VERSION ""

NS_ :

BS_:

BU_:

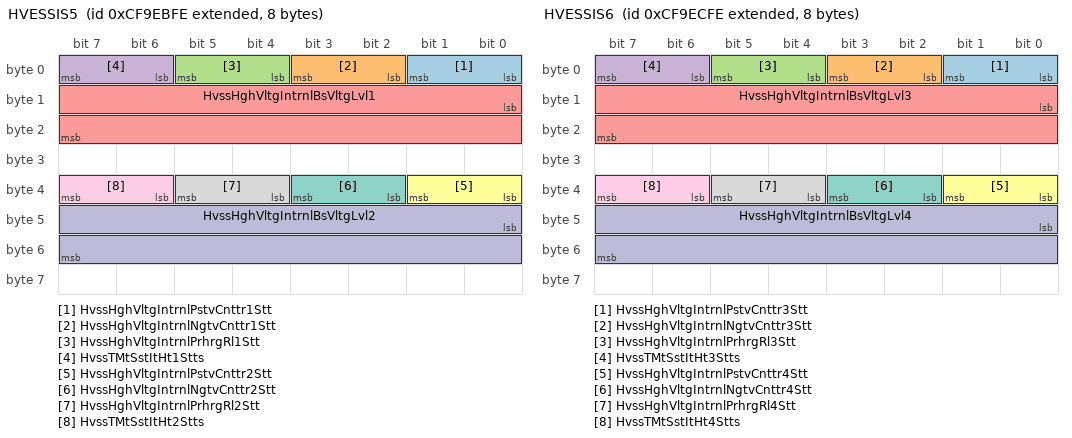
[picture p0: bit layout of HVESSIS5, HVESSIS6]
BO_ 2365189118 HVESSIS5: 8 Vector__XXX
 SG_ HvssHghVltgIntrnlPstvCnttr1Stt : 0|2@1+ (1,0) [0|3] "" Vector__XXX
 SG_ HvssHghVltgIntrnlNgtvCnttr1Stt : 2|2@1+ (1,0) [0|3] "" Vector__XXX
 SG_ HvssHghVltgIntrnlPrhrgRl1Stt : 4|2@1+ (1,0) [0|3] "" Vector__XXX
 SG_ HvssTMtSstItHt1Stts : 6|2@1+ (1,0) [0|3] "" Vector__XXX
 SG_ HvssHghVltgIntrnlBsVltgLvl1 : 8|16@1+ (0.05,0) [0|3212.75] "V" Vector__XXX
 SG_ HvssHghVltgIntrnlPstvCnttr2Stt : 32|2@1+ (1,0) [0|3] "" Vector__XXX
 SG_ HvssHghVltgIntrnlNgtvCnttr2Stt : 34|2@1+ (1,0) [0|3] "" Vector__XXX
 SG_ HvssHghVltgIntrnlPrhrgRl2Stt : 36|2@1+ (1,0) [0|3] "" Vector__XXX
 SG_ HvssTMtSstItHt2Stts : 38|2@1+ (1,0) [0|3] "" Vector__XXX
 SG_ HvssHghVltgIntrnlBsVltgLvl2 : 40|16@1+ (0.05,0) [0|3212.75] "V" Vector__XXX

BO_ 2365189374 HVESSIS6: 8 Vector__XXX
 SG_ HvssHghVltgIntrnlPstvCnttr3Stt : 0|2@1+ (1,0) [0|3] "" Vector__XXX
 SG_ HvssHghVltgIntrnlNgtvCnttr3Stt : 2|2@1+ (1,0) [0|3] "" Vector__XXX
 SG_ HvssHghVltgIntrnlPrhrgRl3Stt : 4|2@1+ (1,0) [0|3] "" Vector__XXX
 SG_ HvssTMtSstItHt3Stts : 6|2@1+ (1,0) [0|3] "" Vector__XXX
 SG_ HvssHghVltgIntrnlBsVltgLvl3 : 8|16@1+ (0.05,0) [0|3212.75] "V" Vector__XXX
 SG_ HvssHghVltgIntrnlPstvCnttr4Stt : 32|2@1+ (1,0) [0|3] "" Vector__XXX
 SG_ HvssHghVltgIntrnlNgtvCnttr4Stt : 34|2@1+ (1,0) [0|3] "" Vector__XXX
 SG_ HvssHghVltgIntrnlPrhrgRl4Stt : 36|2@1+ (1,0) [0|3] "" Vector__XXX
 SG_ HvssTMtSstItHt4Stts : 38|2@1+ (1,0) [0|3] "" Vector__XXX
 SG_ HvssHghVltgIntrnlBsVltgLvl4 : 40|16@1+ (0.05,0) [0|3212.75] "V" Vector__XXX

BO_ 2365189630 HVESSIS7: 8 Vector__XXX
 SG_ HvssNmrOfIntrnlCrtsRd : 0|8@1+ (1,0) [0|250] "count" Vector__XXX

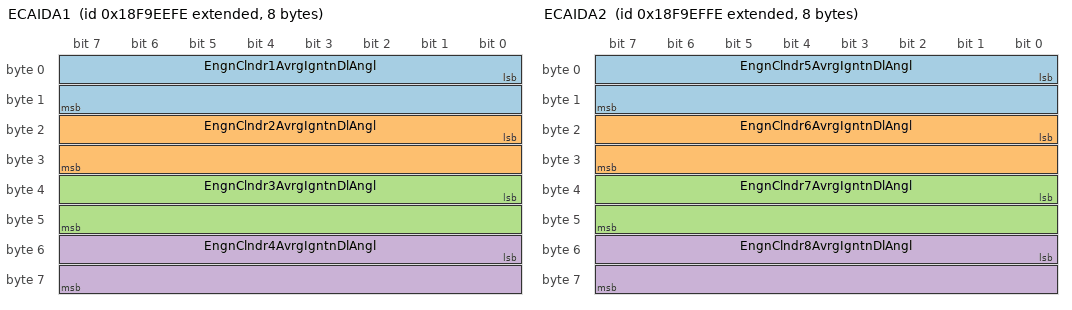
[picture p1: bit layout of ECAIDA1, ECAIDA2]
BO_ 2566516478 ECAIDA1: 8 Vector__XXX
 SG_ EngnClndr1AvrgIgntnDlAngl : 0|16@1+ (0.0078125,-200) [-200|301.9921875] "deg" Vector__XXX
 SG_ EngnClndr2AvrgIgntnDlAngl : 16|16@1+ (0.0078125,-200) [-200|301.9921875] "deg" Vector__XXX
 SG_ EngnClndr3AvrgIgntnDlAngl : 32|16@1+ (0.0078125,-200) [-200|301.9921875] "deg" Vector__XXX
 SG_ EngnClndr4AvrgIgntnDlAngl : 48|16@1+ (0.0078125,-200) [-200|301.9921875] "deg" Vector__XXX

BO_ 2566516734 ECAIDA2: 8 Vector__XXX
 SG_ EngnClndr5AvrgIgntnDlAngl : 0|16@1+ (0.0078125,-200) [-200|301.9921875] "deg" Vector__XXX
 SG_ EngnClndr6AvrgIgntnDlAngl : 16|16@1+ (0.0078125,-200) [-200|301.9921875] "deg" Vector__XXX
 SG_ EngnClndr7AvrgIgntnDlAngl : 32|16@1+ (0.0078125,-200) [-200|301.9921875] "deg" Vector__XXX
 SG_ EngnClndr8AvrgIgntnDlAngl : 48|16@1+ (0.0078125,-200) [-200|301.9921875] "deg" Vector__XXX

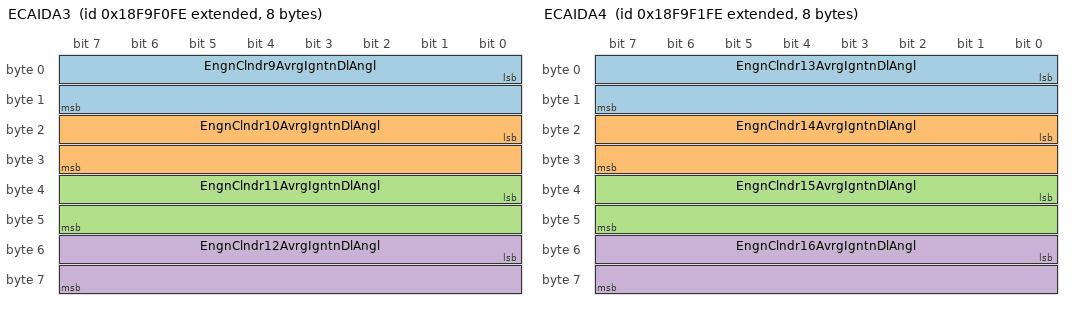
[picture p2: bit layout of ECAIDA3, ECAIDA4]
BO_ 2566516990 ECAIDA3: 8 Vector__XXX
 SG_ EngnClndr9AvrgIgntnDlAngl : 0|16@1+ (0.0078125,-200) [-200|301.9921875] "deg" Vector__XXX
 SG_ EngnClndr10AvrgIgntnDlAngl : 16|16@1+ (0.0078125,-200) [-200|301.9921875] "deg" Vector__XXX
 SG_ EngnClndr11AvrgIgntnDlAngl : 32|16@1+ (0.0078125,-200) [-200|301.9921875] "deg" Vector__XXX
 SG_ EngnClndr12AvrgIgntnDlAngl : 48|16@1+ (0.0078125,-200) [-200|301.9921875] "deg" Vector__XXX

BO_ 2566517246 ECAIDA4: 8 Vector__XXX
 SG_ EngnClndr13AvrgIgntnDlAngl : 0|16@1+ (0.0078125,-200) [-200|301.9921875] "deg" Vector__XXX
 SG_ EngnClndr14AvrgIgntnDlAngl : 16|16@1+ (0.0078125,-200) [-200|301.9921875] "deg" Vector__XXX
 SG_ EngnClndr15AvrgIgntnDlAngl : 32|16@1+ (0.0078125,-200) [-200|301.9921875] "deg" Vector__XXX
 SG_ EngnClndr16AvrgIgntnDlAngl : 48|16@1+ (0.0078125,-200) [-200|301.9921875] "deg" Vector__XXX

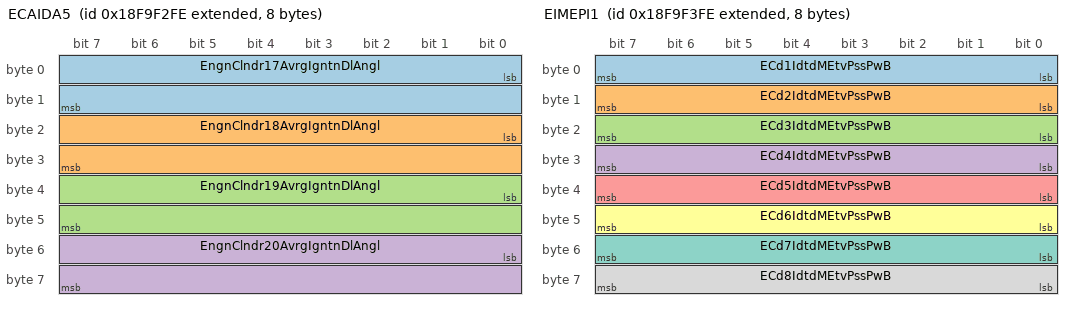
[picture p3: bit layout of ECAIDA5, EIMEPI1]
BO_ 2566517502 ECAIDA5: 8 Vector__XXX
 SG_ EngnClndr17AvrgIgntnDlAngl : 0|16@1+ (0.0078125,-200) [-200|301.9921875] "deg" Vector__XXX
 SG_ EngnClndr18AvrgIgntnDlAngl : 16|16@1+ (0.0078125,-200) [-200|301.9921875] "deg" Vector__XXX
 SG_ EngnClndr19AvrgIgntnDlAngl : 32|16@1+ (0.0078125,-200) [-200|301.9921875] "deg" Vector__XXX
 SG_ EngnClndr20AvrgIgntnDlAngl : 48|16@1+ (0.0078125,-200) [-200|301.9921875] "deg" Vector__XXX

BO_ 2566517758 EIMEPI1: 8 Vector__XXX
 SG_ ECd1IdtdMEtvPssPwB : 0|8@1+ (1,0) [0|250] "%" Vector__XXX
 SG_ ECd2IdtdMEtvPssPwB : 8|8@1+ (1,0) [0|250] "%" Vector__XXX
 SG_ ECd3IdtdMEtvPssPwB : 16|8@1+ (1,0) [0|250] "%" Vector__XXX
 SG_ ECd4IdtdMEtvPssPwB : 24|8@1+ (1,0) [0|250] "%" Vector__XXX
 SG_ ECd5IdtdMEtvPssPwB : 32|8@1+ (1,0) [0|250] "%" Vector__XXX
 SG_ ECd6IdtdMEtvPssPwB : 40|8@1+ (1,0) [0|250] "%" Vector__XXX
 SG_ ECd7IdtdMEtvPssPwB : 48|8@1+ (1,0) [0|250] "%" Vector__XXX
 SG_ ECd8IdtdMEtvPssPwB : 56|8@1+ (1,0) [0|250] "%" Vector__XXX

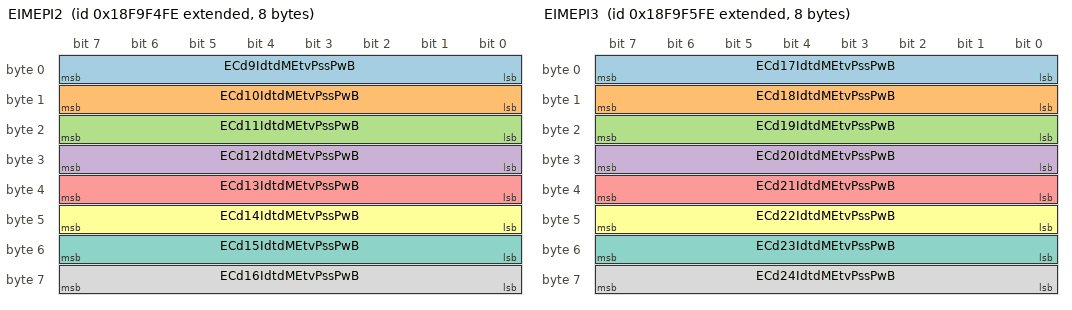
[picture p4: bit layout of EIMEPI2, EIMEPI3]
BO_ 2566518014 EIMEPI2: 8 Vector__XXX
 SG_ ECd9IdtdMEtvPssPwB : 0|8@1+ (1,0) [0|250] "%" Vector__XXX
 SG_ ECd10IdtdMEtvPssPwB : 8|8@1+ (1,0) [0|250] "%" Vector__XXX
 SG_ ECd11IdtdMEtvPssPwB : 16|8@1+ (1,0) [0|250] "%" Vector__XXX
 SG_ ECd12IdtdMEtvPssPwB : 24|8@1+ (1,0) [0|250] "%" Vector__XXX
 SG_ ECd13IdtdMEtvPssPwB : 32|8@1+ (1,0) [0|250] "%" Vector__XXX
 SG_ ECd14IdtdMEtvPssPwB : 40|8@1+ (1,0) [0|250] "%" Vector__XXX
 SG_ ECd15IdtdMEtvPssPwB : 48|8@1+ (1,0) [0|250] "%" Vector__XXX
 SG_ ECd16IdtdMEtvPssPwB : 56|8@1+ (1,0) [0|250] "%" Vector__XXX

BO_ 2566518270 EIMEPI3: 8 Vector__XXX
 SG_ ECd17IdtdMEtvPssPwB : 0|8@1+ (1,0) [0|250] "%" Vector__XXX
 SG_ ECd18IdtdMEtvPssPwB : 8|8@1+ (1,0) [0|250] "%" Vector__XXX
 SG_ ECd19IdtdMEtvPssPwB : 16|8@1+ (1,0) [0|250] "%" Vector__XXX
 SG_ ECd20IdtdMEtvPssPwB : 24|8@1+ (1,0) [0|250] "%" Vector__XXX
 SG_ ECd21IdtdMEtvPssPwB : 32|8@1+ (1,0) [0|250] "%" Vector__XXX
 SG_ ECd22IdtdMEtvPssPwB : 40|8@1+ (1,0) [0|250] "%" Vector__XXX
 SG_ ECd23IdtdMEtvPssPwB : 48|8@1+ (1,0) [0|250] "%" Vector__XXX
 SG_ ECd24IdtdMEtvPssPwB : 56|8@1+ (1,0) [0|250] "%" Vector__XXX

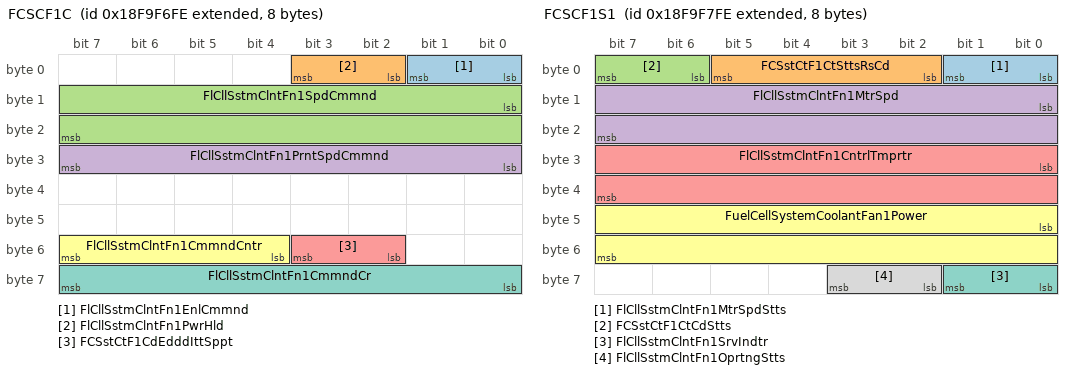
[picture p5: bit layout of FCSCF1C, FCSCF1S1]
BO_ 2566518526 FCSCF1C: 8 Vector__XXX
 SG_ FlCllSstmClntFn1EnlCmmnd : 0|2@1+ (1,0) [0|3] "" Vector__XXX
 SG_ FlCllSstmClntFn1PwrHld : 2|2@1+ (1,0) [0|3] "" Vector__XXX
 SG_ FlCllSstmClntFn1SpdCmmnd : 8|16@1+ (0.5,0) [0|32127.5] "rpm" Vector__XXX
 SG_ FlCllSstmClntFn1PrntSpdCmmnd : 24|8@1+ (0.5,0) [0|100] "%" Vector__XXX
 SG_ FCSstCtF1CdEdddIttSppt : 50|2@1+ (1,0) [0|3] "" Vector__XXX
 SG_ FlCllSstmClntFn1CmmndCntr : 52|4@1+ (1,0) [0|15] "count" Vector__XXX
 SG_ FlCllSstmClntFn1CmmndCr : 56|8@1+ (1,0) [0|250] "count" Vector__XXX

BO_ 2566518782 FCSCF1S1: 8 Vector__XXX
 SG_ FlCllSstmClntFn1MtrSpdStts : 0|2@1+ (1,0) [0|3] "" Vector__XXX
 SG_ FCSstCtF1CtSttsRsCd : 2|4@1+ (1,0) [0|15] "" Vector__XXX
 SG_ FCSstCtF1CtCdStts : 6|2@1+ (1,0) [0|3] "" Vector__XXX
 SG_ FlCllSstmClntFn1MtrSpd : 8|16@1+ (0.5,0) [0|32127.5] "rpm" Vector__XXX
 SG_ FlCllSstmClntFn1CntrlTmprtr : 24|16@1+ (0.03125,-273) [-273|1734.96875] "degC" Vector__XXX
 SG_ FuelCellSystemCoolantFan1Power : 40|16@1+ (0.5,0) [0|32127.5] "W" Vector__XXX
 SG_ FlCllSstmClntFn1SrvIndtr : 56|2@1+ (1,0) [0|3] "" Vector__XXX
 SG_ FlCllSstmClntFn1OprtngStts : 58|2@1+ (1,0) [0|3] "" Vector__XXX

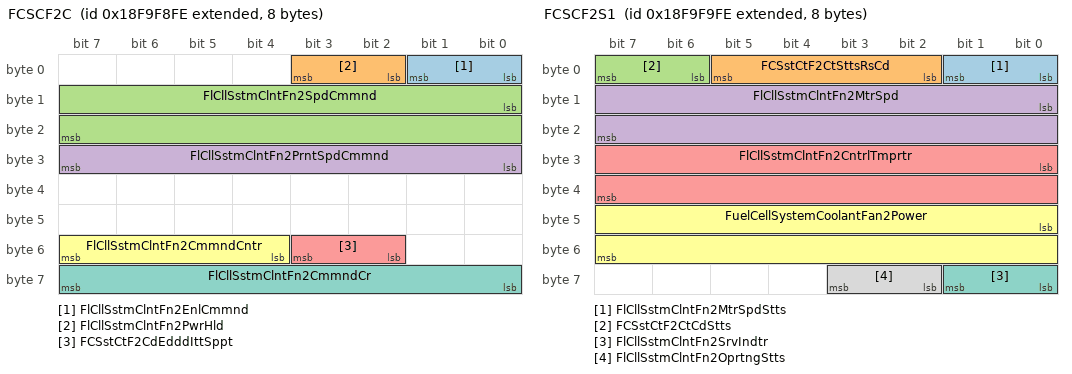
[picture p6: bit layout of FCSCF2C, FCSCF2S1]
BO_ 2566519038 FCSCF2C: 8 Vector__XXX
 SG_ FlCllSstmClntFn2EnlCmmnd : 0|2@1+ (1,0) [0|3] "" Vector__XXX
 SG_ FlCllSstmClntFn2PwrHld : 2|2@1+ (1,0) [0|3] "" Vector__XXX
 SG_ FlCllSstmClntFn2SpdCmmnd : 8|16@1+ (0.5,0) [0|32127.5] "rpm" Vector__XXX
 SG_ FlCllSstmClntFn2PrntSpdCmmnd : 24|8@1+ (0.5,0) [0|100] "%" Vector__XXX
 SG_ FCSstCtF2CdEdddIttSppt : 50|2@1+ (1,0) [0|3] "" Vector__XXX
 SG_ FlCllSstmClntFn2CmmndCntr : 52|4@1+ (1,0) [0|15] "count" Vector__XXX
 SG_ FlCllSstmClntFn2CmmndCr : 56|8@1+ (1,0) [0|250] "count" Vector__XXX

BO_ 2566519294 FCSCF2S1: 8 Vector__XXX
 SG_ FlCllSstmClntFn2MtrSpdStts : 0|2@1+ (1,0) [0|3] "" Vector__XXX
 SG_ FCSstCtF2CtSttsRsCd : 2|4@1+ (1,0) [0|15] "" Vector__XXX
 SG_ FCSstCtF2CtCdStts : 6|2@1+ (1,0) [0|3] "" Vector__XXX
 SG_ FlCllSstmClntFn2MtrSpd : 8|16@1+ (0.5,0) [0|32127.5] "rpm" Vector__XXX
 SG_ FlCllSstmClntFn2CntrlTmprtr : 24|16@1+ (0.03125,-273) [-273|1734.96875] "degC" Vector__XXX
 SG_ FuelCellSystemCoolantFan2Power : 40|16@1+ (0.5,0) [0|32127.5] "W" Vector__XXX
 SG_ FlCllSstmClntFn2SrvIndtr : 56|2@1+ (1,0) [0|3] "" Vector__XXX
 SG_ FlCllSstmClntFn2OprtngStts : 58|2@1+ (1,0) [0|3] "" Vector__XXX

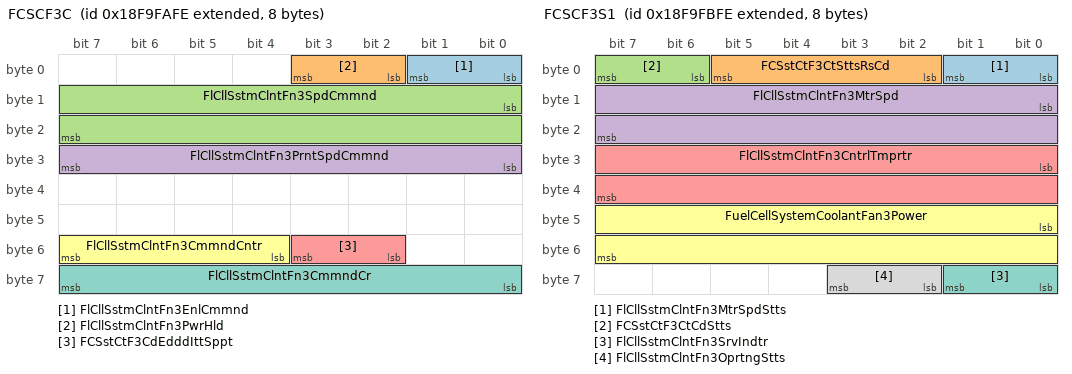
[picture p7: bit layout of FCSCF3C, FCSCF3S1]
BO_ 2566519550 FCSCF3C: 8 Vector__XXX
 SG_ FlCllSstmClntFn3EnlCmmnd : 0|2@1+ (1,0) [0|3] "" Vector__XXX
 SG_ FlCllSstmClntFn3PwrHld : 2|2@1+ (1,0) [0|3] "" Vector__XXX
 SG_ FlCllSstmClntFn3SpdCmmnd : 8|16@1+ (0.5,0) [0|32127.5] "rpm" Vector__XXX
 SG_ FlCllSstmClntFn3PrntSpdCmmnd : 24|8@1+ (0.5,0) [0|100] "%" Vector__XXX
 SG_ FCSstCtF3CdEdddIttSppt : 50|2@1+ (1,0) [0|3] "" Vector__XXX
 SG_ FlCllSstmClntFn3CmmndCntr : 52|4@1+ (1,0) [0|15] "count" Vector__XXX
 SG_ FlCllSstmClntFn3CmmndCr : 56|8@1+ (1,0) [0|250] "count" Vector__XXX

BO_ 2566519806 FCSCF3S1: 8 Vector__XXX
 SG_ FlCllSstmClntFn3MtrSpdStts : 0|2@1+ (1,0) [0|3] "" Vector__XXX
 SG_ FCSstCtF3CtSttsRsCd : 2|4@1+ (1,0) [0|15] "" Vector__XXX
 SG_ FCSstCtF3CtCdStts : 6|2@1+ (1,0) [0|3] "" Vector__XXX
 SG_ FlCllSstmClntFn3MtrSpd : 8|16@1+ (0.5,0) [0|32127.5] "rpm" Vector__XXX
 SG_ FlCllSstmClntFn3CntrlTmprtr : 24|16@1+ (0.03125,-273) [-273|1734.96875] "degC" Vector__XXX
 SG_ FuelCellSystemCoolantFan3Power : 40|16@1+ (0.5,0) [0|32127.5] "W" Vector__XXX
 SG_ FlCllSstmClntFn3SrvIndtr : 56|2@1+ (1,0) [0|3] "" Vector__XXX
 SG_ FlCllSstmClntFn3OprtngStts : 58|2@1+ (1,0) [0|3] "" Vector__XXX

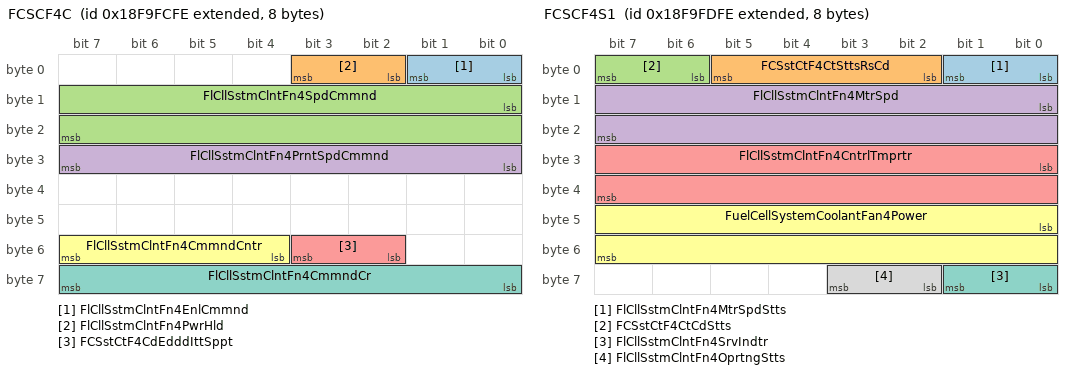
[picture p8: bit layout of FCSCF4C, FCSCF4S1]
BO_ 2566520062 FCSCF4C: 8 Vector__XXX
 SG_ FlCllSstmClntFn4EnlCmmnd : 0|2@1+ (1,0) [0|3] "" Vector__XXX
 SG_ FlCllSstmClntFn4PwrHld : 2|2@1+ (1,0) [0|3] "" Vector__XXX
 SG_ FlCllSstmClntFn4SpdCmmnd : 8|16@1+ (0.5,0) [0|32127.5] "rpm" Vector__XXX
 SG_ FlCllSstmClntFn4PrntSpdCmmnd : 24|8@1+ (0.5,0) [0|100] "%" Vector__XXX
 SG_ FCSstCtF4CdEdddIttSppt : 50|2@1+ (1,0) [0|3] "" Vector__XXX
 SG_ FlCllSstmClntFn4CmmndCntr : 52|4@1+ (1,0) [0|15] "count" Vector__XXX
 SG_ FlCllSstmClntFn4CmmndCr : 56|8@1+ (1,0) [0|250] "count" Vector__XXX

BO_ 2566520318 FCSCF4S1: 8 Vector__XXX
 SG_ FlCllSstmClntFn4MtrSpdStts : 0|2@1+ (1,0) [0|3] "" Vector__XXX
 SG_ FCSstCtF4CtSttsRsCd : 2|4@1+ (1,0) [0|15] "" Vector__XXX
 SG_ FCSstCtF4CtCdStts : 6|2@1+ (1,0) [0|3] "" Vector__XXX
 SG_ FlCllSstmClntFn4MtrSpd : 8|16@1+ (0.5,0) [0|32127.5] "rpm" Vector__XXX
 SG_ FlCllSstmClntFn4CntrlTmprtr : 24|16@1+ (0.03125,-273) [-273|1734.96875] "degC" Vector__XXX
 SG_ FuelCellSystemCoolantFan4Power : 40|16@1+ (0.5,0) [0|32127.5] "W" Vector__XXX
 SG_ FlCllSstmClntFn4SrvIndtr : 56|2@1+ (1,0) [0|3] "" Vector__XXX
 SG_ FlCllSstmClntFn4OprtngStts : 58|2@1+ (1,0) [0|3] "" Vector__XXX

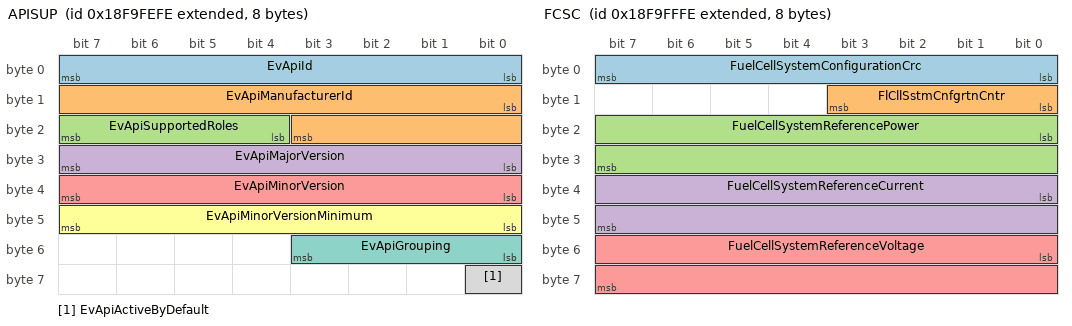
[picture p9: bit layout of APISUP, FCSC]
BO_ 2566520574 APISUP: 8 Vector__XXX
 SG_ EvApiId : 0|8@1+ (1,0) [0|250] "count" Vector__XXX
 SG_ EvApiManufacturerId : 8|12@1+ (1,0) [0|4015] "count" Vector__XXX
 SG_ EvApiSupportedRoles : 20|4@1+ (1,0) [0|15] "" Vector__XXX
 SG_ EvApiMajorVersion : 24|8@1+ (1,0) [0|250] "count" Vector__XXX
 SG_ EvApiMinorVersion : 32|8@1+ (1,0) [0|250] "count" Vector__XXX
 SG_ EvApiMinorVersionMinimum : 40|8@1+ (1,0) [0|250] "count" Vector__XXX
 SG_ EvApiGrouping : 48|4@1+ (1,0) [0|15] "" Vector__XXX
 SG_ EvApiActiveByDefault : 56|1@1+ (1,0) [0|1] "" Vector__XXX

BO_ 2566520830 FCSC: 8 Vector__XXX
 SG_ FuelCellSystemConfigurationCrc : 0|8@1+ (1,0) [0|250] "count" Vector__XXX
 SG_ FlCllSstmCnfgrtnCntr : 8|4@1+ (1,0) [0|15] "" Vector__XXX
 SG_ FuelCellSystemReferencePower : 16|16@1+ (0.05,0) [0|3212.75] "kW" Vector__XXX
 SG_ FuelCellSystemReferenceCurrent : 32|16@1+ (0.05,0) [0|3212.75] "A" Vector__XXX
 SG_ FuelCellSystemReferenceVoltage : 48|16@1+ (0.05,0) [0|3212.75] "V" Vector__XXX

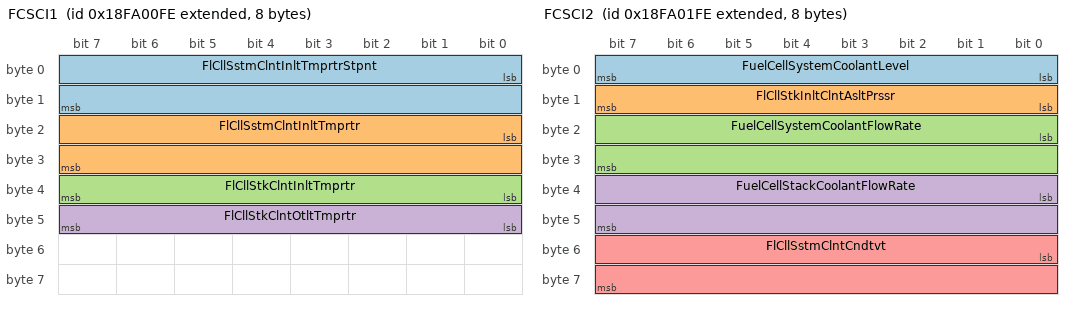
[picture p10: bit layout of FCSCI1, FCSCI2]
BO_ 2566521086 FCSCI1: 8 Vector__XXX
 SG_ FlCllSstmClntInltTmprtrStpnt : 0|16@1+ (0.03125,-273) [-273|1734.96875] "degC" Vector__XXX
 SG_ FlCllSstmClntInltTmprtr : 16|16@1+ (0.03125,-273) [-273|1734.96875] "degC" Vector__XXX
 SG_ FlCllStkClntInltTmprtr : 32|8@1+ (1,-40) [-40|210] "degC" Vector__XXX
 SG_ FlCllStkClntOtltTmprtr : 40|8@1+ (1,-40) [-40|210] "degC" Vector__XXX

BO_ 2566521342 FCSCI2: 8 Vector__XXX
 SG_ FuelCellSystemCoolantLevel : 0|8@1+ (0.4,0) [0|100] "%" Vector__XXX
 SG_ FlCllStkInltClntAsltPrssr : 8|8@1+ (2,0) [0|500] "kPa" Vector__XXX
 SG_ FuelCellSystemCoolantFlowRate : 16|16@1+ (0.05,0) [0|3212.75] "l/h" Vector__XXX
 SG_ FuelCellStackCoolantFlowRate : 32|16@1+ (0.05,0) [0|3212.75] "l/h" Vector__XXX
 SG_ FlCllSstmClntCndtvt : 48|16@1+ (0.02,0) [0|1285.1] "micro Siemens/cm" Vector__XXX

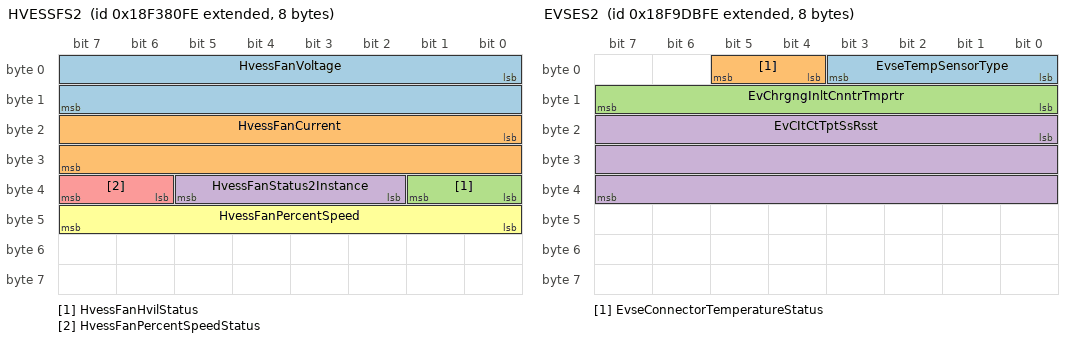
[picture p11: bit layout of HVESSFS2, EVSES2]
BO_ 2566095102 HVESSFS2: 8 Vector__XXX
 SG_ HvessFanVoltage : 0|16@1+ (0.05,0) [0|3212.75] "V" Vector__XXX
 SG_ HvessFanCurrent : 16|16@1+ (0.05,-1600) [-1600|1612.75] "A" Vector__XXX
 SG_ HvessFanHvilStatus : 32|2@1+ (1,0) [0|3] "" Vector__XXX
 SG_ HvessFanStatus2Instance : 34|4@1+ (1,0) [0|15] "" Vector__XXX
 SG_ HvessFanPercentSpeedStatus : 38|2@1+ (1,0) [0|3] "" Vector__XXX
 SG_ HvessFanPercentSpeed : 40|8@1+ (0.5,0) [0|125] "%" Vector__XXX

BO_ 2566511614 EVSES2: 8 Vector__XXX
 SG_ EvseTempSensorType : 0|4@1+ (1,0) [0|15] "" Vector__XXX
 SG_ EvseConnectorTemperatureStatus : 4|2@1+ (1,0) [0|3] "" Vector__XXX
 SG_ EvChrgngInltCnntrTmprtr : 8|8@1+ (1,-40) [-40|210] "degC" Vector__XXX
 SG_ EvCItCtTptSsRsst : 16|24@1+ (1,0) [0|16449535] "ohm" Vector__XXX

BO_ 2566645502 HVESSFC: 8 Vector__XXX
 SG_ HvessFanEnableCommand : 0|2@1+ (1,0) [0|3] "" Vector__XXX
 SG_ HvessFanPowerHold : 2|2@1+ (1,0) [0|3] "" Vector__XXX
 SG_ HvessFanSpeedCommand : 8|16@1+ (0.5,0) [0|32127.5] "rpm" Vector__XXX
 SG_ HvessFanPercentSpeedCommand : 24|8@1+ (0.4,0) [0|100] "%" Vector__XXX
 SG_ HvessFanInstance1 : 32|1@1+ (1,0) [0|1] "" Vector__XXX
 SG_ HvessFanInstance2 : 33|1@1+ (1,0) [0|1] "" Vector__XXX
 SG_ HvessFanInstance3 : 34|1@1+ (1,0) [0|1] "" Vector__XXX
 SG_ HvessFanInstance4 : 35|1@1+ (1,0) [0|1] "" Vector__XXX
 SG_ HvessFanInstance5 : 36|1@1+ (1,0) [0|1] "" Vector__XXX
 SG_ HvessFanInstance6 : 37|1@1+ (1,0) [0|1] "" Vector__XXX
 SG_ HvessFanInstance7 : 38|1@1+ (1,0) [0|1] "" Vector__XXX
 SG_ HvessFanInstance8 : 39|1@1+ (1,0) [0|1] "" Vector__XXX
 SG_ HvessFanInstance9 : 40|1@1+ (1,0) [0|1] "" Vector__XXX
 SG_ HvessFanInstance10 : 41|1@1+ (1,0) [0|1] "" Vector__XXX
 SG_ HvessFanInstance11 : 42|1@1+ (1,0) [0|1] "" Vector__XXX
 SG_ HvessFanInstance12 : 43|1@1+ (1,0) [0|1] "" Vector__XXX
 SG_ HvessFanInstance13 : 44|1@1+ (1,0) [0|1] "" Vector__XXX
 SG_ HvessFanInstance14 : 45|1@1+ (1,0) [0|1] "" Vector__XXX
 SG_ HvessFanInstance15 : 46|1@1+ (1,0) [0|1] "" Vector__XXX
 SG_ HVtEStSstFCdsEdddIttSppt : 50|2@1+ (1,0) [0|3] "" Vector__XXX
 SG_ HghVltgEnrgStrgSstmFnCmmndsCntr : 52|4@1+ (1,0) [0|15] "count" Vector__XXX
 SG_ HghVltgEnrgStrgSstmFnCmmndsCr : 56|8@1+ (1,0) [0|250] "count" Vector__XXX

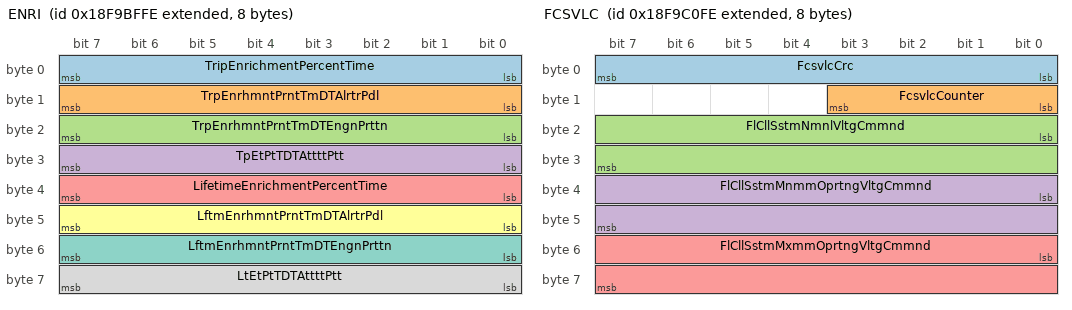
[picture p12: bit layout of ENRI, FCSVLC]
BO_ 2566504446 ENRI: 8 Vector__XXX
 SG_ TripEnrichmentPercentTime : 0|8@1+ (0.5,0) [0|125] "%" Vector__XXX
 SG_ TrpEnrhmntPrntTmDTAlrtrPdl : 8|8@1+ (0.5,0) [0|125] "%" Vector__XXX
 SG_ TrpEnrhmntPrntTmDTEngnPrttn : 16|8@1+ (0.5,0) [0|125] "%" Vector__XXX
 SG_ TpEtPtTDTAttttPtt : 24|8@1+ (0.5,0) [0|125] "%" Vector__XXX
 SG_ LifetimeEnrichmentPercentTime : 32|8@1+ (0.5,0) [0|125] "%" Vector__XXX
 SG_ LftmEnrhmntPrntTmDTAlrtrPdl : 40|8@1+ (0.5,0) [0|125] "%" Vector__XXX
 SG_ LftmEnrhmntPrntTmDTEngnPrttn : 48|8@1+ (0.5,0) [0|125] "%" Vector__XXX
 SG_ LtEtPtTDTAttttPtt : 56|8@1+ (0.5,0) [0|125] "%" Vector__XXX

BO_ 2566504702 FCSVLC: 8 Vector__XXX
 SG_ FcsvlcCrc : 0|8@1+ (1,0) [0|250] "count" Vector__XXX
 SG_ FcsvlcCounter : 8|4@1+ (1,0) [0|15] "" Vector__XXX
 SG_ FlCllSstmNmnlVltgCmmnd : 16|16@1+ (0.00390625,-125) [0|125.99609375] "%" Vector__XXX
 SG_ FlCllSstmMnmmOprtngVltgCmmnd : 32|16@1+ (0.00390625,-125) [0|125.99609375] "%" Vector__XXX
 SG_ FlCllSstmMxmmOprtngVltgCmmnd : 48|16@1+ (0.00390625,-125) [0|125.99609375] "%" Vector__XXX

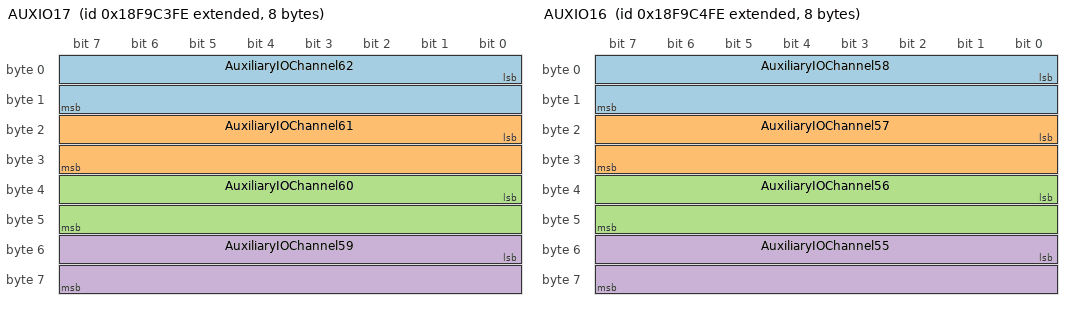
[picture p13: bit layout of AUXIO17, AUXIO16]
BO_ 2566505470 AUXIO17: 8 Vector__XXX
 SG_ AuxiliaryIOChannel62 : 0|16@1+ (1,0) [0|64255] "count" Vector__XXX
 SG_ AuxiliaryIOChannel61 : 16|16@1+ (1,0) [0|64255] "count" Vector__XXX
 SG_ AuxiliaryIOChannel60 : 32|16@1+ (1,0) [0|64255] "count" Vector__XXX
 SG_ AuxiliaryIOChannel59 : 48|16@1+ (1,0) [0|64255] "count" Vector__XXX

BO_ 2566505726 AUXIO16: 8 Vector__XXX
 SG_ AuxiliaryIOChannel58 : 0|16@1+ (1,0) [0|64255] "count" Vector__XXX
 SG_ AuxiliaryIOChannel57 : 16|16@1+ (1,0) [0|64255] "count" Vector__XXX
 SG_ AuxiliaryIOChannel56 : 32|16@1+ (1,0) [0|64255] "count" Vector__XXX
 SG_ AuxiliaryIOChannel55 : 48|16@1+ (1,0) [0|64255] "count" Vector__XXX

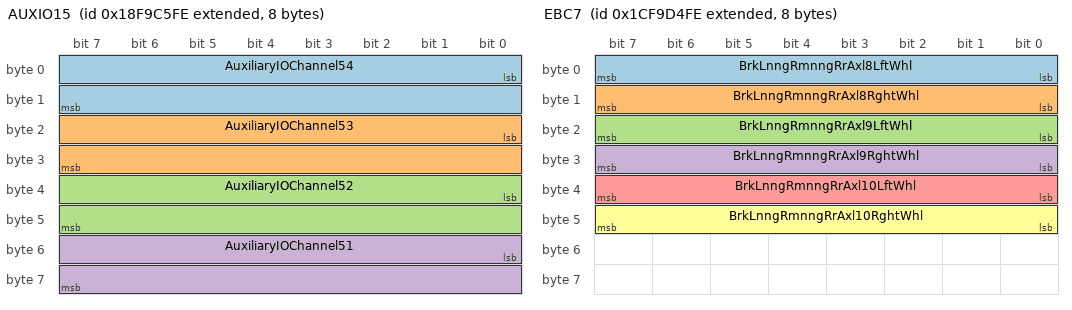
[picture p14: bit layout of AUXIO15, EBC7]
BO_ 2566505982 AUXIO15: 8 Vector__XXX
 SG_ AuxiliaryIOChannel54 : 0|16@1+ (1,0) [0|64255] "count" Vector__XXX
 SG_ AuxiliaryIOChannel53 : 16|16@1+ (1,0) [0|64255] "count" Vector__XXX
 SG_ AuxiliaryIOChannel52 : 32|16@1+ (1,0) [0|64255] "count" Vector__XXX
 SG_ AuxiliaryIOChannel51 : 48|16@1+ (1,0) [0|64255] "count" Vector__XXX

BO_ 2566506238 AUXIO14: 8 Vector__XXX
 SG_ AuxiliaryIOChannel50 : 0|16@1+ (1,0) [0|64255] "count" Vector__XXX
 SG_ AuxiliaryIOChannel49 : 16|16@1+ (1,0) [0|64255] "count" Vector__XXX
 SG_ AuxiliaryIOChannel48 : 32|16@1+ (1,0) [0|64255] "count" Vector__XXX
 SG_ AuxiliaryIOChannel47 : 48|16@1+ (1,0) [0|64255] "count" Vector__XXX

BO_ 2566506494 AUXIO13: 8 Vector__XXX
 SG_ AuxiliaryIOChannel46 : 0|16@1+ (1,0) [0|64255] "count" Vector__XXX
 SG_ AuxiliaryIOChannel45 : 16|16@1+ (1,0) [0|64255] "count" Vector__XXX
 SG_ AuxiliaryIOChannel44 : 32|16@1+ (1,0) [0|64255] "count" Vector__XXX
 SG_ AuxiliaryIOChannel43 : 48|16@1+ (1,0) [0|64255] "count" Vector__XXX

BO_ 2566506750 AUXIO12: 8 Vector__XXX
 SG_ AuxiliaryIOChannel42 : 0|16@1+ (1,0) [0|64255] "count" Vector__XXX
 SG_ AuxiliaryIOChannel41 : 16|16@1+ (1,0) [0|64255] "count" Vector__XXX
 SG_ AuxiliaryIOChannel40 : 32|16@1+ (1,0) [0|64255] "count" Vector__XXX
 SG_ AuxiliaryIOChannel39 : 48|16@1+ (1,0) [0|64255] "count" Vector__XXX

BO_ 2566507006 AUXIO11: 8 Vector__XXX
 SG_ AuxiliaryIOChannel38 : 0|16@1+ (1,0) [0|64255] "count" Vector__XXX
 SG_ AuxiliaryIOChannel37 : 16|16@1+ (1,0) [0|64255] "count" Vector__XXX
 SG_ AuxiliaryIOChannel36 : 32|16@1+ (1,0) [0|64255] "count" Vector__XXX
 SG_ AuxiliaryIOChannel35 : 48|16@1+ (1,0) [0|64255] "count" Vector__XXX

BO_ 2566507262 AUXIO10: 8 Vector__XXX
 SG_ AuxiliaryIOChannel34 : 0|16@1+ (1,0) [0|64255] "count" Vector__XXX
 SG_ AuxiliaryIOChannel33 : 16|16@1+ (1,0) [0|64255] "count" Vector__XXX
 SG_ AuxiliaryIOChannel32 : 32|16@1+ (1,0) [0|64255] "count" Vector__XXX
 SG_ AuxiliaryIOChannel31 : 48|16@1+ (1,0) [0|64255] "count" Vector__XXX

BO_ 2566507518 AUXIO9: 8 Vector__XXX
 SG_ AuxiliaryIOChannel30 : 0|16@1+ (1,0) [0|64255] "count" Vector__XXX
 SG_ AuxiliaryIOChannel29 : 16|16@1+ (1,0) [0|64255] "count" Vector__XXX
 SG_ AuxiliaryIOChannel28 : 32|16@1+ (1,0) [0|64255] "count" Vector__XXX
 SG_ AuxiliaryIOChannel27 : 48|16@1+ (1,0) [0|64255] "count" Vector__XXX

BO_ 2566507774 AUXIO8: 8 Vector__XXX
 SG_ AuxiliaryIOChannel26 : 0|16@1+ (1,0) [0|64255] "count" Vector__XXX
 SG_ AuxiliaryIOChannel25 : 16|16@1+ (1,0) [0|64255] "count" Vector__XXX
 SG_ AuxiliaryIOChannel24 : 32|16@1+ (1,0) [0|64255] "count" Vector__XXX
 SG_ AuxiliaryIOChannel23 : 48|16@1+ (1,0) [0|64255] "count" Vector__XXX

BO_ 2633616894 ASI8: 8 Vector__XXX
 SG_ AftrtrtmntDslExhstFldEnm : 0|16@1+ (0.015625,0) [0|1003.984375] "km/L" Vector__XXX
 SG_ AftrtrtmntDslExhstFldLftmEnm : 16|16@1+ (0.015625,0) [0|1003.984375] "km/L" Vector__XXX

BO_ 2566508286 BKT6: 8 Vector__XXX
 SG_ BrkTmprtrRrAxl10LftWhl : 0|16@1+ (0.03125,-273) [-273|1734.96875] "degC" Vector__XXX
 SG_ BrkTmprtrRrAxl10RghtWhl : 16|16@1+ (0.03125,-273) [-273|1734.96875] "degC" Vector__XXX

BO_ 2566508542 BKT5: 8 Vector__XXX
 SG_ BrkTmprtrRrAxl8LftWhl : 0|16@1+ (0.03125,-273) [-273|1734.96875] "degC" Vector__XXX
 SG_ BrkTmprtrRrAxl8RghtWhl : 16|16@1+ (0.03125,-273) [-273|1734.96875] "degC" Vector__XXX
 SG_ BrkTmprtrRrAxl9LftWhl : 32|16@1+ (0.03125,-273) [-273|1734.96875] "degC" Vector__XXX
 SG_ BrkTmprtrRrAxl9RghtWhl : 48|16@1+ (0.03125,-273) [-273|1734.96875] "degC" Vector__XXX

BO_ 2566508798 BKT4: 8 Vector__XXX
 SG_ BrkTmprtrRrAxl6LftWhl : 0|16@1+ (0.03125,-273) [-273|1734.96875] "degC" Vector__XXX
 SG_ BrkTmprtrRrAxl6RghtWhl : 16|16@1+ (0.03125,-273) [-273|1734.96875] "degC" Vector__XXX
 SG_ BrkTmprtrRrAxl7LftWhl : 32|16@1+ (0.03125,-273) [-273|1734.96875] "degC" Vector__XXX
 SG_ BrkTmprtrRrAxl7RghtWhl : 48|16@1+ (0.03125,-273) [-273|1734.96875] "degC" Vector__XXX

BO_ 2566509054 BKT3: 8 Vector__XXX
 SG_ BrkTmprtrRrAxl4LftWhl : 0|16@1+ (0.03125,-273) [-273|1734.96875] "degC" Vector__XXX
 SG_ BrkTmprtrRrAxl4RghtWhl : 16|16@1+ (0.03125,-273) [-273|1734.96875] "degC" Vector__XXX
 SG_ BrkTmprtrRrAxl5LftWhl : 32|16@1+ (0.03125,-273) [-273|1734.96875] "degC" Vector__XXX
 SG_ BrkTmprtrRrAxl5RghtWhl : 48|16@1+ (0.03125,-273) [-273|1734.96875] "degC" Vector__XXX

BO_ 2566509310 BKT2: 8 Vector__XXX
 SG_ BrkTmprtrRrAxl2LftWhl : 0|16@1+ (0.03125,-273) [-273|1734.96875] "degC" Vector__XXX
 SG_ BrkTmprtrRrAxl2RghtWhl : 16|16@1+ (0.03125,-273) [-273|1734.96875] "degC" Vector__XXX
 SG_ BrkTmprtrRrAxl3LftWhl : 32|16@1+ (0.03125,-273) [-273|1734.96875] "degC" Vector__XXX
 SG_ BrkTmprtrRrAxl3RghtWhl : 48|16@1+ (0.03125,-273) [-273|1734.96875] "degC" Vector__XXX

BO_ 2566509566 BKT1: 8 Vector__XXX
 SG_ BrkTmprtrFrntAxlLftWhl : 0|16@1+ (0.03125,-273) [-273|1734.96875] "degC" Vector__XXX
 SG_ BrkTmprtrFrntAxlRghtWhl : 16|16@1+ (0.03125,-273) [-273|1734.96875] "degC" Vector__XXX
 SG_ BrkTmprtrRrAxl1LftWhl : 32|16@1+ (0.03125,-273) [-273|1734.96875] "degC" Vector__XXX
 SG_ BrkTmprtrRrAxl1RghtWhl : 48|16@1+ (0.03125,-273) [-273|1734.96875] "degC" Vector__XXX

BO_ 2633618686 EBC7: 8 Vector__XXX
 SG_ BrkLnngRmnngRrAxl8LftWhl : 0|8@1+ (0.4,0) [0|100] "%" Vector__XXX
 SG_ BrkLnngRmnngRrAxl8RghtWhl : 8|8@1+ (0.4,0) [0|100] "%" Vector__XXX
 SG_ BrkLnngRmnngRrAxl9LftWhl : 16|8@1+ (0.4,0) [0|100] "%" Vector__XXX
 SG_ BrkLnngRmnngRrAxl9RghtWhl : 24|8@1+ (0.4,0) [0|100] "%" Vector__XXX
 SG_ BrkLnngRmnngRrAxl10LftWhl : 32|8@1+ (0.4,0) [0|100] "%" Vector__XXX
 SG_ BrkLnngRmnngRrAxl10RghtWhl : 40|8@1+ (0.4,0) [0|100] "%" Vector__XXX

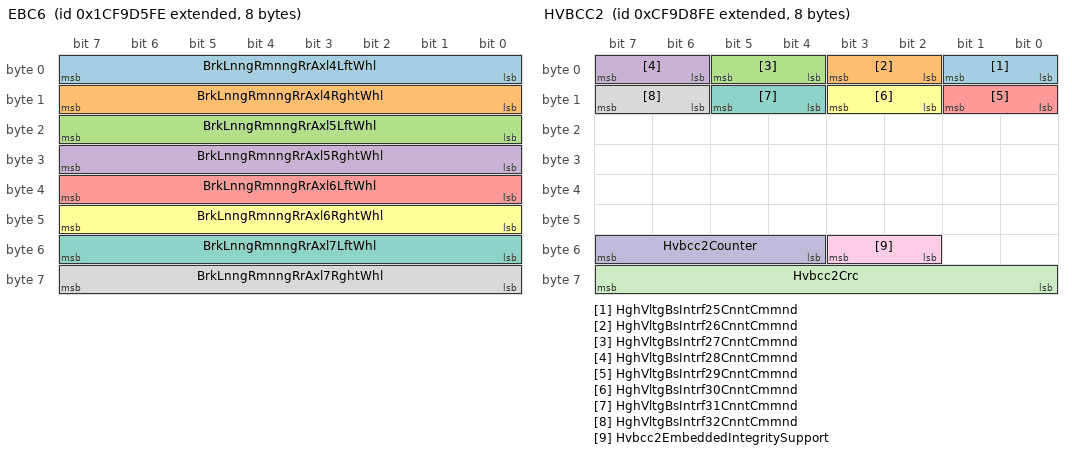
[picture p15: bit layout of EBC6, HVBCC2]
BO_ 2633618942 EBC6: 8 Vector__XXX
 SG_ BrkLnngRmnngRrAxl4LftWhl : 0|8@1+ (0.4,0) [0|100] "%" Vector__XXX
 SG_ BrkLnngRmnngRrAxl4RghtWhl : 8|8@1+ (0.4,0) [0|100] "%" Vector__XXX
 SG_ BrkLnngRmnngRrAxl5LftWhl : 16|8@1+ (0.4,0) [0|100] "%" Vector__XXX
 SG_ BrkLnngRmnngRrAxl5RghtWhl : 24|8@1+ (0.4,0) [0|100] "%" Vector__XXX
 SG_ BrkLnngRmnngRrAxl6LftWhl : 32|8@1+ (0.4,0) [0|100] "%" Vector__XXX
 SG_ BrkLnngRmnngRrAxl6RghtWhl : 40|8@1+ (0.4,0) [0|100] "%" Vector__XXX
 SG_ BrkLnngRmnngRrAxl7LftWhl : 48|8@1+ (0.4,0) [0|100] "%" Vector__XXX
 SG_ BrkLnngRmnngRrAxl7RghtWhl : 56|8@1+ (0.4,0) [0|100] "%" Vector__XXX

BO_ 2365183742 HVBCS3: 8 Vector__XXX
 SG_ Hvbcs3EmbeddedIntegritySupport : 50|2@1+ (1,0) [0|3] "" Vector__XXX
 SG_ Hvbcs3Counter : 52|4@1+ (1,0) [0|15] "" Vector__XXX
 SG_ Hvbcs3Crc : 56|8@1+ (1,0) [0|250] "count" Vector__XXX

BO_ 2365183998 HVBCS2: 8 Vector__XXX
 SG_ Hvbcs2EmbeddedIntegritySupport : 50|2@1+ (1,0) [0|3] "" Vector__XXX
 SG_ Hvbcs2Counter : 52|4@1+ (1,0) [0|15] "" Vector__XXX
 SG_ Hvbcs2Crc : 56|8@1+ (1,0) [0|250] "count" Vector__XXX

BO_ 2365184254 HVBCC2: 8 Vector__XXX
 SG_ HghVltgBsIntrf25CnntCmmnd : 0|2@1+ (1,0) [0|3] "" Vector__XXX
 SG_ HghVltgBsIntrf26CnntCmmnd : 2|2@1+ (1,0) [0|3] "" Vector__XXX
 SG_ HghVltgBsIntrf27CnntCmmnd : 4|2@1+ (1,0) [0|3] "" Vector__XXX
 SG_ HghVltgBsIntrf28CnntCmmnd : 6|2@1+ (1,0) [0|3] "" Vector__XXX
 SG_ HghVltgBsIntrf29CnntCmmnd : 8|2@1+ (1,0) [0|3] "" Vector__XXX
 SG_ HghVltgBsIntrf30CnntCmmnd : 10|2@1+ (1,0) [0|3] "" Vector__XXX
 SG_ HghVltgBsIntrf31CnntCmmnd : 12|2@1+ (1,0) [0|3] "" Vector__XXX
 SG_ HghVltgBsIntrf32CnntCmmnd : 14|2@1+ (1,0) [0|3] "" Vector__XXX
 SG_ Hvbcc2EmbeddedIntegritySupport : 50|2@1+ (1,0) [0|3] "" Vector__XXX
 SG_ Hvbcc2Counter : 52|4@1+ (1,0) [0|15] "" Vector__XXX
 SG_ Hvbcc2Crc : 56|8@1+ (1,0) [0|250] "count" Vector__XXX

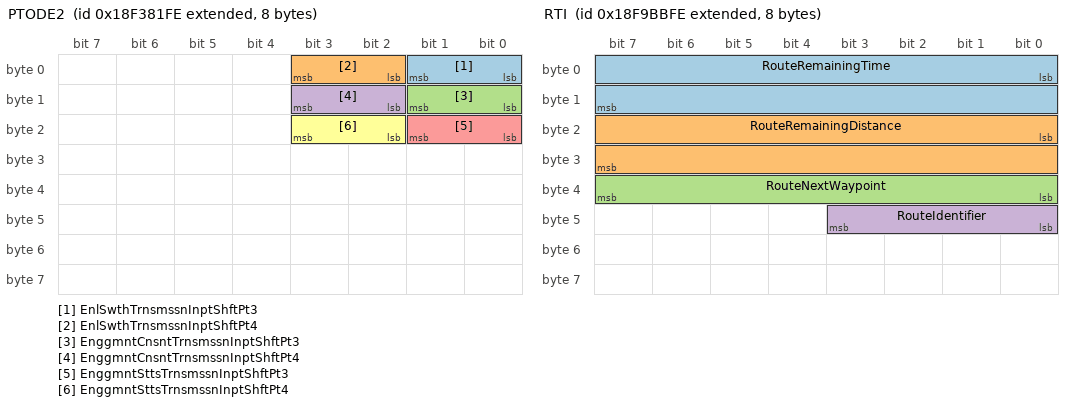
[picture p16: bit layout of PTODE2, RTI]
BO_ 2566095358 PTODE2: 8 Vector__XXX
 SG_ EnlSwthTrnsmssnInptShftPt3 : 0|2@1+ (1,0) [0|3] "" Vector__XXX
 SG_ EnlSwthTrnsmssnInptShftPt4 : 2|2@1+ (1,0) [0|3] "" Vector__XXX
 SG_ EnggmntCnsntTrnsmssnInptShftPt3 : 8|2@1+ (1,0) [0|3] "" Vector__XXX
 SG_ EnggmntCnsntTrnsmssnInptShftPt4 : 10|2@1+ (1,0) [0|3] "" Vector__XXX
 SG_ EnggmntSttsTrnsmssnInptShftPt3 : 16|2@1+ (1,0) [0|3] "" Vector__XXX
 SG_ EnggmntSttsTrnsmssnInptShftPt4 : 18|2@1+ (1,0) [0|3] "" Vector__XXX

BO_ 2364769022 FCSHP: 8 Vector__XXX
 SG_ FcshpCrc : 0|8@1+ (1,0) [0|250] "count" Vector__XXX
 SG_ FcshpCounter : 8|4@1+ (1,0) [0|15] "" Vector__XXX
 SG_ FlCllSstmHdrgnInltPrssr : 16|16@1+ (0.125,0) [0|8031.875] "kPa" Vector__XXX

BO_ 2566502142 WSP5: 8 Vector__XXX
 SG_ EstmtdWllStmltnPmpLOlFlwRt : 0|16@1+ (0.05,0) [0|3212.75] "l/h" Vector__XXX
 SG_ AtlWllStmltnPmpLOlFlwRt : 16|16@1+ (0.05,0) [0|3212.75] "l/h" Vector__XXX
 SG_ EstmtdWllStmltnPmpGrBxLOlFlwRt : 32|16@1+ (0.05,0) [0|3212.75] "l/h" Vector__XXX
 SG_ AtlWllStmltnPmpGrBxLOlFlwRt : 48|16@1+ (0.05,0) [0|3212.75] "l/h" Vector__XXX

BO_ 2566502398 WSP4: 8 Vector__XXX
 SG_ WellStimulationPumpOilPressure : 0|16@1+ (0.1,0) [0|6425.5] "kPa" Vector__XXX
 SG_ WllStmltnPmpOtltOlPrssr : 16|16@1+ (0.1,0) [0|6425.5] "kPa" Vector__XXX
 SG_ WllStmltnPmpOtltOlTmprtr : 32|8@1+ (1,-40) [-40|210] "degC" Vector__XXX

BO_ 2566502654 TI: 8 Vector__XXX
 SG_ TireRollingDistance : 0|16@1+ (0.05,0) [0|3212.75] "rev/km" Vector__XXX

BO_ 2566502910 H2SS: 8 Vector__XXX
 SG_ HydrogenRedLampData : 0|2@1+ (1,0) [0|3] "" Vector__XXX
 SG_ HydrogenYellowLampData : 2|2@1+ (1,0) [0|3] "" Vector__XXX

BO_ 2566503166 RWGPSC: 9 Vector__XXX
 SG_ RouteNumberOfWaypoints : 0|8@1+ (1,0) [0|250] "count" Vector__XXX
 SG_ RouteWaypointLatitude : 8|32@1+ (0.0000001,-210) [-210|211.1081215] "deg" Vector__XXX
 SG_ RouteWaypointLongitude : 40|32@1+ (0.0000001,-210) [-210|211.1081215] "deg" Vector__XXX

BO_ 2566503422 RTI: 8 Vector__XXX
 SG_ RouteRemainingTime : 0|16@1+ (1,0) [0|64255] "min" Vector__XXX
 SG_ RouteRemainingDistance : 16|16@1+ (0.25,0) [0|16063.75] "km" Vector__XXX
 SG_ RouteNextWaypoint : 32|8@1+ (1,0) [0|250] "count" Vector__XXX
 SG_ RouteIdentifier : 40|4@1+ (1,0) [0|13] "count" Vector__XXX

BO_ 2566503678 EFLP15: 8 Vector__XXX
 SG_ EngnCrnksBrthrOlSprtrIntkPrssr : 0|16@1+ (0.0078125,-100) [-100|401.9921875] "kPa" Vector__XXX

BO_ 2566503934 FCSCI3: 8 Vector__XXX
 SG_ FlCllSstmClntFlwRtExtnddRng : 0|16@1+ (0.5,0) [0|32127.5] "l/min" Vector__XXX
 SG_ FlCllStkClntFlwRtExtnddRng : 16|16@1+ (0.5,0) [0|32127.5] "l/min" Vector__XXX

BO_ 2566504190 TCFG3: 8 Vector__XXX
 SG_ TransmissionMode1Configuration : 0|2@1+ (1,0) [0|3] "" Vector__XXX
 SG_ TransmissionMode2Configuration : 2|2@1+ (1,0) [0|3] "" Vector__XXX
 SG_ TransmissionMode3Configuration : 4|2@1+ (1,0) [0|3] "" Vector__XXX
 SG_ TransmissionMode4Configuration : 6|2@1+ (1,0) [0|3] "" Vector__XXX
 SG_ TransmissionMode5Configuration : 8|2@1+ (1,0) [0|3] "" Vector__XXX
 SG_ TransmissionMode6Configuration : 10|2@1+ (1,0) [0|3] "" Vector__XXX
 SG_ TransmissionMode7Configuration : 12|2@1+ (1,0) [0|3] "" Vector__XXX
 SG_ TransmissionMode8Configuration : 14|2@1+ (1,0) [0|3] "" Vector__XXX
 SG_ TransmissionMode9Configuration : 16|2@1+ (1,0) [0|3] "" Vector__XXX
 SG_ TransmissionMode10Configuration : 18|2@1+ (1,0) [0|3] "" Vector__XXX
 SG_ TransmissionMode11Configuration : 20|2@1+ (1,0) [0|3] "" Vector__XXX
 SG_ TransmissionMode12Configuration : 22|2@1+ (1,0) [0|3] "" Vector__XXX
 SG_ TransmissionMode13Configuration : 24|2@1+ (1,0) [0|3] "" Vector__XXX
 SG_ TransmissionMode14Configuration : 26|2@1+ (1,0) [0|3] "" Vector__XXX
 SG_ TransmissionMode15Configuration : 28|2@1+ (1,0) [0|3] "" Vector__XXX
 SG_ TransmissionMode16Configuration : 30|2@1+ (1,0) [0|3] "" Vector__XXX
 SG_ TransmissionMode17Configuration : 32|2@1+ (1,0) [0|3] "" Vector__XXX
 SG_ TransmissionMode18Configuration : 34|2@1+ (1,0) [0|3] "" Vector__XXX
 SG_ TransmissionMode19Configuration : 36|2@1+ (1,0) [0|3] "" Vector__XXX
 SG_ TransmissionMode20Configuration : 38|2@1+ (1,0) [0|3] "" Vector__XXX

BO_ 2566505214 H2SYSINF: 8 Vector__XXX
 SG_ HydrogenRedLampCommand : 0|2@1+ (1,0) [0|3] "" Vector__XXX
 SG_ HydrogenYellowLampCommand : 2|2@1+ (1,0) [0|3] "" Vector__XXX

BO_ 2566095870 EGF2: 8 Vector__XXX
 SG_ EngnTrhrgr1CmprssrIntkFlwRt : 0|16@1+ (0.2,0) [0|12851] "kg/h" Vector__XXX
 SG_ EngnTrhrgr2CmprssrIntkFlwRt : 16|16@1+ (0.2,0) [0|12851] "kg/h" Vector__XXX
 SG_ EngnIntkArMssFlwRtExtnddRng : 32|16@1+ (0.2,0) [0|12851] "kg/h" Vector__XXX

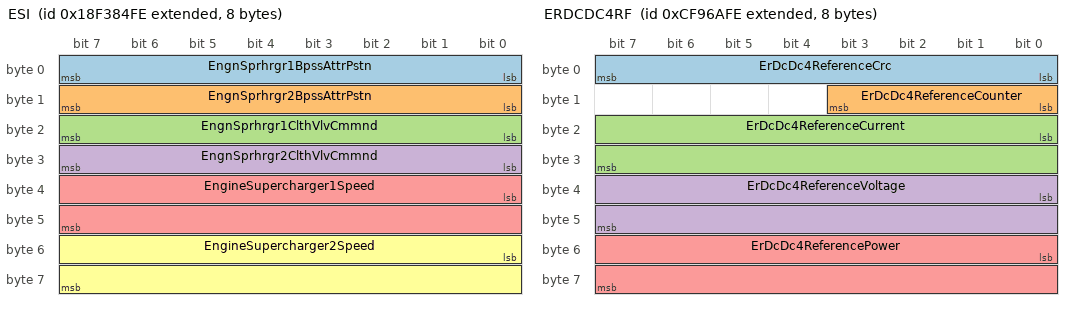
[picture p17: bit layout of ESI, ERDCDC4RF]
BO_ 2566096126 ESI: 8 Vector__XXX
 SG_ EngnSprhrgr1BpssAttrPstn : 0|8@1+ (0.4,0) [0|100] "%" Vector__XXX
 SG_ EngnSprhrgr2BpssAttrPstn : 8|8@1+ (0.4,0) [0|100] "%" Vector__XXX
 SG_ EngnSprhrgr1ClthVlvCmmnd : 16|8@1+ (0.4,0) [0|100] "%" Vector__XXX
 SG_ EngnSprhrgr2ClthVlvCmmnd : 24|8@1+ (0.4,0) [0|100] "%" Vector__XXX
 SG_ EngineSupercharger1Speed : 32|16@1+ (4,0) [0|257020] "rpm" Vector__XXX
 SG_ EngineSupercharger2Speed : 48|16@1+ (4,0) [0|257020] "rpm" Vector__XXX

BO_ 2365156094 ERDCDC4RF: 8 Vector__XXX
 SG_ ErDcDc4ReferenceCrc : 0|8@1+ (1,0) [0|250] "count" Vector__XXX
 SG_ ErDcDc4ReferenceCounter : 8|4@1+ (1,0) [0|15] "" Vector__XXX
 SG_ ErDcDc4ReferenceCurrent : 16|16@1+ (0.125,0) [0|8031.875] "A" Vector__XXX
 SG_ ErDcDc4ReferenceVoltage : 32|16@1+ (0.125,0) [0|8031.875] "V" Vector__XXX
 SG_ ErDcDc4ReferencePower : 48|16@1+ (0.0625,0) [0|4015.9375] "kW" Vector__XXX

BO_ 2365156350 ERDCDC4PLR: 8 Vector__XXX
 SG_ ErDD4PrmrSdPwrMnmmLmtRqst : 0|16@1+ (0.00390625,-125) [-125|125.99609375] "%" Vector__XXX
 SG_ ErDD4PrmrSdPwrMxmmLmtRqst : 16|16@1+ (0.00390625,-125) [-125|125.99609375] "%" Vector__XXX
 SG_ ErDD4SndrSdPwrMnmmLmtRqst : 32|16@1+ (0.00390625,-125) [-125|125.99609375] "%" Vector__XXX
 SG_ ErDD4SndrSdPwrMxmmLmtRqst : 48|16@1+ (0.00390625,-125) [-125|125.99609375] "%" Vector__XXX

BO_ 2365156606 ERDCDC4CLR: 8 Vector__XXX
 SG_ ErDD4PrmrSdCrrntMnmmLmtRqst : 0|16@1+ (0.00390625,-125) [-125|125.99609375] "%" Vector__XXX
 SG_ ErDD4PrmrSdCrrntMxmmLmtRqst : 16|16@1+ (0.00390625,-125) [-125|125.99609375] "%" Vector__XXX
 SG_ ErDD4SndrSdCrrntMnmmLmtRqst : 32|16@1+ (0.00390625,-125) [-125|125.99609375] "%" Vector__XXX
 SG_ ErDD4SndrSdCrrntMxmmLmtRqst : 48|16@1+ (0.00390625,-125) [-125|125.99609375] "%" Vector__XXX

BO_ 2365156862 ERDCDC4VLR: 8 Vector__XXX
 SG_ ErDD4PrmrSdVltgMnmmLmtRqst : 0|16@1+ (0.00390625,-125) [0|125.99609375] "%" Vector__XXX
 SG_ ErDD4PrmrSdVltgMxmmLmtRqst : 16|16@1+ (0.00390625,-125) [0|125.99609375] "%" Vector__XXX
 SG_ ErDD4SndrSdVltgMnmmLmtRqst : 32|16@1+ (0.00390625,-125) [0|125.99609375] "%" Vector__XXX
 SG_ ErDD4SndrSdVltgMxmmLmtRqst : 48|16@1+ (0.00390625,-125) [0|125.99609375] "%" Vector__XXX

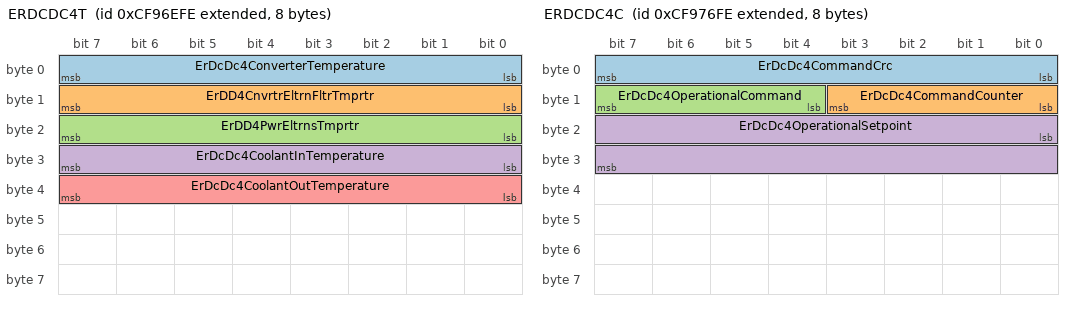
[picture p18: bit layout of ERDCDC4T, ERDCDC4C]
BO_ 2365157118 ERDCDC4T: 8 Vector__XXX
 SG_ ErDcDc4ConverterTemperature : 0|8@1+ (1,-40) [-40|210] "degC" Vector__XXX
 SG_ ErDD4CnvrtrEltrnFltrTmprtr : 8|8@1+ (1,-40) [-40|210] "degC" Vector__XXX
 SG_ ErDD4PwrEltrnsTmprtr : 16|8@1+ (1,-40) [-40|210] "degC" Vector__XXX
 SG_ ErDcDc4CoolantInTemperature : 24|8@1+ (1,-40) [-40|210] "degC" Vector__XXX
 SG_ ErDcDc4CoolantOutTemperature : 32|8@1+ (1,-40) [-40|210] "degC" Vector__XXX

BO_ 2566483966 ERDCDC4PLS: 8 Vector__XXX
 SG_ ErDD4PrmrSdPwrMnmmLmtSttng : 0|16@1+ (0.00390625,-125) [-125|125.99609375] "%" Vector__XXX
 SG_ ErDD4PrmrSdPwrMxmmLmtSttng : 16|16@1+ (0.00390625,-125) [-125|125.99609375] "%" Vector__XXX
 SG_ ErDD4SndrSdPwrMnmmLmtSttng : 32|16@1+ (0.00390625,-125) [-125|125.99609375] "%" Vector__XXX
 SG_ ErDD4SndrSdPwrMxmmLmtSttng : 48|16@1+ (0.00390625,-125) [-125|125.99609375] "%" Vector__XXX

BO_ 2566484222 ERDCDC4CLS: 8 Vector__XXX
 SG_ ErDD4PrmrSdCrrntMnmmLmtSttng : 0|16@1+ (0.00390625,-125) [-125|125.99609375] "%" Vector__XXX
 SG_ ErDD4PrmrSdCrrntMxmmLmtSttng : 16|16@1+ (0.00390625,-125) [-125|125.99609375] "%" Vector__XXX
 SG_ ErDD4SndrSdCrrntMnmmLmtSttng : 32|16@1+ (0.00390625,-125) [-125|125.99609375] "%" Vector__XXX
 SG_ ErDD4SndrSdCrrntMxmmLmtSttng : 48|16@1+ (0.00390625,-125) [-125|125.99609375] "%" Vector__XXX

BO_ 2566484478 ERDCDC4VLS: 8 Vector__XXX
 SG_ ErDD4PrmrSdVltgMnmmLmtSttng : 0|16@1+ (0.00390625,-125) [0|125.99609375] "%" Vector__XXX
 SG_ ErDD4PrmrSdVltgMxmmLmtSttng : 16|16@1+ (0.00390625,-125) [0|125.99609375] "%" Vector__XXX
 SG_ ErDD4SndrSdVltgMnmmLmtSttng : 32|16@1+ (0.00390625,-125) [0|125.99609375] "%" Vector__XXX
 SG_ ErDD4SndrSdVltgMxmmLmtSttng : 48|16@1+ (0.00390625,-125) [0|125.99609375] "%" Vector__XXX

BO_ 2365158142 ERDCDC4LV: 8 Vector__XXX
 SG_ ErDD4CntrllrInptIgntnVltg : 0|16@1+ (0.05,0) [0|3212.75] "V" Vector__XXX
 SG_ ErDD4CntrllrInptUnswthdSlVltg : 16|16@1+ (0.05,0) [0|3212.75] "V" Vector__XXX

BO_ 2365158398 ERDCDC4PCV: 8 Vector__XXX
 SG_ ErDcDc4PrimarySidePower : 0|16@1+ (0.00390625,-125) [-125|125.99609375] "%" Vector__XXX
 SG_ ErDcDc4SecondarySidePower : 16|16@1+ (0.00390625,-125) [-125|125.99609375] "%" Vector__XXX
 SG_ ErDD4PrmrSdNgtvTChsssGrndVltg : 32|16@1+ (0.00390625,-125) [0|125.99609375] "%" Vector__XXX
 SG_ ErDD4SndrSdNgtvTChsssGrndVltg : 48|16@1+ (0.00390625,-125) [0|125.99609375] "%" Vector__XXX

BO_ 2365158654 ERDCDC4VC: 8 Vector__XXX
 SG_ ErDcDc4PrimarySideVoltage : 0|16@1+ (0.00390625,-125) [0|125.99609375] "%" Vector__XXX
 SG_ ErDcDc4SecondarySideVoltage : 16|16@1+ (0.00390625,-125) [0|125.99609375] "%" Vector__XXX
 SG_ ErDcDc4PrimarySideCurrent : 32|16@1+ (0.00390625,-125) [-125|125.99609375] "%" Vector__XXX
 SG_ ErDcDc4SecondarySideCurrent : 48|16@1+ (0.00390625,-125) [-125|125.99609375] "%" Vector__XXX

BO_ 2365158910 ERDCDC4OS: 8 Vector__XXX
 SG_ ErDcDc4StatusCrc : 0|8@1+ (1,0) [0|250] "count" Vector__XXX
 SG_ ErDcDc4StatusCounter : 8|4@1+ (1,0) [0|15] "" Vector__XXX
 SG_ ErDcDc4OperationalStatus : 12|4@1+ (1,0) [0|15] "" Vector__XXX
 SG_ ErDcDc4HvilStatus : 16|2@1+ (1,0) [0|3] "" Vector__XXX
 SG_ ErDcDc4LoadshedRequest : 18|2@1+ (1,0) [0|3] "" Vector__XXX
 SG_ ErDD4PwrLmtDTPrmrSdCrrntMnmm : 20|2@1+ (1,0) [0|3] "" Vector__XXX
 SG_ ErDD4PwrLmtDTPrmrSdCrrntMxmm : 22|2@1+ (1,0) [0|3] "" Vector__XXX
 SG_ ErDD4PwrLmtDTSndrSdCrrntMnmm : 24|2@1+ (1,0) [0|3] "" Vector__XXX
 SG_ ErDD4PwrLmtDTSndrSdCrrntMxmm : 26|2@1+ (1,0) [0|3] "" Vector__XXX
 SG_ ErDD4PwrLmtDTPrmrSdVltgMnmm : 28|2@1+ (1,0) [0|3] "" Vector__XXX
 SG_ ErDD4PwrLmtDTPrmrSdVltgMxmm : 30|2@1+ (1,0) [0|3] "" Vector__XXX
 SG_ ErDD4PwrLmtDTSndrSdVltgMnmm : 32|2@1+ (1,0) [0|3] "" Vector__XXX
 SG_ ErDD4PwrLmtDTSndrSdVltgMxmm : 34|2@1+ (1,0) [0|3] "" Vector__XXX
 SG_ ErDD4PwrLmtDTCnvrtrTmprtr : 36|2@1+ (1,0) [0|3] "" Vector__XXX
 SG_ ErDD4PwrLmtDTEltrnFltrTmprtr : 38|2@1+ (1,0) [0|3] "" Vector__XXX
 SG_ ErDD4PwrLmtDTPwrEltrnsTmprtr : 40|2@1+ (1,0) [0|3] "" Vector__XXX
 SG_ ErDD4PwrLmtDTUndfndRsn : 42|2@1+ (1,0) [0|3] "" Vector__XXX

BO_ 2365159166 ERDCDC4C: 8 Vector__XXX
 SG_ ErDcDc4CommandCrc : 0|8@1+ (1,0) [0|250] "count" Vector__XXX
 SG_ ErDcDc4CommandCounter : 8|4@1+ (1,0) [0|15] "" Vector__XXX
 SG_ ErDcDc4OperationalCommand : 12|4@1+ (1,0) [0|15] "" Vector__XXX
 SG_ ErDcDc4OperationalSetpoint : 16|16@1+ (0.00390625,-125) [-125|125.99609375] "%" Vector__XXX

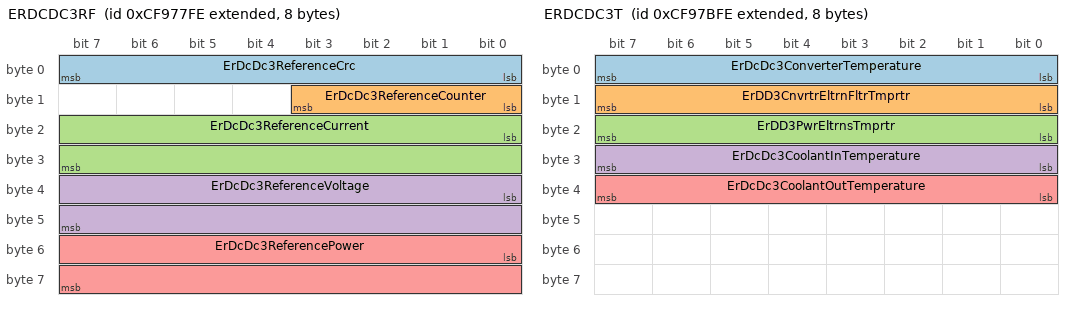
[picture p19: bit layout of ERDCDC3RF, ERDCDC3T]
BO_ 2365159422 ERDCDC3RF: 8 Vector__XXX
 SG_ ErDcDc3ReferenceCrc : 0|8@1+ (1,0) [0|250] "count" Vector__XXX
 SG_ ErDcDc3ReferenceCounter : 8|4@1+ (1,0) [0|15] "" Vector__XXX
 SG_ ErDcDc3ReferenceCurrent : 16|16@1+ (0.125,0) [0|8031.875] "A" Vector__XXX
 SG_ ErDcDc3ReferenceVoltage : 32|16@1+ (0.125,0) [0|8031.875] "V" Vector__XXX
 SG_ ErDcDc3ReferencePower : 48|16@1+ (0.0625,0) [0|4015.9375] "kW" Vector__XXX

BO_ 2365159678 ERDCDC3PLR: 8 Vector__XXX
 SG_ ErDD3PrmrSdPwrMnmmLmtRqst : 0|16@1+ (0.00390625,-125) [-125|125.99609375] "%" Vector__XXX
 SG_ ErDD3PrmrSdPwrMxmmLmtRqst : 16|16@1+ (0.00390625,-125) [-125|125.99609375] "%" Vector__XXX
 SG_ ErDD3SndrSdPwrMnmmLmtRqst : 32|16@1+ (0.00390625,-125) [-125|125.99609375] "%" Vector__XXX
 SG_ ErDD3SndrSdPwrMxmmLmtRqst : 48|16@1+ (0.00390625,-125) [-125|125.99609375] "%" Vector__XXX

BO_ 2365159934 ERDCDC3CLR: 8 Vector__XXX
 SG_ ErDD3PrmrSdCrrntMnmmLmtRqst : 0|16@1+ (0.00390625,-125) [-125|125.99609375] "%" Vector__XXX
 SG_ ErDD3PrmrSdCrrntMxmmLmtRqst : 16|16@1+ (0.00390625,-125) [-125|125.99609375] "%" Vector__XXX
 SG_ ErDD3SndrSdCrrntMnmmLmtRqst : 32|16@1+ (0.00390625,-125) [-125|125.99609375] "%" Vector__XXX
 SG_ ErDD3SndrSdCrrntMxmmLmtRqst : 48|16@1+ (0.00390625,-125) [-125|125.99609375] "%" Vector__XXX

BO_ 2365160190 ERDCDC3VLR: 8 Vector__XXX
 SG_ ErDD3PrmrSdVltgMnmmLmtRqst : 0|16@1+ (0.00390625,-125) [0|125.99609375] "%" Vector__XXX
 SG_ ErDD3PrmrSdVltgMxmmLmtRqst : 16|16@1+ (0.00390625,-125) [0|125.99609375] "%" Vector__XXX
 SG_ ErDD3SndrSdVltgMnmmLmtRqst : 32|16@1+ (0.00390625,-125) [0|125.99609375] "%" Vector__XXX
 SG_ ErDD3SndrSdVltgMxmmLmtRqst : 48|16@1+ (0.00390625,-125) [0|125.99609375] "%" Vector__XXX

BO_ 2365160446 ERDCDC3T: 8 Vector__XXX
 SG_ ErDcDc3ConverterTemperature : 0|8@1+ (1,-40) [-40|210] "degC" Vector__XXX
 SG_ ErDD3CnvrtrEltrnFltrTmprtr : 8|8@1+ (1,-40) [-40|210] "degC" Vector__XXX
 SG_ ErDD3PwrEltrnsTmprtr : 16|8@1+ (1,-40) [-40|210] "degC" Vector__XXX
 SG_ ErDcDc3CoolantInTemperature : 24|8@1+ (1,-40) [-40|210] "degC" Vector__XXX
 SG_ ErDcDc3CoolantOutTemperature : 32|8@1+ (1,-40) [-40|210] "degC" Vector__XXX

BO_ 2566487294 ERDCDC3PLS: 8 Vector__XXX
 SG_ ErDD3PrmrSdPwrMnmmLmtSttng : 0|16@1+ (0.00390625,-125) [-125|125.99609375] "%" Vector__XXX
 SG_ ErDD3PrmrSdPwrMxmmLmtSttng : 16|16@1+ (0.00390625,-125) [-125|125.99609375] "%" Vector__XXX
 SG_ ErDD3SndrSdPwrMnmmLmtSttng : 32|16@1+ (0.00390625,-125) [-125|125.99609375] "%" Vector__XXX
 SG_ ErDD3SndrSdPwrMxmmLmtSttng : 48|16@1+ (0.00390625,-125) [-125|125.99609375] "%" Vector__XXX

BO_ 2566487550 ERDCDC3CLS: 8 Vector__XXX
 SG_ ErDD3PrmrSdCrrntMnmmLmtSttng : 0|16@1+ (0.00390625,-125) [-125|125.99609375] "%" Vector__XXX
 SG_ ErDD3PrmrSdCrrntMxmmLmtSttng : 16|16@1+ (0.00390625,-125) [-125|125.99609375] "%" Vector__XXX
 SG_ ErDD3SndrSdCrrntMnmmLmtSttng : 32|16@1+ (0.00390625,-125) [-125|125.99609375] "%" Vector__XXX
 SG_ ErDD3SndrSdCrrntMxmmLmtSttng : 48|16@1+ (0.00390625,-125) [-125|125.99609375] "%" Vector__XXX

BO_ 2566487806 ERDCDC3VLS: 8 Vector__XXX
 SG_ ErDD3PrmrSdVltgMnmmLmtSttng : 0|16@1+ (0.00390625,-125) [0|125.99609375] "%" Vector__XXX
 SG_ ErDD3PrmrSdVltgMxmmLmtSttng : 16|16@1+ (0.00390625,-125) [0|125.99609375] "%" Vector__XXX
 SG_ ErDD3SndrSdVltgMnmmLmtSttng : 32|16@1+ (0.00390625,-125) [0|125.99609375] "%" Vector__XXX
 SG_ ErDD3SndrSdVltgMxmmLmtSttng : 48|16@1+ (0.00390625,-125) [0|125.99609375] "%" Vector__XXX

BO_ 2365161470 ERDCDC3LV: 8 Vector__XXX
 SG_ ErDD3CntrllrInptIgntnVltg : 0|16@1+ (0.05,0) [0|3212.75] "V" Vector__XXX
 SG_ ErDD3CntrllrInptUnswthdSlVltg : 16|16@1+ (0.05,0) [0|3212.75] "V" Vector__XXX

BO_ 2365161726 ERDCDC3PCV: 8 Vector__XXX
 SG_ ErDcDc3PrimarySidePower : 0|16@1+ (0.00390625,-125) [-125|125.99609375] "%" Vector__XXX
 SG_ ErDcDc3SecondarySidePower : 16|16@1+ (0.00390625,-125) [-125|125.99609375] "%" Vector__XXX
 SG_ ErDD3PrmrSdNgtvTChsssGrndVltg : 32|16@1+ (0.00390625,-125) [0|125.99609375] "%" Vector__XXX
 SG_ ErDD3SndrSdNgtvTChsssGrndVltg : 48|16@1+ (0.00390625,-125) [0|125.99609375] "%" Vector__XXX

BO_ 2365161982 ERDCDC3VC: 8 Vector__XXX
 SG_ ErDcDc3PrimarySideVoltage : 0|16@1+ (0.00390625,-125) [0|125.99609375] "%" Vector__XXX
 SG_ ErDcDc3SecondarySideVoltage : 16|16@1+ (0.00390625,-125) [0|125.99609375] "%" Vector__XXX
 SG_ ErDcDc3PrimarySideCurrent : 32|16@1+ (0.00390625,-125) [-125|125.99609375] "%" Vector__XXX
 SG_ ErDcDc3SecondarySideCurrent : 48|16@1+ (0.00390625,-125) [-125|125.99609375] "%" Vector__XXX

BO_ 2365162238 ERDCDC3OS: 8 Vector__XXX
 SG_ ErDcDc3StatusCrc : 0|8@1+ (1,0) [0|250] "count" Vector__XXX
 SG_ ErDcDc3StatusCounter : 8|4@1+ (1,0) [0|15] "" Vector__XXX
 SG_ ErDcDc3OperationalStatus : 12|4@1+ (1,0) [0|15] "" Vector__XXX
 SG_ ErDcDc3HvilStatus : 16|2@1+ (1,0) [0|3] "" Vector__XXX
 SG_ ErDcDc3LoadshedRequest : 18|2@1+ (1,0) [0|3] "" Vector__XXX
 SG_ ErDD3PwrLmtDTPrmrSdCrrntMnmm : 20|2@1+ (1,0) [0|3] "" Vector__XXX
 SG_ ErDD3PwrLmtDTPrmrSdCrrntMxmm : 22|2@1+ (1,0) [0|3] "" Vector__XXX
 SG_ ErDD3PwrLmtDTSndrSdCrrntMnmm : 24|2@1+ (1,0) [0|3] "" Vector__XXX
 SG_ ErDD3PwrLmtDTSndrSdCrrntMxmm : 26|2@1+ (1,0) [0|3] "" Vector__XXX
 SG_ ErDD3PwrLmtDTPrmrSdVltgMnmm : 28|2@1+ (1,0) [0|3] "" Vector__XXX
 SG_ ErDD3PwrLmtDTPrmrSdVltgMxmm : 30|2@1+ (1,0) [0|3] "" Vector__XXX
 SG_ ErDD3PwrLmtDTSndrSdVltgMnmm : 32|2@1+ (1,0) [0|3] "" Vector__XXX
 SG_ ErDD3PwrLmtDTSndrSdVltgMxmm : 34|2@1+ (1,0) [0|3] "" Vector__XXX
 SG_ ErDD3PwrLmtDTCnvrtrTmprtr : 36|2@1+ (1,0) [0|3] "" Vector__XXX
 SG_ ErDD3PwrLmtDTEltrnFltrTmprtr : 38|2@1+ (1,0) [0|3] "" Vector__XXX
 SG_ ErDD3PwrLmtDTPwrEltrnsTmprtr : 40|2@1+ (1,0) [0|3] "" Vector__XXX
 SG_ ErDD3PwrLmtDTUndfndRsn : 42|2@1+ (1,0) [0|3] "" Vector__XXX

CM_ BO_ 2365189118 "High Voltage Energy Storage System Internal Status 5";
CM_ SG_ 2365189118 HvssHghVltgIntrnlPstvCnttr1Stt "HVESS High-Voltage Internal (Positive) Contactor 1 State: Position of the High Voltage Energy Storage System Internal Circuit 1 positive side bus contactor (or Pack 1 in systems with only one pack). When this contactor is closed, the positive side of...";
CM_ SG_ 2365189118 HvssHghVltgIntrnlNgtvCnttr1Stt "HVESS High-Voltage Internal (Negative) Contactor 1 State: Position of the High Voltage Energy Storage System Internal Circuit 1 negative side bus contactor (or Pack 1 in systems with only one pack). When this contactor is closed, the negative side of...";
CM_ SG_ 2365189118 HvssHghVltgIntrnlPrhrgRl1Stt "HVESS High-Voltage Internal Precharge Relay 1 State: Position of the High Voltage Energy Storage System Internal Circuit 1 bus contactor pre-charge relay (or Pack 1 in systems with only one pack). When this relay is closed, the High Voltage Energy St...";
CM_ SG_ 2365189118 HvssTMtSstItHt1Stts "HVESS Thermal Management System Internal Heater 1 Status: The state of the High Voltage Energy Storage System Internal Circuit 1 heater (or Pack 1 in systems with only one pack).00b = Heater Off01b = Heater On10b = Error11b = Not Available";
CM_ SG_ 2365189118 HvssHghVltgIntrnlBsVltgLvl1 "HVESS High-Voltage Internal Bus Voltage Level 1: The voltage level of the high voltage bus, as measured by the  High Voltage Energy Storage System Internal Circuit 1 on the bus side (not the battery side) of its contactors (or Pack 1 in systems with ...";
CM_ SG_ 2365189118 HvssHghVltgIntrnlPstvCnttr2Stt "HVESS High-Voltage Internal (Positive) Contactor 2 State: Position of the High Voltage Energy Storage System Internal Circuit 2 positive side bus contactor (or Pack 1 in systems with only one pack). When this contactor is closed, the positive side of...";
CM_ SG_ 2365189118 HvssHghVltgIntrnlNgtvCnttr2Stt "HVESS High-Voltage Internal (Negative) Contactor 2 State   : Position of the High Voltage Energy Storage System Internal Circuit 2 negative side bus contactor (or Pack 1 in systems with only one pack). When this contactor is closed, the negative side...";
CM_ SG_ 2365189118 HvssHghVltgIntrnlPrhrgRl2Stt "HVESS High-Voltage Internal Precharge Relay 2 State: Position of the High Voltage Energy Storage System Internal Circuit 2 bus contactor pre-charge relay (or Pack 1 in systems with only one pack). When this relay is closed, the High Voltage Energy St...";
CM_ SG_ 2365189118 HvssTMtSstItHt2Stts "HVESS Thermal Management System Internal Heater 2 Status: The state of the High Voltage Energy Storage System Internal Circuit 2 heater (or Pack 1 in systems with only one pack).00b = Heater Off01b = Heater On10b = Error11b = Not Available";
CM_ SG_ 2365189118 HvssHghVltgIntrnlBsVltgLvl2 "HVESS High-Voltage Internal Bus Voltage Level 2: The voltage level of the high voltage bus, as measured by the  High Voltage Energy Storage System Internal Circuit 2 on the bus side (not the battery side) of its contactors (or Pack 1 in systems with ...";
CM_ BO_ 2365189374 "High Voltage Energy Storage System Internal Status 6";
CM_ SG_ 2365189374 HvssHghVltgIntrnlPstvCnttr3Stt "HVESS High-Voltage Internal (Positive) Contactor 3 State: Position of the High Voltage Energy Storage System Internal Circuit 3 positive side bus contactor (or Pack 1 in systems with only one pack). When this contactor is closed, the positive side of...";
CM_ SG_ 2365189374 HvssHghVltgIntrnlNgtvCnttr3Stt "HVESS High-Voltage Internal (Negative) Contactor 3 State   : Position of the High Voltage Energy Storage System Internal Circuit 3 negative side bus contactor (or Pack 1 in systems with only one pack). When this contactor is closed, the negative side...";
CM_ SG_ 2365189374 HvssHghVltgIntrnlPrhrgRl3Stt "HVESS High-Voltage Internal Precharge Relay 3 State: Position of the High Voltage Energy Storage System Internal Circuit 3 bus contactor pre-charge relay (or Pack 1 in systems with only one pack). When this relay is closed, the High Voltage Energy St...";
CM_ SG_ 2365189374 HvssTMtSstItHt3Stts "HVESS Thermal Management System Internal Heater 3 Status: The state of the High Voltage Energy Storage System Internal Circuit 3 heater (or Pack 1 in systems with only one pack).00b = Heater Off01b = Heater On10b = Error11b = Not Available";
CM_ SG_ 2365189374 HvssHghVltgIntrnlBsVltgLvl3 "HVESS High-Voltage Internal Bus Voltage Level 3: The voltage level of the high voltage bus, as measured by the  High Voltage Energy Storage System Internal Circuit 3 on the bus side (not the battery side) of its contactors (or Pack 1 in systems with ...";
CM_ SG_ 2365189374 HvssHghVltgIntrnlPstvCnttr4Stt "HVESS High-Voltage Internal (Positive) Contactor 4 State: Position of the High Voltage Energy Storage System Internal Circuit 4 positive side bus contactor (or Pack 1 in systems with only one pack). When this contactor is closed, the positive side of...";
CM_ SG_ 2365189374 HvssHghVltgIntrnlNgtvCnttr4Stt "HVESS High-Voltage Internal (Negative) Contactor 4 State   : Position of the High Voltage Energy Storage System Internal Circuit 4 negative side bus contactor (or Pack 1 in systems with only one pack). When this contactor is closed, the negative side...";
CM_ SG_ 2365189374 HvssHghVltgIntrnlPrhrgRl4Stt "HVESS High-Voltage Internal Precharge Relay 4 State: Position of the High Voltage Energy Storage System Internal Circuit 4 bus contactor pre-charge relay (or Pack 1 in systems with only one pack). When this relay is closed, the High Voltage Energy St...";
CM_ SG_ 2365189374 HvssTMtSstItHt4Stts "HVESS Thermal Management System Internal Heater 4 Status: The state of the High Voltage Energy Storage System Internal Circuit 4 heater (or Pack 1 in systems with only one pack)00b = Heater Off01b = Heater On10b = Error11b = Not Available";
CM_ SG_ 2365189374 HvssHghVltgIntrnlBsVltgLvl4 "HVESS High-Voltage Internal Bus Voltage Level 4: The voltage level of the high voltage bus, as measured by the  High Voltage Energy Storage System Internal Circuit 4 on the bus side (not the battery side) of its contactors (or Pack 1 in systems with ...";
CM_ BO_ 2365189630 "High Voltage Energy Storage System Internal Status 7";
CM_ SG_ 2365189630 HvssNmrOfIntrnlCrtsRd "HVESS Number of Internal Circuits Ready: The number of High Voltage Energy Storage Internal Circuits that are currently ready to provide high voltage energy or are actively providing high voltage energy in the HVESS system (or Pack 1 in systems with ...";
CM_ BO_ 2566516478 "Engine Cylinder Average Ignition Delay Angle 1";
CM_ SG_ 2566516478 EngnClndr1AvrgIgntnDlAngl "Engine Cylinder 1 Average Ignition Delay Angle: Average ignition delay for engine cylinder 1 with reference to the crank angle.  Ignition delay is the crank angle difference from the initiation of spark to the start of combustion.";
CM_ SG_ 2566516478 EngnClndr2AvrgIgntnDlAngl "Engine Cylinder 2 Average Ignition Delay Angle: Average ignition delay for engine cylinder 2 with reference to the crank angle.  Ignition delay is the crank angle difference from the initiation of spark to the start of combustion.";
CM_ SG_ 2566516478 EngnClndr3AvrgIgntnDlAngl "Engine Cylinder 3 Average Ignition Delay Angle: Average ignition delay for engine cylinder 3 with reference to the crank angle.  Ignition delay is the crank angle difference from the initiation of spark to the start of combustion.";
CM_ SG_ 2566516478 EngnClndr4AvrgIgntnDlAngl "Engine Cylinder 4 Average Ignition Delay Angle: Average ignition delay for engine cylinder 4 with reference to the crank angle.  Ignition delay is the crank angle difference from the initiation of spark to the start of combustion.";
CM_ BO_ 2566516734 "Engine Cylinder Average Ignition Delay Angle 2";
CM_ SG_ 2566516734 EngnClndr5AvrgIgntnDlAngl "Engine Cylinder 5 Average Ignition Delay Angle: Average ignition delay for engine cylinder 5 with reference to the crank angle.  Ignition delay is the crank angle difference from the initiation of spark to the start of combustion.";
CM_ SG_ 2566516734 EngnClndr6AvrgIgntnDlAngl "Engine Cylinder 6 Average Ignition Delay Angle: Average ignition delay for engine cylinder 6 with reference to the crank angle.  Ignition delay is the crank angle difference from the initiation of spark to the start of combustion.";
CM_ SG_ 2566516734 EngnClndr7AvrgIgntnDlAngl "Engine Cylinder 7 Average Ignition Delay Angle: Average ignition delay for engine cylinder 7 with reference to the crank angle.  Ignition delay is the crank angle difference from the initiation of spark to the start of combustion.";
CM_ SG_ 2566516734 EngnClndr8AvrgIgntnDlAngl "Engine Cylinder 8 Average Ignition Delay Angle: Average ignition delay for engine cylinder 8 with reference to the crank angle.  Ignition delay is the crank angle difference from the initiation of spark to the start of combustion.";
CM_ BO_ 2566516990 "Engine Cylinder Average Ignition Delay Angle 3";
CM_ SG_ 2566516990 EngnClndr9AvrgIgntnDlAngl "Engine Cylinder 9 Average Ignition Delay Angle: Average ignition delay for engine cylinder 9 with reference to the crank angle.  Ignition delay is the crank angle difference from the initiation of spark to the start of combustion.";
CM_ SG_ 2566516990 EngnClndr10AvrgIgntnDlAngl "Engine Cylinder 10 Average Ignition Delay Angle: Average ignition delay for engine cylinder 10 with reference to the crank angle.  Ignition delay is the crank angle difference from the initiation of spark to the start of combustion.";
CM_ SG_ 2566516990 EngnClndr11AvrgIgntnDlAngl "Engine Cylinder 11 Average Ignition Delay Angle: Average ignition delay for engine cylinder 11 with reference to the crank angle.  Ignition delay is the crank angle difference from the initiation of spark to the start of combustion.";
CM_ SG_ 2566516990 EngnClndr12AvrgIgntnDlAngl "Engine Cylinder 12 Average Ignition Delay Angle: Average ignition delay for engine cylinder 12 with reference to the crank angle.  Ignition delay is the crank angle difference from the initiation of spark to the start of combustion.";
CM_ BO_ 2566517246 "Engine Cylinder Average Ignition Delay Angle 4";
CM_ SG_ 2566517246 EngnClndr13AvrgIgntnDlAngl "Engine Cylinder 13 Average Ignition Delay Angle: Average ignition delay for engine cylinder 13 with reference to the crank angle.  Ignition delay is the crank angle difference from the initiation of spark to the start of combustion.";
CM_ SG_ 2566517246 EngnClndr14AvrgIgntnDlAngl "Engine Cylinder 14 Average Ignition Delay Angle: Average ignition delay for engine cylinder 14 with reference to the crank angle.  Ignition delay is the crank angle difference from the initiation of spark to the start of combustion.";
CM_ SG_ 2566517246 EngnClndr15AvrgIgntnDlAngl "Engine Cylinder 15 Average Ignition Delay Angle: Average ignition delay for engine cylinder 15 with reference to the crank angle.  Ignition delay is the crank angle difference from the initiation of spark to the start of combustion.";
CM_ SG_ 2566517246 EngnClndr16AvrgIgntnDlAngl "Engine Cylinder 16 Average Ignition Delay Angle: Average ignition delay for engine cylinder 16 with reference to the crank angle.  Ignition delay is the crank angle difference from the initiation of spark to the start of combustion.";
CM_ BO_ 2566517502 "Engine Cylinder Average Ignition Delay Angle 5";
CM_ SG_ 2566517502 EngnClndr17AvrgIgntnDlAngl "Engine Cylinder 17 Average Ignition Delay Angle: Average ignition delay for engine cylinder 17 with reference to the crank angle.  Ignition delay is the crank angle difference from the initiation of spark to the start of combustion.";
CM_ SG_ 2566517502 EngnClndr18AvrgIgntnDlAngl "Engine Cylinder 18 Average Ignition Delay Angle: Average ignition delay for engine cylinder 18 with reference to the crank angle.  Ignition delay is the crank angle difference from the initiation of spark to the start of combustion.";
CM_ SG_ 2566517502 EngnClndr19AvrgIgntnDlAngl "Engine Cylinder 19 Average Ignition Delay Angle: Average ignition delay for engine cylinder 19 with reference to the crank angle.  Ignition delay is the crank angle difference from the initiation of spark to the start of combustion.";
CM_ SG_ 2566517502 EngnClndr20AvrgIgntnDlAngl "Engine Cylinder 20 Average Ignition Delay Angle: Average ignition delay for engine cylinder 20 with reference to the crank angle.  Ignition delay is the crank angle difference from the initiation of spark to the start of combustion.";
CM_ BO_ 2566517758 " Engine Indicated Mean Effective Pressure Information 1";
CM_ SG_ 2566517758 ECd1IdtdMEtvPssPwB "Engine Cylinder 1 Indicated Mean Effective Pressure Power Balance: Calculated percent of the average indicated mean effective pressure (IMEP) of all cylinders with deadband areas for cylinder 1.";
CM_ SG_ 2566517758 ECd2IdtdMEtvPssPwB "Engine Cylinder 2 Indicated Mean Effective Pressure Power Balance: Calculated percent of the average indicated mean effective pressure (IMEP) of all cylinders with deadband areas for cylinder 2.";
CM_ SG_ 2566517758 ECd3IdtdMEtvPssPwB "Engine Cylinder 3 Indicated Mean Effective Pressure Power Balance: Calculated percent of the average indicated mean effective pressure (IMEP) of all cylinders with deadband areas for cylinder 3.";
CM_ SG_ 2566517758 ECd4IdtdMEtvPssPwB "Engine Cylinder 4 Indicated Mean Effective Pressure Power Balance: Calculated percent of the average indicated mean effective pressure (IMEP) of all cylinders with deadband areas for cylinder 4.";
CM_ SG_ 2566517758 ECd5IdtdMEtvPssPwB "Engine Cylinder 5 Indicated Mean Effective Pressure Power Balance: Calculated percent of the average indicated mean effective pressure (IMEP) of all cylinders with deadband areas for cylinder 5.";
CM_ SG_ 2566517758 ECd6IdtdMEtvPssPwB "Engine Cylinder 6 Indicated Mean Effective Pressure Power Balance: Calculated percent of the average indicated mean effective pressure (IMEP) of all cylinders with deadband areas for cylinder 6.";
CM_ SG_ 2566517758 ECd7IdtdMEtvPssPwB "Engine Cylinder 7 Indicated Mean Effective Pressure Power Balance: Calculated percent of the average indicated mean effective pressure (IMEP) of all cylinders with deadband areas for cylinder 7.";
CM_ SG_ 2566517758 ECd8IdtdMEtvPssPwB "Engine Cylinder 8 Indicated Mean Effective Pressure Power Balance: Calculated percent of the average indicated mean effective pressure (IMEP) of all cylinders with deadband areas for cylinder 8.";
CM_ BO_ 2566518014 " Engine Indicated Mean Effective Pressure Information 2";
CM_ SG_ 2566518014 ECd9IdtdMEtvPssPwB "Engine Cylinder 9 Indicated Mean Effective Pressure Power Balance: Calculated percent of the average indicated mean effective pressure (IMEP) of all cylinders with deadband areas for cylinder 9.";
CM_ SG_ 2566518014 ECd10IdtdMEtvPssPwB "Engine Cylinder 10 Indicated Mean Effective Pressure Power Balance: Calculated percent of the average indicated mean effective pressure (IMEP) of all cylinders with deadband areas for cylinder 10.";
CM_ SG_ 2566518014 ECd11IdtdMEtvPssPwB "Engine Cylinder 11 Indicated Mean Effective Pressure Power Balance: Calculated percent of the average indicated mean effective pressure (IMEP) of all cylinders with deadband areas for cylinder 11.";
CM_ SG_ 2566518014 ECd12IdtdMEtvPssPwB "Engine Cylinder 12 Indicated Mean Effective Pressure Power Balance: Calculated percent of the average indicated mean effective pressure (IMEP) of all cylinders with deadband areas for cylinder 12.";
CM_ SG_ 2566518014 ECd13IdtdMEtvPssPwB "Engine Cylinder 13 Indicated Mean Effective Pressure Power Balance: Calculated percent of the average indicated mean effective pressure (IMEP) of all cylinders with deadband areas for cylinder 13.";
CM_ SG_ 2566518014 ECd14IdtdMEtvPssPwB "Engine Cylinder 14 Indicated Mean Effective Pressure Power Balance: Calculated percent of the average indicated mean effective pressure (IMEP) of all cylinders with deadband areas for cylinder 14.";
CM_ SG_ 2566518014 ECd15IdtdMEtvPssPwB "Engine Cylinder 15 Indicated Mean Effective Pressure Power Balance: Calculated percent of the average indicated mean effective pressure (IMEP) of all cylinders with deadband areas for cylinder 15.";
CM_ SG_ 2566518014 ECd16IdtdMEtvPssPwB "Engine Cylinder 16 Indicated Mean Effective Pressure Power Balance: Calculated percent of the average indicated mean effective pressure (IMEP) of all cylinders with deadband areas for cylinder 16.";
CM_ BO_ 2566518270 " Engine Indicated Mean Effective Pressure Information 3";
CM_ SG_ 2566518270 ECd17IdtdMEtvPssPwB "Engine Cylinder 17 Indicated Mean Effective Pressure Power Balance: Calculated percent of the average indicated mean effective pressure (IMEP) of all cylinders with deadband areas for cylinder 17.";
CM_ SG_ 2566518270 ECd18IdtdMEtvPssPwB "Engine Cylinder 18 Indicated Mean Effective Pressure Power Balance: Calculated percent of the average indicated mean effective pressure (IMEP) of all cylinders with deadband areas for cylinder 18.";
CM_ SG_ 2566518270 ECd19IdtdMEtvPssPwB "Engine Cylinder 19 Indicated Mean Effective Pressure Power Balance: Calculated percent of the average indicated mean effective pressure (IMEP) of all cylinders with deadband areas for cylinder 19.";
CM_ SG_ 2566518270 ECd20IdtdMEtvPssPwB "Engine Cylinder 20 Indicated Mean Effective Pressure Power Balance: Calculated percent of the average indicated mean effective pressure (IMEP) of all cylinders with deadband areas for cylinder 20.";
CM_ SG_ 2566518270 ECd21IdtdMEtvPssPwB "Engine Cylinder 21 Indicated Mean Effective Pressure Power Balance: Calculated percent of the average indicated mean effective pressure (IMEP) of all cylinders with deadband areas for cylinder 21.";
CM_ SG_ 2566518270 ECd22IdtdMEtvPssPwB "Engine Cylinder 22 Indicated Mean Effective Pressure Power Balance: Calculated percent of the average indicated mean effective pressure (IMEP) of all cylinders with deadband areas for cylinder 22.";
CM_ SG_ 2566518270 ECd23IdtdMEtvPssPwB "Engine Cylinder 23 Indicated Mean Effective Pressure Power Balance: Calculated percent of the average indicated mean effective pressure (IMEP) of all cylinders with deadband areas for cylinder 23.";
CM_ SG_ 2566518270 ECd24IdtdMEtvPssPwB "Engine Cylinder 24 Indicated Mean Effective Pressure Power Balance: Calculated percent of the average indicated mean effective pressure (IMEP) of all cylinders with deadband areas for cylinder 24.";
CM_ BO_ 2566518526 "Fuel Cell System Coolant Fan 1 Command";
CM_ SG_ 2566518526 FlCllSstmClntFn1EnlCmmnd "Fuel Cell System Coolant Fan 1 Enable Command: Enable and direction command to the Fuel Cell System Coolant Fan 1.00b = Accessory Motor Off01b = Accessory Motor On Normal/Default Direction10b = Accessory Motor On Reverse Direction11b = Don't Care/Tak...";
CM_ SG_ 2566518526 FlCllSstmClntFn1PwrHld "Fuel Cell System Coolant Fan 1 Power Hold: Command to allow the Fuel Cell System Coolant Fan 1 to remain alive independently of the electrical enable input to the Accessory Motor.  For example, this could allow continued device operation after the ke...";
CM_ SG_ 2566518526 FlCllSstmClntFn1SpdCmmnd "Fuel Cell System Coolant Fan 1 Speed Command: Speed command to the Fuel Cell System Coolant Fan 1.Note: Both Speed Command and Percent Speed Command cannot be used at the same time.  Always set the unused speed command to Not Available.  If both comm...";
CM_ SG_ 2566518526 FlCllSstmClntFn1PrntSpdCmmnd "Fuel Cell System Coolant Fan 1 Percent Speed Command: Speed command to the Fuel Cell System Coolant Fan 1 in percentage of maximum speed.Note: Both Speed Command and Percent Speed Command cannot be used at the same time.  Always set the unused speed ...";
CM_ SG_ 2566518526 FCSstCtF1CdEdddIttSppt "Fuel Cell System Coolant Fan 1 Command Embedded Integrity Support: Indicates that SPN 23549 (Fuel Cell System Coolant Fan 1 Command CRC) and SPN 23548 (Fuel Cell System Coolant Fan 1 Command Counter) are supported by the sender.00b = Fuel Cell System...";
CM_ SG_ 2566518526 FlCllSstmClntFn1CmmndCntr "Fuel Cell System Coolant Fan 1 Command Counter: The message counter is used to detect situations where the transmitting ECU malfunction repeats the same frame all the time. The receiver of the information may use the counter parameter to detect this ...";
CM_ SG_ 2566518526 FlCllSstmClntFn1CmmndCr "Fuel Cell System Coolant Fan 1 Command CRC: The CRC is defined as follows:  - Length: 8 bits  - Polynomial: x^8+x^5+x^3+x^2+x+1  - Initial Value: FFh  - Input Data Reflection: Not reflected  - Result Data Reflection: Not reflected  - XOR value: FFhSA...";
CM_ BO_ 2566518782 "Fuel Cell System Coolant Fan 1 Status 1";
CM_ SG_ 2566518782 FlCllSstmClntFn1MtrSpdStts "Fuel Cell System Coolant Fan 1 Motor Speed Status: Enable and direction status of the Fuel Cell System Coolant Fan 1 system or component.  This parameter is used with SPN 23235 (Fuel Cell System Coolant Fan 1 Motor Speed).00b = Accessory Motor Off01b...";
CM_ SG_ 2566518782 FCSstCtF1CtSttsRsCd "Fuel Cell System Coolant Fan 1 Controller Status Reason Code: Provides the reason code describing the unique failure of the Fuel Cell System Coolant Fan 1 system or component.If a detailed reason code is not used by the supporting application, or thi...";
CM_ SG_ 2566518782 FCSstCtF1CtCdStts "Fuel Cell System Coolant Fan 1 Controller Command Status: Indicates the source of the speed command to the Fuel Cell System Coolant Fan 1 system or component.00b is communicated when the controller is self-controlled  (e.g. based on a temperature sen...";
CM_ SG_ 2566518782 FlCllSstmClntFn1MtrSpd "Fuel Cell System Coolant Fan 1 Motor Speed: Motor Speed of the Fuel Cell System Coolant Fan 1.  This parameter is used with SPN 23232 (Fuel Cell System Coolant Fan 1 Motor Speed Status).";
CM_ SG_ 2566518782 FlCllSstmClntFn1CntrlTmprtr "Fuel Cell System Coolant Fan 1 Control Temperature: A temperature measured and reported by the device.  It may be used for direct or remote (by another controller) control of the Fuel Cell System Coolant Fan 1.  For example, this may be the temperatu...";
CM_ SG_ 2566518782 FuelCellSystemCoolantFan1Power "Fuel Cell System Coolant Fan 1 Power: Calculated electrical power consumed by the Fuel Cell System Coolant Fan 1.";
CM_ SG_ 2566518782 FlCllSstmClntFn1SrvIndtr "Fuel Cell System Coolant Fan 1 Service Indicator: Indicates that service is required for the Fuel Cell System Coolant Fan 1 system or component.An active indication may convey a need for component replacement or periodic service.  The SPN 23233 (Fuel...";
CM_ SG_ 2566518782 FlCllSstmClntFn1OprtngStts "Fuel Cell System Coolant Fan 1 Operating Status: Indicates the operating status of the Fuel Cell System Coolant Fan 1 system or component.This parameter is used to inform other devices that this system or component is no longer performing to its oper...";
CM_ BO_ 2566519038 "Fuel Cell System Coolant Fan 2 Command";
CM_ SG_ 2566519038 FlCllSstmClntFn2EnlCmmnd "Fuel Cell System Coolant Fan 2 Enable Command: Enable and direction command to the Fuel Cell System Coolant Fan 2.00b = Accessory Motor Off01b = Accessory Motor On Normal/Default Direction10b = Accessory Motor On Reverse Direction11b = Don't Care/Tak...";
CM_ SG_ 2566519038 FlCllSstmClntFn2PwrHld "Fuel Cell System Coolant Fan 2 Power Hold: Command to allow the Fuel Cell System Coolant Fan 2 to remain alive independently of the electrical enable input to the Accessory Motor.  For example, this could allow continued device operation after the ke...";
CM_ SG_ 2566519038 FlCllSstmClntFn2SpdCmmnd "Fuel Cell System Coolant Fan 2 Speed Command: Speed command to the Fuel Cell System Coolant Fan 2.Note: Both Speed Command and Percent Speed Command cannot be used at the same time.  Always set the unused speed command to Not Available.  If both comm...";
CM_ SG_ 2566519038 FlCllSstmClntFn2PrntSpdCmmnd "Fuel Cell System Coolant Fan 2 Percent Speed Command: Speed command to the Fuel Cell System Coolant Fan 2 in percentage of maximum speed.Note: Both Speed Command and Percent Speed Command cannot be used at the same time.  Always set the unused speed ...";
CM_ SG_ 2566519038 FCSstCtF2CdEdddIttSppt "Fuel Cell System Coolant Fan 2 Command Embedded Integrity Support: Indicates that SPN 23552 (Fuel Cell System Coolant Fan 2 Command CRC) and SPN 23551 (Fuel Cell System Coolant Fan 2 Command Counter) are supported by the sender.00b = Fuel Cell System...";
CM_ SG_ 2566519038 FlCllSstmClntFn2CmmndCntr "Fuel Cell System Coolant Fan 2 Command Counter: The message counter is used to detect situations where the transmitting ECU malfunction repeats the same frame all the time. The receiver of the information may use the counter parameter to detect this ...";
CM_ SG_ 2566519038 FlCllSstmClntFn2CmmndCr "Fuel Cell System Coolant Fan 2 Command CRC: The CRC is defined as follows:  - Length: 8 bits  - Polynomial: x^8+x^5+x^3+x^2+x+1  - Initial Value: FFh  - Input Data Reflection: Not reflected  - Result Data Reflection: Not reflected  - XOR value: FFhSA...";
CM_ BO_ 2566519294 "Fuel Cell System Coolant Fan 2 Status 1";
CM_ SG_ 2566519294 FlCllSstmClntFn2MtrSpdStts "Fuel Cell System Coolant Fan 2 Motor Speed Status: Enable and direction status of the Fuel Cell System Coolant Fan 2 system or component.  This parameter is used with SPN 23252 (Fuel Cell System Coolant Fan 2 Motor Speed).00b = Accessory Motor Off01b...";
CM_ SG_ 2566519294 FCSstCtF2CtSttsRsCd "Fuel Cell System Coolant Fan 2 Controller Status Reason Code: Provides the reason code describing the unique failure of the Fuel Cell System Coolant Fan 2 system or component.If a detailed reason code is not used by the supporting application, or thi...";
CM_ SG_ 2566519294 FCSstCtF2CtCdStts "Fuel Cell System Coolant Fan 2 Controller Command Status: Indicates the source of the speed command to the Fuel Cell System Coolant Fan 2 system or component.00b is communicated when the controller is self-controlled  (e.g. based on a temperature sen...";
CM_ SG_ 2566519294 FlCllSstmClntFn2MtrSpd "Fuel Cell System Coolant Fan 2 Motor Speed: Motor Speed of the Fuel Cell System Coolant Fan 2.  This parameter is used with SPN 23249 (Fuel Cell System Coolant Fan 2 Motor Speed Status).";
CM_ SG_ 2566519294 FlCllSstmClntFn2CntrlTmprtr "Fuel Cell System Coolant Fan 2 Control Temperature: A temperature measured and reported by the device.  It may be used for direct or remote (by another controller) control of the Fuel Cell System Coolant Fan 2.  For example, this may be the temperatu...";
CM_ SG_ 2566519294 FuelCellSystemCoolantFan2Power "Fuel Cell System Coolant Fan 2 Power: Calculated electrical power consumed by the Fuel Cell System Coolant Fan 2.";
CM_ SG_ 2566519294 FlCllSstmClntFn2SrvIndtr "Fuel Cell System Coolant Fan 2 Service Indicator: Indicates that service is required for the Fuel Cell System Coolant Fan 2 system or component.An active indication may convey a need for component replacement or periodic service.  The SPN 23250 (Fuel...";
CM_ SG_ 2566519294 FlCllSstmClntFn2OprtngStts "Fuel Cell System Coolant Fan 2 Operating Status: Indicates the operating status of the Fuel Cell System Coolant Fan 2 system or component.This parameter is used to inform other devices that this system or component is no longer performing to its oper...";
CM_ BO_ 2566519550 "Fuel Cell System Coolant Fan 3 Command";
CM_ SG_ 2566519550 FlCllSstmClntFn3EnlCmmnd "Fuel Cell System Coolant Fan 3 Enable Command: Enable and direction command to the Fuel Cell System Coolant Fan 3.00b = Accessory Motor Off01b = Accessory Motor On Normal/Default Direction10b = Accessory Motor On Reverse Direction11b = Don't Care/Tak...";
CM_ SG_ 2566519550 FlCllSstmClntFn3PwrHld "Fuel Cell System Coolant Fan 3 Power Hold: Command to allow the Fuel Cell System Coolant Fan 3 to remain alive independently of the electrical enable input to the Accessory Motor.  For example, this could allow continued device operation after the ke...";
CM_ SG_ 2566519550 FlCllSstmClntFn3SpdCmmnd "Fuel Cell System Coolant Fan 3 Speed Command: Speed command to the Fuel Cell System Coolant Fan 3.Note: Both Speed Command and Percent Speed Command cannot be used at the same time.  Always set the unused speed command to Not Available.  If both comm...";
CM_ SG_ 2566519550 FlCllSstmClntFn3PrntSpdCmmnd "Fuel Cell System Coolant Fan 3 Percent Speed Command: Speed command to the Fuel Cell System Coolant Fan 3 in percentage of maximum speed.Note: Both Speed Command and Percent Speed Command cannot be used at the same time.  Always set the unused speed ...";
CM_ SG_ 2566519550 FCSstCtF3CdEdddIttSppt "Fuel Cell System Coolant Fan 3 Command Embedded Integrity Support: Indicates that SPN 23555 (Fuel Cell System Coolant Fan 3 Command CRC) and SPN 23554 (Fuel Cell System Coolant Fan 3 Command Counter) are supported by the sender.00b = Fuel Cell System...";
CM_ SG_ 2566519550 FlCllSstmClntFn3CmmndCntr "Fuel Cell System Coolant Fan 3 Command Counter: The message counter is used to detect situations where the transmitting ECU malfunction repeats the same frame all the time. The receiver of the information may use the counter parameter to detect this ...";
CM_ SG_ 2566519550 FlCllSstmClntFn3CmmndCr "Fuel Cell System Coolant Fan 3 Command CRC: The CRC is defined as follows:  - Length: 8 bits  - Polynomial: x^8+x^5+x^3+x^2+x+1  - Initial Value: FFh  - Input Data Reflection: Not reflected  - Result Data Reflection: Not reflected  - XOR value: FFhSA...";
CM_ BO_ 2566519806 "Fuel Cell System Coolant Fan 3 Status 1";
CM_ SG_ 2566519806 FlCllSstmClntFn3MtrSpdStts "Fuel Cell System Coolant Fan 3 Motor Speed Status: Enable and direction status of the Fuel Cell System Coolant Fan 3 system or component.  This parameter is used with SPN 23269 (Fuel Cell System Coolant Fan 3 Motor Speed).00b = Accessory Motor Off01b...";
CM_ SG_ 2566519806 FCSstCtF3CtSttsRsCd "Fuel Cell System Coolant Fan 3 Controller Status Reason Code: Provides the reason code describing the unique failure of the Fuel Cell System Coolant Fan 3 system or component.If a detailed reason code is not used by the supporting application, or thi...";
CM_ SG_ 2566519806 FCSstCtF3CtCdStts "Fuel Cell System Coolant Fan 3 Controller Command Status: Indicates the source of the speed command to the Fuel Cell System Coolant Fan 3 system or component.00b is communicated when the controller is self-controlled  (e.g. based on a temperature sen...";
CM_ SG_ 2566519806 FlCllSstmClntFn3MtrSpd "Fuel Cell System Coolant Fan 3 Motor Speed: Motor Speed of the Fuel Cell System Coolant Fan 3.  This parameter is used with SPN 23266 (Fuel Cell System Coolant Fan 3 Motor Speed Status).";
CM_ SG_ 2566519806 FlCllSstmClntFn3CntrlTmprtr "Fuel Cell System Coolant Fan 3 Control Temperature: A temperature measured and reported by the device.  It may be used for direct or remote (by another controller) control of the Fuel Cell System Coolant Fan 3.  For example, this may be the temperatu...";
CM_ SG_ 2566519806 FuelCellSystemCoolantFan3Power "Fuel Cell System Coolant Fan 3 Power: Calculated electrical power consumed by the Fuel Cell System Coolant Fan 3.";
CM_ SG_ 2566519806 FlCllSstmClntFn3SrvIndtr "Fuel Cell System Coolant Fan 3 Service Indicator: Indicates that service is required for the Fuel Cell System Coolant Fan 3 system or component.An active indication may convey a need for component replacement or periodic service.  The SPN 23267 (Fuel...";
CM_ SG_ 2566519806 FlCllSstmClntFn3OprtngStts "Fuel Cell System Coolant Fan 3 Operating Status: Indicates the operating status of the Fuel Cell System Coolant Fan 3 system or component.This parameter is used to inform other devices that this system or component is no longer performing to its oper...";
CM_ BO_ 2566520062 "Fuel Cell System Coolant Fan 4 Command";
CM_ SG_ 2566520062 FlCllSstmClntFn4EnlCmmnd "Fuel Cell System Coolant Fan 4 Enable Command: Enable and direction command to the Fuel Cell System Coolant Fan 4.00b = Accessory Motor Off01b = Accessory Motor On Normal/Default Direction10b = Accessory Motor On Reverse Direction11b = Don't Care/Tak...";
CM_ SG_ 2566520062 FlCllSstmClntFn4PwrHld "Fuel Cell System Coolant Fan 4 Power Hold: Command to allow the Fuel Cell System Coolant Fan 4 to remain alive independently of the electrical enable input to the Accessory Motor.  For example, this could allow continued device operation after the ke...";
CM_ SG_ 2566520062 FlCllSstmClntFn4SpdCmmnd "Fuel Cell System Coolant Fan 4 Speed Command: Speed command to the Fuel Cell System Coolant Fan 4.Note: Both Speed Command and Percent Speed Command cannot be used at the same time.  Always set the unused speed command to Not Available.  If both comm...";
CM_ SG_ 2566520062 FlCllSstmClntFn4PrntSpdCmmnd "Fuel Cell System Coolant Fan 4 Percent Speed Command: Speed command to the Fuel Cell System Coolant Fan 4 in percentage of maximum speed.Note: Both Speed Command and Percent Speed Command cannot be used at the same time.  Always set the unused speed ...";
CM_ SG_ 2566520062 FCSstCtF4CdEdddIttSppt "Fuel Cell System Coolant Fan 4 Command Embedded Integrity Support: Indicates that SPN 23558 (Fuel Cell System Coolant Fan 4 Command CRC) and SPN 23557 (Fuel Cell System Coolant Fan 4 Command Counter) are supported by the sender.00b = Fuel Cell System...";
CM_ SG_ 2566520062 FlCllSstmClntFn4CmmndCntr "Fuel Cell System Coolant Fan 4 Command Counter: The message counter is used to detect situations where the transmitting ECU malfunction repeats the same frame all the time. The receiver of the information may use the counter parameter to detect this ...";
CM_ SG_ 2566520062 FlCllSstmClntFn4CmmndCr "Fuel Cell System Coolant Fan 4 Command CRC: The CRC is defined as follows:  - Length: 8 bits  - Polynomial: x^8+x^5+x^3+x^2+x+1  - Initial Value: FFh  - Input Data Reflection: Not reflected  - Result Data Reflection: Not reflected  - XOR value: FFhSA...";
CM_ BO_ 2566520318 "Fuel Cell System Coolant Fan 4 Status 1";
CM_ SG_ 2566520318 FlCllSstmClntFn4MtrSpdStts "Fuel Cell System Coolant Fan 4 Motor Speed Status: Enable and direction status of the Fuel Cell System Coolant Fan 4 system or component.  This parameter is used with SPN 23286 (Fuel Cell System Coolant Fan 4 Motor Speed).00b = Accessory Motor Off01b...";
CM_ SG_ 2566520318 FCSstCtF4CtSttsRsCd "Fuel Cell System Coolant Fan 4 Controller Status Reason Code: Provides the reason code describing the unique failure of the Fuel Cell System Coolant Fan 4 system or component.If a detailed reason code is not used by the supporting application, or thi...";
CM_ SG_ 2566520318 FCSstCtF4CtCdStts "Fuel Cell System Coolant Fan 4 Controller Command Status: Indicates the source of the speed command to the Fuel Cell System Coolant Fan 4 system or component.00b is communicated when the controller is self-controlled  (e.g. based on a temperature sen...";
CM_ SG_ 2566520318 FlCllSstmClntFn4MtrSpd "Fuel Cell System Coolant Fan 4 Motor Speed: Motor Speed of the Fuel Cell System Coolant Fan 4.  This parameter is used with SPN 23283 (Fuel Cell System Coolant Fan 4 Motor Speed Status).";
CM_ SG_ 2566520318 FlCllSstmClntFn4CntrlTmprtr "Fuel Cell System Coolant Fan 4 Control Temperature: A temperature measured and reported by the device.  It may be used for direct or remote (by another controller) control of the Fuel Cell System Coolant Fan 4.  For example, this may be the temperatu...";
CM_ SG_ 2566520318 FuelCellSystemCoolantFan4Power "Fuel Cell System Coolant Fan 4 Power: Calculated electrical power consumed by the Fuel Cell System Coolant Fan 4.";
CM_ SG_ 2566520318 FlCllSstmClntFn4SrvIndtr "Fuel Cell System Coolant Fan 4 Service Indicator: Indicates that service is required for the Fuel Cell System Coolant Fan 4 system or component.An active indication may convey a need for component replacement or periodic service.  The SPN 23284 (Fuel...";
CM_ SG_ 2566520318 FlCllSstmClntFn4OprtngStts "Fuel Cell System Coolant Fan 4 Operating Status: Indicates the operating status of the Fuel Cell System Coolant Fan 4 system or component.This parameter is used to inform other devices that this system or component is no longer performing to its oper...";
CM_ BO_ 2566520574 "APIs Supported";
CM_ SG_ 2566520574 EvApiId "EV API ID: ID value assigned to an API.If the SPN23215 (EV API Manufacturer ID) is zero, then this parameter will have one of the following values:0: Reserved for SAE J3271 CAN EVSE to EV API  1 - 250: Reserved for future useFor proprietary APIs, (i....";
CM_ SG_ 2566520574 EvApiManufacturerId "EV API Manufacturer ID: Manufacturer ID who maintains and publishes the API. A value of zero is reserved for standard interfaces whose API IDs, SPN 23214 (EV API ID), are managed by SAE.For proprietary API IDs, SPN 23214 (EV API ID), the Manufacturer...";
CM_ SG_ 2566520574 EvApiSupportedRoles "EV API Supported Roles: An API may have defined roles for the participants (e.g. Client-Server). This field indicates the roles supported by the CA. If an API has defined roles, then support for at least one of those roles must be indicated.0000b - T...";
CM_ SG_ 2566520574 EvApiMajorVersion "EV API Major Version: Major version for the API. APIs with differing major versions are not compatible.SP Position in PG  4, 12, .... 8n-4";
CM_ SG_ 2566520574 EvApiMinorVersion "EV API Minor Version: Minor version for the API.SP Position in PG  5, 13, .... 8n-3";
CM_ SG_ 2566520574 EvApiMinorVersionMinimum "EV API Minor Version Minimum: Minimum supported minor version of the this API that is compatible with the CA sending this PG.SP Position in PG  6, 14, .... 8n-2";
CM_ SG_ 2566520574 EvApiGrouping "EV API Grouping: Group number indicating sets of APIs that are mutually exclusive. Only one of the APIs from a set can be selected at a time.For example, an EVSE may support several different charging APIs, or charging API versions, but the EV can on...";
CM_ SG_ 2566520574 EvApiActiveByDefault "EV API Active By Default: If set, then this API will be active by default.Only one API in a API Grouping may have this bit set.SP Position in PG  7.5, 15.5, .... (8n-1).5";
CM_ BO_ 2566520830 "Fuel Cell System Configuration";
CM_ SG_ 2566520830 FuelCellSystemConfigurationCrc "Fuel Cell System Configuration CRC: The CRC is defined as follows: - Length: 8 bits- Polynomial: x^8+x^5+x^3+x^2+x+1- Initial Value: FFh- Input Data Reflection: Not reflected- Result Data Reflection: Not reflected- XOR value: FFh SAE makes no claim o...";
CM_ SG_ 2566520830 FlCllSstmCnfgrtnCntr "Fuel Cell System Configuration Counter: The message counter is used to detect situations where the transmitting ECU malfunction repeats the same frame all the time. The receiver of the information may use the counter parameter to detect this situatio...";
CM_ SG_ 2566520830 FuelCellSystemReferencePower "Fuel Cell System Reference Power: This parameter is the 100% reference value for all defined fuel cell system power parameters, including but not limited to SPN 23151 (Fuel Cell System Net Output Command) and SPN 23155 (Fuel Cell System Net Power).  ...";
CM_ SG_ 2566520830 FuelCellSystemReferenceCurrent "Fuel Cell System Reference Current: This parameter is the 100% reference value for all defined fuel cell system current parameters, including but not limited to SPN 23151 (Fuel Cell System Net Output Command) and SPN 23156 (Fuel Cell System Net Curre...";
CM_ SG_ 2566520830 FuelCellSystemReferenceVoltage "Fuel Cell System Reference Voltage: This parameter is the 100% reference value for all defined fuel cell system voltage parameters, including but not limited to SPN 23157 (Fuel Cell System Voltage).  It is only defined once and doesn't change.";
CM_ BO_ 2566521086 "Fuel Cell System Coolant Information 1";
CM_ SG_ 2566521086 FlCllSstmClntInltTmprtrStpnt "Fuel Cell System Coolant Inlet Temperature Setpoint: Temperature setpoint of coolant in the inlet coolant port of the entire fuel cell system cooling system. ";
CM_ SG_ 2566521086 FlCllSstmClntInltTmprtr "Fuel Cell System Coolant Inlet Temperature: Temperature of coolant found in the inlet coolant port of the entire fuel cell system cooling system. ";
CM_ SG_ 2566521086 FlCllStkClntInltTmprtr "Fuel Cell Stack Coolant Inlet Temperature: Temperature of coolant found in the inlet coolant port of fuel cell stack";
CM_ SG_ 2566521086 FlCllStkClntOtltTmprtr "Fuel Cell Stack Coolant Outlet Temperature: Temperature of coolant found in the outlet coolant port of fuel cell stack";
CM_ BO_ 2566521342 "Fuel Cell System Coolant Information 2";
CM_ SG_ 2566521342 FuelCellSystemCoolantLevel "Fuel Cell System Coolant Level: Ratio of volume of liquid found in fuel cell system coolant tank to total coolant tank volume.";
CM_ SG_ 2566521342 FlCllStkInltClntAsltPrssr "Fuel Cell Stack Inlet Coolant Absolute Pressure: Absolute pressure of coolant at the inlet port of the fuel cell stack.";
CM_ SG_ 2566521342 FuelCellSystemCoolantFlowRate "Fuel Cell System Coolant Flow Rate: Flow rate of the fuel cell system coolant.  This is typically measured at the inlet of the fuel cell system radiator.See SPN 23776 (Fuel Cell System Coolant Flow Rate (Extended Range)) for alternate range and resol...";
CM_ SG_ 2566521342 FuelCellStackCoolantFlowRate "Fuel Cell Stack Coolant Flow Rate: Flow rate of the coolant through the fuel cell stack.See SPN 23777 (Fuel Cell Stack Coolant Flow Rate (Extended Range)) for alternate range and resolution.";
CM_ SG_ 2566521342 FlCllSstmClntCndtvt "Fuel Cell System Coolant Conductivity: A measure of the conductivity of the coolant used in the fuel cell system.";
CM_ BO_ 2566095102 "High Voltage Energy Storage System Fan Status 2";
CM_ SG_ 2566095102 HvessFanVoltage "HVESS Fan Voltage: The voltage level of the electrical bus that is utilized by this device as the power source/sink for generating motor torque, as measured at the input of this device.  Note that one design alternative for this device utilizes a fir...";
CM_ SG_ 2566095102 HvessFanCurrent "HVESS Fan Current: The current in or out of this device with respect to the electrical bus that is utilized by this device as the power source/sink for generating motor torque.  This parameter should be synchronized with SPN 23490 (HVESS Fan Voltage)...";
CM_ SG_ 2566095102 HvessFanHvilStatus "HVESS Fan HVIL Status: High Voltage Interlock Loop (HVIL) state, as measured by this device.00b = HVIL Closed01b = HVIL Open10b = Error11b = Not Available";
CM_ SG_ 2566095102 HvessFanStatus2Instance "HVESS Fan Status 2 Instance: Indicates the instance of the SPs in this PG that is providing status in systems controlled by a master ECU.0000b = Instance 10001b = Instance 20010b = Instance 30011b = Instance 40100b = Instance 50101b = Instance 60110b...";
CM_ SG_ 2566095102 HvessFanPercentSpeedStatus "HVESS Fan Percent Speed Status: Enable and direction status of the HVESS Fan system or component.  This parameter is used with SPN 23495 (HVESS Fan Percent Speed).00b = Accessory Motor Off01b = Accessory Motor On - Normal, Forward, or Default Directi...";
CM_ SG_ 2566095102 HvessFanPercentSpeed "HVESS Fan Percent Speed: Speed of the HVESS Fan in percentage of maximum speed.  This parameter is used with SPN 23494 (HVESS Fan Percent Speed Status).";
CM_ BO_ 2566511614 "EVSE Status 2";
CM_ SG_ 2566511614 EvseTempSensorType "EVSE Temp Sensor Type: Indicates the type of sensor fittings to the inlet connector.0000b = No sensor fitted0001b = RTD PT1000, ref DIN/EN/IEC 607510010b = NTC Thermistor, 10K at 25°C. (refer manufacturer for exact characteristics) 0011b = PTC Thermi...";
CM_ SG_ 2566511614 EvseConnectorTemperatureStatus "EVSE Connector Temperature Status: Indicates the temperature status of the connector.00b = Temperature in normal operational range01b = Temperature outside allowed operational range for the connector10b = Error, unable to determine the connector temp...";
CM_ SG_ 2566511614 EvChrgngInltCnntrTmprtr "EV Charging Inlet Connector Temperature: Temperature reading at the vehicle inlet connector.The value here is the same as SPN 12934 in PG EVCCD1.";
CM_ SG_ 2566511614 EvCItCtTptSsRsst "EV Charging Inlet Connector Temperature Sensor Resistance: Resistance of the inlet temperature sensor(s).Some EV charging inlet connectors have multiple temperature sensors connected in a series or parallel combination. It is not always  possible to ...";
CM_ BO_ 2566645502 "High Voltage Energy Storage System Fan Commands";
CM_ SG_ 2566645502 HvessFanEnableCommand "HVESS Fan Enable Command: Enable and direction command to this HVES fan.00b = Fan Off01b = Fan On Normal/Default Direction10b = Fan On Reverse Direction11b = Don't Care/Take no action";
CM_ SG_ 2566645502 HvessFanPowerHold "HVESS Fan Power Hold: Command to allow this HVES fan to remain alive independently of the electrical enable input to the fan.  For example, this could allow continued device operation after the keyswitch has turned off.00b = Power Hold Disabled01b = ...";
CM_ SG_ 2566645502 HvessFanSpeedCommand "HVESS Fan Speed Command: Speed command to this HVES fan.Note: Both SPN 8386 (HVESS Fan Speed Command) and SPN 8387 (HVESS Fan Percent Speed Command) cannot be used at the same time.  Always set the unused speed command to Not Available.  If both comm...";
CM_ SG_ 2566645502 HvessFanPercentSpeedCommand "HVESS Fan Percent Speed Command: Speed command to this HVES fan in percentage of maximum speed.Note: Both SPN 8386 (HVESS Fan Speed Command) and SPN 8387 (HVESS Fan Percent Speed Command) cannot be used at the same time.  Always set the unused speed ...";
CM_ SG_ 2566645502 HvessFanInstance1 "HVESS Fan Instance 1: Indicates the HVES Fan Instance that is being commanded.  Multiple instances can be controlled with the same command PG by setting each unique instance parameter to 0b.0b = Command applied to this Fan Instance1b = No Command app...";
CM_ SG_ 2566645502 HvessFanInstance2 "HVESS Fan Instance 2: Indicates the HVES Fan Instance that is being commanded.  Multiple instances can be controlled with the same command PG by setting each unique instance parameter to 0b.0b = Command applied to this Fan Instance1b = No Command app...";
CM_ SG_ 2566645502 HvessFanInstance3 "HVESS Fan Instance 3: Indicates the HVES Fan Instance that is being commanded.  Multiple instances can be controlled with the same command PG by setting each unique instance parameter to 0b.0b = Command applied to this Fan Instance1b = No Command app...";
CM_ SG_ 2566645502 HvessFanInstance4 "HVESS Fan Instance 4: Indicates the HVES Fan Instance that is being commanded.  Multiple instances can be controlled with the same command PG by setting each unique instance parameter to 0b.0b = Command applied to this Fan Instance1b = No Command app...";
CM_ SG_ 2566645502 HvessFanInstance5 "HVESS Fan Instance 5: Indicates the HVES Fan Instance that is being commanded.  Multiple instances can be controlled with the same command PG by setting each unique instance parameter to 0b.0b = Command applied to this Fan Instance1b = No Command app...";
CM_ SG_ 2566645502 HvessFanInstance6 "HVESS Fan Instance 6: Indicates the HVES Fan Instance that is being commanded.  Multiple instances can be controlled with the same command PG by setting each unique instance parameter to 0b.0b = Command applied to this Fan Instance1b = No Command app...";
CM_ SG_ 2566645502 HvessFanInstance7 "HVESS Fan Instance 7: Indicates the HVES Fan Instance that is being commanded.  Multiple instances can be controlled with the same command PG by setting each unique instance parameter to 0b.0b = Command applied to this Fan Instance1b = No Command app...";
CM_ SG_ 2566645502 HvessFanInstance8 "HVESS Fan Instance 8: Indicates the HVES Fan Instance that is being commanded.  Multiple instances can be controlled with the same command PG by setting each unique instance parameter to 0b.0b = Command applied to this Fan Instance1b = No Command app...";
CM_ SG_ 2566645502 HvessFanInstance9 "HVESS Fan Instance 9: Indicates the HVES Fan Instance that is being commanded.  Multiple instances can be controlled with the same command PG by setting each unique instance parameter to 0b.0b = Command applied to this Fan Instance1b = No Command app...";
CM_ SG_ 2566645502 HvessFanInstance10 "HVESS Fan Instance 10: Indicates the HVES Fan Instance that is being commanded.  Multiple instances can be controlled with the same command PG by setting each unique instance parameter to 0b.0b = Command applied to this Fan Instance1b = No Command ap...";
CM_ SG_ 2566645502 HvessFanInstance11 "HVESS Fan Instance 11: Indicates the HVES Fan Instance that is being commanded.  Multiple instances can be controlled with the same command PG by setting each unique instance parameter to 0b.0b = Command applied to this Fan Instance1b = No Command ap...";
CM_ SG_ 2566645502 HvessFanInstance12 "HVESS Fan Instance 12: Indicates the HVES Fan Instance that is being commanded.  Multiple instances can be controlled with the same command PG by setting each unique instance parameter to 0b.0b = Command applied to this Fan Instance1b = No Command ap...";
CM_ SG_ 2566645502 HvessFanInstance13 "HVESS Fan Instance 13: Indicates the HVES Fan Instance that is being commanded.  Multiple instances can be controlled with the same command PG by setting each unique instance parameter to 0b.0b = Command applied to this Fan Instance1b = No Command ap...";
CM_ SG_ 2566645502 HvessFanInstance14 "HVESS Fan Instance 14: Indicates the HVES Fan Instance that is being commanded.  Multiple instances can be controlled with the same command PG by setting each unique instance parameter to 0b.0b = Command applied to this Fan Instance1b = No Command ap...";
CM_ SG_ 2566645502 HvessFanInstance15 "HVESS Fan Instance 15: Indicates the HVES Fan Instance that is being commanded.  Multiple instances can be controlled with the same command PG by setting each unique instance parameter to 0b.0b = Command applied to this Fan Instance1b = No Command ap...";
CM_ SG_ 2566645502 HVtEStSstFCdsEdddIttSppt "High Voltage Energy Storage System Fan Commands Embedded Integrity Support: Indicates that SPN 23546 (High Voltage Energy Storage System Fan Commands CRC) and SPN 23545 (High Voltage Energy Storage System Fan Commands Counter) are supported by the se...";
CM_ SG_ 2566645502 HghVltgEnrgStrgSstmFnCmmndsCntr "High Voltage Energy Storage System Fan Commands Counter: The message counter is used to detect situations where the transmitting ECU malfunction repeats the same frame all the time. The receiver of the information may use the counter parameter to det...";
CM_ SG_ 2566645502 HghVltgEnrgStrgSstmFnCmmndsCr "High Voltage Energy Storage System Fan Commands CRC: The CRC is defined as follows:  - Length: 8 bits  - Polynomial: x^8+x^5+x^3+x^2+x+1  - Initial Value: FFh  - Input Data Reflection: Not reflected  - Result Data Reflection: Not reflected  - XOR val...";
CM_ BO_ 2566504446 "Enrichment Information";
CM_ SG_ 2566504446 TripEnrichmentPercentTime "Trip Enrichment Percent Time: This parameter reports the percentage of time spent in enrichment (including but not limited to enrichment due to accelerator pedal, engine protection and after-treatment protection) while the engine is warm during this ...";
CM_ SG_ 2566504446 TrpEnrhmntPrntTmDTAlrtrPdl "Trip Enrichment Percent Time due to Accelerator Pedal: This parameter reports the time spent in enrichment due to the accelerator pedal while the engine is warm during this operation cycle.  This parameter resets when power is cycled to the system (e...";
CM_ SG_ 2566504446 TrpEnrhmntPrntTmDTEngnPrttn "Trip Enrichment Percent Time due to Engine Protection: This parameter reports the time spent in enrichment due to engine protection while the engine is warm during this operation cycle.  This parameter resets when power is cycled to the system (e.g.,...";
CM_ SG_ 2566504446 TpEtPtTDTAttttPtt "Trip Enrichment Percent Time due to Aftertreatment Protection: This parameter reports the time spent in enrichment due to aftertreatment protection while the engine is warm during this operation cycle.  This parameter resets when power is cycled to t...";
CM_ SG_ 2566504446 LifetimeEnrichmentPercentTime "Lifetime Enrichment Percent Time: This parameter reports the time spent in enrichment (including but not limited to enrichment due to accelerator pedal, engine protection and after-treatment protection) while the engine is warm over the lifetime of t...";
CM_ SG_ 2566504446 LftmEnrhmntPrntTmDTAlrtrPdl "Lifetime Enrichment Percent Time due to Accelerator Pedal: This parameter reports the total time spent in enrichment due to the accelerator pedal while the engine is warm over the lifetime of the system.Refer to the PG description of PGN 63935 (Enric...";
CM_ SG_ 2566504446 LftmEnrhmntPrntTmDTEngnPrttn "Lifetime Enrichment Percent Time due to Engine Protection: This parameter reports the total time spent in enrichment due to engine protection while the engine is warm over the lifetime of the system.Refer to the PG description of PGN 63935 (Enrichmen...";
CM_ SG_ 2566504446 LtEtPtTDTAttttPtt "Lifetime Enrichment Percent Time due to Aftertreatment Protection: This parameter reports the total time spent in enrichment due to the aftertreatment protection while the engine is warm over the lifetime of the system.Refer to the PG description of ...";
CM_ BO_ 2566504702 "Fuel Cell System Voltage Limit Command";
CM_ SG_ 2566504702 FcsvlcCrc "FCSVLC CRC: The CRC is defined as follows: - Length: 8 bits- Polynomial: x^8+x^5+x^3+x^2+x+1- Initial Value: FFh- Input Data Reflection: Not reflected- Result Data Reflection: Not reflected- XOR value: FFh SAE makes no claim of the functional safety ...";
CM_ SG_ 2566504702 FcsvlcCounter "FCSVLC Counter: The message counter is used to detect situations where the transmitting ECU malfunction repeats the same frame all the time. The receiver of the information may use the counter parameter to detect this situation. The transmitting devi...";
CM_ SG_ 2566504702 FlCllSstmNmnlVltgCmmnd "Fuel Cell System Nominal Voltage Command: This is the nominal operating voltage of the fuel cell system. It is expressed as a percentage of the reference voltage in SPN 23146  (Fuel Cell System Reference Voltage). ";
CM_ SG_ 2566504702 FlCllSstmMnmmOprtngVltgCmmnd "Fuel Cell System Minimum Operating Voltage Command: The commanded minimum voltage level for the fuel cell system. It is expressed as a percentage of the reference voltage in SPN 23146  (Fuel Cell System Reference Voltage). ";
CM_ SG_ 2566504702 FlCllSstmMxmmOprtngVltgCmmnd "Fuel Cell System Maximum Operating Voltage Command: The commanded maximum voltage level for the fuel cell system. It is expressed as a percentage of the reference voltage in SPN 23146  (Fuel Cell System Reference Voltage).";
CM_ BO_ 2566505470 "Auxiliary Input/Output Status 17";
CM_ SG_ 2566505470 AuxiliaryIOChannel62 "Auxiliary I/O Channel #62: Identifies the current value of auxiliary input/output channels that are configured uniquely per application.";
CM_ SG_ 2566505470 AuxiliaryIOChannel61 "Auxiliary I/O Channel #61: Identifies the current value of auxiliary input/output channels that are configured uniquely per application.";
CM_ SG_ 2566505470 AuxiliaryIOChannel60 "Auxiliary I/O Channel #60: Identifies the current value of auxiliary input/output channels that are configured uniquely per application.";
CM_ SG_ 2566505470 AuxiliaryIOChannel59 "Auxiliary I/O Channel #59: Identifies the current value of auxiliary input/output channels that are configured uniquely per application.";
CM_ BO_ 2566505726 "Auxiliary Input/Output Status 16";
CM_ SG_ 2566505726 AuxiliaryIOChannel58 "Auxiliary I/O Channel #58: Identifies the current value of auxiliary input/output channels that are configured uniquely per application.";
CM_ SG_ 2566505726 AuxiliaryIOChannel57 "Auxiliary I/O Channel #57: Identifies the current value of auxiliary input/output channels that are configured uniquely per application.";
CM_ SG_ 2566505726 AuxiliaryIOChannel56 "Auxiliary I/O Channel #56: Identifies the current value of auxiliary input/output channels that are configured uniquely per application.";
CM_ SG_ 2566505726 AuxiliaryIOChannel55 "Auxiliary I/O Channel #55: Identifies the current value of auxiliary input/output channels that are configured uniquely per application.";
CM_ BO_ 2566505982 "Auxiliary Input/Output Status 15";
CM_ SG_ 2566505982 AuxiliaryIOChannel54 "Auxiliary I/O Channel #54: Identifies the current value of auxiliary input/output channels that are configured uniquely per application.";
CM_ SG_ 2566505982 AuxiliaryIOChannel53 "Auxiliary I/O Channel #53: Identifies the current value of auxiliary input/output channels that are configured uniquely per application.";
CM_ SG_ 2566505982 AuxiliaryIOChannel52 "Auxiliary I/O Channel #52: Identifies the current value of auxiliary input/output channels that are configured uniquely per application.";
CM_ SG_ 2566505982 AuxiliaryIOChannel51 "Auxiliary I/O Channel #51: Identifies the current value of auxiliary input/output channels that are configured uniquely per application.";
CM_ BO_ 2566506238 "Auxiliary Input/Output Status 14";
CM_ SG_ 2566506238 AuxiliaryIOChannel50 "Auxiliary I/O Channel #50: Identifies the current value of auxiliary input/output channels that are configured uniquely per application.";
CM_ SG_ 2566506238 AuxiliaryIOChannel49 "Auxiliary I/O Channel #49: Identifies the current value of auxiliary input/output channels that are configured uniquely per application.";
CM_ SG_ 2566506238 AuxiliaryIOChannel48 "Auxiliary I/O Channel #48: Identifies the current value of auxiliary input/output channels that are configured uniquely per application.";
CM_ SG_ 2566506238 AuxiliaryIOChannel47 "Auxiliary I/O Channel #47: Identifies the current value of auxiliary input/output channels that are configured uniquely per application.";
CM_ BO_ 2566506494 "Auxiliary Input/Output Status 13";
CM_ SG_ 2566506494 AuxiliaryIOChannel46 "Auxiliary I/O Channel #46: Identifies the current value of auxiliary input/output channels that are configured uniquely per application.";
CM_ SG_ 2566506494 AuxiliaryIOChannel45 "Auxiliary I/O Channel #45: Identifies the current value of auxiliary input/output channels that are configured uniquely per application.";
CM_ SG_ 2566506494 AuxiliaryIOChannel44 "Auxiliary I/O Channel #44: Identifies the current value of auxiliary input/output channels that are configured uniquely per application.";
CM_ SG_ 2566506494 AuxiliaryIOChannel43 "Auxiliary I/O Channel #43: Identifies the current value of auxiliary input/output channels that are configured uniquely per application.";
CM_ BO_ 2566506750 "Auxiliary Input/Output Status 12";
CM_ SG_ 2566506750 AuxiliaryIOChannel42 "Auxiliary I/O Channel #42: Identifies the current value of auxiliary input/output channels that are configured uniquely per application.";
CM_ SG_ 2566506750 AuxiliaryIOChannel41 "Auxiliary I/O Channel #41: Identifies the current value of auxiliary input/output channels that are configured uniquely per application.";
CM_ SG_ 2566506750 AuxiliaryIOChannel40 "Auxiliary I/O Channel #40: Identifies the current value of auxiliary input/output channels that are configured uniquely per application.";
CM_ SG_ 2566506750 AuxiliaryIOChannel39 "Auxiliary I/O Channel #39: Identifies the current value of auxiliary input/output channels that are configured uniquely per application.";
CM_ BO_ 2566507006 "Auxiliary Input/Output Status 11";
CM_ SG_ 2566507006 AuxiliaryIOChannel38 "Auxiliary I/O Channel #38: Identifies the current value of auxiliary input/output channels that are configured uniquely per application.";
CM_ SG_ 2566507006 AuxiliaryIOChannel37 "Auxiliary I/O Channel #37: Identifies the current value of auxiliary input/output channels that are configured uniquely per application.";
CM_ SG_ 2566507006 AuxiliaryIOChannel36 "Auxiliary I/O Channel #36: Identifies the current value of auxiliary input/output channels that are configured uniquely per application.";
CM_ SG_ 2566507006 AuxiliaryIOChannel35 "Auxiliary I/O Channel #35: Identifies the current value of auxiliary input/output channels that are configured uniquely per application.";
CM_ BO_ 2566507262 "Auxiliary Input/Output Status 10";
CM_ SG_ 2566507262 AuxiliaryIOChannel34 "Auxiliary I/O Channel #34: Identifies the current value of auxiliary input/output channels that are configured uniquely per application.";
CM_ SG_ 2566507262 AuxiliaryIOChannel33 "Auxiliary I/O Channel #33: Identifies the current value of auxiliary input/output channels that are configured uniquely per application.";
CM_ SG_ 2566507262 AuxiliaryIOChannel32 "Auxiliary I/O Channel #32: Identifies the current value of auxiliary input/output channels that are configured uniquely per application.";
CM_ SG_ 2566507262 AuxiliaryIOChannel31 "Auxiliary I/O Channel #31: Identifies the current value of auxiliary input/output channels that are configured uniquely per application.";
CM_ BO_ 2566507518 "Auxiliary Input/Output Status 9";
CM_ SG_ 2566507518 AuxiliaryIOChannel30 "Auxiliary I/O Channel #30: Identifies the current value of auxiliary input/output channels that are configured uniquely per application.";
CM_ SG_ 2566507518 AuxiliaryIOChannel29 "Auxiliary I/O Channel #29: Identifies the current value of auxiliary input/output channels that are configured uniquely per application.";
CM_ SG_ 2566507518 AuxiliaryIOChannel28 "Auxiliary I/O Channel #28: Identifies the current value of auxiliary input/output channels that are configured uniquely per application.";
CM_ SG_ 2566507518 AuxiliaryIOChannel27 "Auxiliary I/O Channel #27: Identifies the current value of auxiliary input/output channels that are configured uniquely per application.";
CM_ BO_ 2566507774 "Auxiliary Input/Output Status 8";
CM_ SG_ 2566507774 AuxiliaryIOChannel26 "Auxiliary I/O Channel #26: Identifies the current value of auxiliary input/output channels that are configured uniquely per application.";
CM_ SG_ 2566507774 AuxiliaryIOChannel25 "Auxiliary I/O Channel #25: Identifies the current value of auxiliary input/output channels that are configured uniquely per application.";
CM_ SG_ 2566507774 AuxiliaryIOChannel24 "Auxiliary I/O Channel #24: Identifies the current value of auxiliary input/output channels that are configured uniquely per application.";
CM_ SG_ 2566507774 AuxiliaryIOChannel23 "Auxiliary I/O Channel #23: Identifies the current value of auxiliary input/output channels that are configured uniquely per application.";
CM_ BO_ 2633616894 "Aftertreatment System Information 8";
CM_ SG_ 2633616894 AftrtrtmntDslExhstFldEnm "Aftertreatment Diesel Exhaust Fluid Economy: Vehicle distance traveled divided by DEF consumed since the last reset via SPN 23394 (Aftertreatment Diesel Exhaust Fluid Reset).Note: A parameter specific indicator value of FB00h indicates that this para...";
CM_ SG_ 2633616894 AftrtrtmntDslExhstFldLftmEnm "Aftertreatment Diesel Exhaust Fluid Lifetime Economy: Vehicle distance traveled divided by DEF consumed for the lifetime of the vehicle.  Note: A parameter specific indicator value of FB00h indicates that this parameter is supported, but an amount su...";
CM_ BO_ 2566508286 "Brake Temperature 6";
CM_ SG_ 2566508286 BrkTmprtrRrAxl10LftWhl "Brake Temperature, Rear Axle #10, Left Wheel: The temperature of the brake for the left wheel on the rear axle #10.";
CM_ SG_ 2566508286 BrkTmprtrRrAxl10RghtWhl "Brake Temperature, Rear Axle #10, Right Wheel: The temperature of the brake for the right wheel on the rear axle #10.";
CM_ BO_ 2566508542 "Brake Temperature 5";
CM_ SG_ 2566508542 BrkTmprtrRrAxl8LftWhl "Brake Temperature, Rear Axle #8, Left Wheel: The temperature of the brake for the left wheel on the rear axle #8.";
CM_ SG_ 2566508542 BrkTmprtrRrAxl8RghtWhl "Brake Temperature, Rear Axle #8, Right Wheel: The temperature of the brake for the right wheel on the rear axle #8.";
CM_ SG_ 2566508542 BrkTmprtrRrAxl9LftWhl "Brake Temperature, Rear Axle #9, Left Wheel: The temperature of the brake for the left wheel on the rear axle #9.";
CM_ SG_ 2566508542 BrkTmprtrRrAxl9RghtWhl "Brake Temperature, Rear Axle #9, Right Wheel: The temperature of the brake for the right wheel on the rear axle #9.";
CM_ BO_ 2566508798 "Brake Temperature 4";
CM_ SG_ 2566508798 BrkTmprtrRrAxl6LftWhl "Brake Temperature, Rear Axle #6, Left Wheel: The temperature of the brake for the left wheel on the rear axle #6.";
CM_ SG_ 2566508798 BrkTmprtrRrAxl6RghtWhl "Brake Temperature, Rear Axle #6, Right Wheel: The temperature of the brake for the right wheel on the rear axle #6.";
CM_ SG_ 2566508798 BrkTmprtrRrAxl7LftWhl "Brake Temperature, Rear Axle #7, Left Wheel: The temperature of the brake for the left wheel on the rear axle #7.";
CM_ SG_ 2566508798 BrkTmprtrRrAxl7RghtWhl "Brake Temperature, Rear Axle #7, Right Wheel: The temperature of the brake for the right wheel on the rear axle #7.";
CM_ BO_ 2566509054 "Brake Temperature 3";
CM_ SG_ 2566509054 BrkTmprtrRrAxl4LftWhl "Brake Temperature, Rear Axle #4, Left Wheel: The temperature of the brake for the left wheel on the rear axle #4.";
CM_ SG_ 2566509054 BrkTmprtrRrAxl4RghtWhl "Brake Temperature, Rear Axle #4, Right Wheel: The temperature of the brake for the right wheel on the rear axle #4.";
CM_ SG_ 2566509054 BrkTmprtrRrAxl5LftWhl "Brake Temperature, Rear Axle #5, Left Wheel: The temperature of the brake for the left wheel on the rear axle #5.";
CM_ SG_ 2566509054 BrkTmprtrRrAxl5RghtWhl "Brake Temperature, Rear Axle #5, Right Wheel: The temperature of the brake for the right wheel on the rear axle #5.";
CM_ BO_ 2566509310 "Brake Temperature 2";
CM_ SG_ 2566509310 BrkTmprtrRrAxl2LftWhl "Brake Temperature, Rear Axle #2, Left Wheel: The temperature of the brake for the left wheel on the rear axle #2.";
CM_ SG_ 2566509310 BrkTmprtrRrAxl2RghtWhl "Brake Temperature, Rear Axle #2, Right Wheel: The temperature of the brake for the right wheel on the rear axle #2.";
CM_ SG_ 2566509310 BrkTmprtrRrAxl3LftWhl "Brake Temperature, Rear Axle #3, Left Wheel: The temperature of the brake for the left wheel on the rear axle #3.";
CM_ SG_ 2566509310 BrkTmprtrRrAxl3RghtWhl "Brake Temperature, Rear Axle #3, Right Wheel: The temperature of the brake for the right wheel on the rear axle #3.";
CM_ BO_ 2566509566 "Brake Temperature 1";
CM_ SG_ 2566509566 BrkTmprtrFrntAxlLftWhl "Brake Temperature, Front Axle, Left Wheel: The temperature of the brake for the left wheel on the front axle.";
CM_ SG_ 2566509566 BrkTmprtrFrntAxlRghtWhl "Brake Temperature, Front Axle, Right Wheel: The temperature of the brake for the right wheel on the front axle.";
CM_ SG_ 2566509566 BrkTmprtrRrAxl1LftWhl "Brake Temperature, Rear Axle #1, Left Wheel: The temperature of the brake for the left wheel on the rear axle #1.";
CM_ SG_ 2566509566 BrkTmprtrRrAxl1RghtWhl "Brake Temperature, Rear Axle #1, Right Wheel: The temperature of the brake for the right wheel on the rear axle #1.";
CM_ BO_ 2633618686 "Wheel Brake Lining Remaining Information 3";
CM_ SG_ 2633618686 BrkLnngRmnngRrAxl8LftWhl "Brake Lining Remaining, Rear Axle #8, Left Wheel: The percentage of brake lining which can still be measured for the left wheel on the rear axle #8.  100% represents new brake linings, 0% represents totally worn brake linings.";
CM_ SG_ 2633618686 BrkLnngRmnngRrAxl8RghtWhl "Brake Lining Remaining, Rear Axle #8, Right Wheel: The percentage of brake lining which can still be measured for the right wheel on the rear axle #8.  100% represents new brake linings, 0% represents totally worn brake linings.";
CM_ SG_ 2633618686 BrkLnngRmnngRrAxl9LftWhl "Brake Lining Remaining, Rear Axle #9, Left Wheel: The percentage of brake lining which can still be measured for the left wheel on the rear axle #9.  100% represents new brake linings, 0% represents totally worn brake linings.";
CM_ SG_ 2633618686 BrkLnngRmnngRrAxl9RghtWhl "Brake Lining Remaining, Rear Axle #9, Right Wheel: The percentage of brake lining which can still be measured for the right wheel on the rear axle #9.  100% represents new brake linings, 0% represents totally worn brake linings.";
CM_ SG_ 2633618686 BrkLnngRmnngRrAxl10LftWhl "Brake Lining Remaining, Rear Axle #10, Left Wheel: The percentage of brake lining which can still be measured for the left wheel on the rear axle #10.  100% represents new brake linings, 0% represents totally worn brake linings.";
CM_ SG_ 2633618686 BrkLnngRmnngRrAxl10RghtWhl "Brake Lining Remaining, Rear Axle #10, Right Wheel: The percentage of brake lining which can still be measured for the right wheel on the rear axle #10.  100% represents new brake linings, 0% represents totally worn brake linings.";
CM_ BO_ 2633618942 "Wheel Brake Lining Remaining Information 2";
CM_ SG_ 2633618942 BrkLnngRmnngRrAxl4LftWhl "Brake Lining Remaining, Rear Axle #4, Left Wheel: The percentage of brake lining which can still be measured for the left wheel on the rear axle #4.  100% represents new brake linings, 0% represents totally worn brake linings.";
CM_ SG_ 2633618942 BrkLnngRmnngRrAxl4RghtWhl "Brake Lining Remaining, Rear Axle #4, Right Wheel: The percentage of brake lining which can still be measured for the right wheel on the rear axle #4.  100% represents new brake linings, 0% represents totally worn brake linings.";
CM_ SG_ 2633618942 BrkLnngRmnngRrAxl5LftWhl "Brake Lining Remaining, Rear Axle #5, Left Wheel: The percentage of brake lining which can still be measured for the left wheel on the rear axle #5.  100% represents new brake linings, 0% represents totally worn brake linings.";
CM_ SG_ 2633618942 BrkLnngRmnngRrAxl5RghtWhl "Brake Lining Remaining, Rear Axle #5, Right Wheel: The percentage of brake lining which can still be measured for the right wheel on the rear axle #5.  100% represents new brake linings, 0% represents totally worn brake linings.";
CM_ SG_ 2633618942 BrkLnngRmnngRrAxl6LftWhl "Brake Lining Remaining, Rear Axle #6, Left Wheel: The percentage of brake lining which can still be measured for the left wheel on the rear axle #6.  100% represents new brake linings, 0% represents totally worn brake linings.";
CM_ SG_ 2633618942 BrkLnngRmnngRrAxl6RghtWhl "Brake Lining Remaining, Rear Axle #6, Right Wheel: The percentage of brake lining which can still be measured for the right wheel on the rear axle #6.  100% represents new brake linings, 0% represents totally worn brake linings.";
CM_ SG_ 2633618942 BrkLnngRmnngRrAxl7LftWhl "Brake Lining Remaining, Rear Axle #7, Left Wheel: The percentage of brake lining which can still be measured for the left wheel on the rear axle #7.  100% represents new brake linings, 0% represents totally worn brake linings.";
CM_ SG_ 2633618942 BrkLnngRmnngRrAxl7RghtWhl "Brake Lining Remaining, Rear Axle #7, Right Wheel: The percentage of brake lining which can still be measured for the right wheel on the rear axle #7.  100% represents new brake linings, 0% represents totally worn brake linings.";
CM_ BO_ 2365183742 "High Voltage Bus Contactor Status 3";
CM_ SG_ 2365183742 Hvbcs3EmbeddedIntegritySupport "HVBCS3 Embedded Integrity Support: Indicates SPN 23644 (HVBCS3 CRC) and SPN 23643 (HVBCS3 Counter) are supported by the sender.00b = HVBCS3 embedded CRC and Counter are supported by the sender01b = HVBCS3 protection is supported using J1939-76 SHM10b...";
CM_ SG_ 2365183742 Hvbcs3Counter "HVBCS3 Counter: The message counter is used to detect situations where the transmitting ECU malfunction repeats the same frame all the time. The receiver of the information may use the counter parameter to detect this situation. The transmitting devi...";
CM_ SG_ 2365183742 Hvbcs3Crc "HVBCS3 CRC: The CRC is defined as follows:- Length: 8 bits- Polynomial: x^8+x^5+x^3+x^2+x+1- Initial Value: FFh- Input Data Reflection: Not reflected- Result Data Reflection: Not reflected- XOR value: FFhSAE makes no claim of the functional safety le...";
CM_ BO_ 2365183998 "High Voltage Bus Contactor Status 2";
CM_ SG_ 2365183998 Hvbcs2EmbeddedIntegritySupport "HVBCS2 Embedded Integrity Support: Indicates SPN 23641 (HVBCS2 CRC) and SPN 23640 (HVBCS2 Counter) are supported by the sender.00b = HVBCS2 embedded CRC and Counter are supported by the sender01b = HVBCS2 protection is supported using J1939-76 SHM10b...";
CM_ SG_ 2365183998 Hvbcs2Counter "HVBCS2 Counter: The message counter is used to detect situations where the transmitting ECU malfunction repeats the same frame all the time. The receiver of the information may use the counter parameter to detect this situation. The transmitting devi...";
CM_ SG_ 2365183998 Hvbcs2Crc "HVBCS2 CRC: The CRC is defined as follows:- Length: 8 bits- Polynomial: x^8+x^5+x^3+x^2+x+1- Initial Value: FFh- Input Data Reflection: Not reflected- Result Data Reflection: Not reflected- XOR value: FFhSAE makes no claim of the functional safety le...";
CM_ BO_ 2365184254 "High Voltage Bus Connection Command 2";
CM_ SG_ 2365184254 HghVltgBsIntrf25CnntCmmnd "High-Voltage Bus Interface 25 Connect Command: Command to connect the main high-voltage bus to this high-voltage bus interface instance.  00b = Open Contactor; Disconnect from high-voltage bus01b = Close Contactor; Connect to high-voltage bus10b = Re...";
CM_ SG_ 2365184254 HghVltgBsIntrf26CnntCmmnd "High-Voltage Bus Interface 26 Connect Command: Command to connect the main high-voltage bus to this high-voltage bus interface instance.  00b = Open Contactor; Disconnect from high-voltage bus01b = Close Contactor; Connect to high-voltage bus10b = Re...";
CM_ SG_ 2365184254 HghVltgBsIntrf27CnntCmmnd "High-Voltage Bus Interface 27 Connect Command: Command to connect the main high-voltage bus to this high-voltage bus interface instance.  00b = Open Contactor; Disconnect from high-voltage bus01b = Close Contactor; Connect to high-voltage bus10b = Re...";
CM_ SG_ 2365184254 HghVltgBsIntrf28CnntCmmnd "High-Voltage Bus Interface 28 Connect Command: Command to connect the main high-voltage bus to this high-voltage bus interface instance.  00b = Open Contactor; Disconnect from high-voltage bus01b = Close Contactor; Connect to high-voltage bus10b = Re...";
CM_ SG_ 2365184254 HghVltgBsIntrf29CnntCmmnd "High-Voltage Bus Interface 29 Connect Command: Command to connect the main high-voltage bus to this high-voltage bus interface instance.  00b = Open Contactor; Disconnect from high-voltage bus01b = Close Contactor; Connect to high-voltage bus10b = Re...";
CM_ SG_ 2365184254 HghVltgBsIntrf30CnntCmmnd "High-Voltage Bus Interface 30 Connect Command: Command to connect the main high-voltage bus to this high-voltage bus interface instance.  00b = Open Contactor; Disconnect from high-voltage bus01b = Close Contactor; Connect to high-voltage bus10b = Re...";
CM_ SG_ 2365184254 HghVltgBsIntrf31CnntCmmnd "High-Voltage Bus Interface 31 Connect Command: Command to connect the main high-voltage bus to this high-voltage bus interface instance.  00b = Open Contactor; Disconnect from high-voltage bus01b = Close Contactor; Connect to high-voltage bus10b = Re...";
CM_ SG_ 2365184254 HghVltgBsIntrf32CnntCmmnd "High-Voltage Bus Interface 32 Connect Command: Command to connect the main high-voltage bus to this high-voltage bus interface instance.  00b = Open Contactor; Disconnect from high-voltage bus01b = Close Contactor; Connect to high-voltage bus10b = Re...";
CM_ SG_ 2365184254 Hvbcc2EmbeddedIntegritySupport "HVBCC2 Embedded Integrity Support: Indicates SPN 23638(HVBCC2 CRC) and SPN 23637 (HVBCC2 Counter) are supported by the sender.00b = HVBCC2 embedded CRC and Counter are supported by the sender01b = HVBCC2 protection is supported using J1939-76 SHM10b ...";
CM_ SG_ 2365184254 Hvbcc2Counter "HVBCC2 Counter: The message counter is used to detect situations where the transmitting ECU malfunction repeats the same frame all the time. The receiver of the information may use the counter parameter to detect this situation. The transmitting devi...";
CM_ SG_ 2365184254 Hvbcc2Crc "HVBCC2 CRC: The CRC is defined as follows:- Length: 8 bits- Polynomial: x^8+x^5+x^3+x^2+x+1- Initial Value: FFh- Input Data Reflection: Not reflected- Result Data Reflection: Not reflected- XOR value: FFhSAE makes no claim of the functional safety le...";
CM_ BO_ 2566095358 "PTO Drive Engagement 2";
CM_ SG_ 2566095358 EnlSwthTrnsmssnInptShftPt3 "Enable Switch - Transmission input shaft PTO 3: Status of the operator's switch or other input which indicates the desire for engaging the third PTO drive mounted on the transmission case.  There may be more than one PTO drive mounted on the transmis...";
CM_ SG_ 2566095358 EnlSwthTrnsmssnInptShftPt4 "Enable Switch - Transmission input shaft PTO 4: Status of the transmission controller's consent to engage the fourth PTO drive mounted on the transmission case.  The controller in charge of the PTO drive should monitor this parameter and only engage ...";
CM_ SG_ 2566095358 EnggmntCnsntTrnsmssnInptShftPt3 "Engagement Consent - Transmission input shaft PTO 3: Status of the transmission controller's consent to engage the third PTO drive mounted on the transmission case.  The controller in charge of the PTO drive should monitor this parameter and only eng...";
CM_ SG_ 2566095358 EnggmntCnsntTrnsmssnInptShftPt4 "Engagement Consent - Transmission input shaft PTO 4: Status of the transmission controller's consent to engage the fourth PTO drive mounted on the transmission case.  The controller in charge of the PTO drive should monitor this parameter and only en...";
CM_ SG_ 2566095358 EnggmntSttsTrnsmssnInptShftPt3 "Engagement Status - Transmission input shaft PTO 3: Reports if this specific PTO drive is engaged.  This parameter should be broadcast only by the controller(s) receiving feedback about the specific drive.  For example, a pressure switch may be used ...";
CM_ SG_ 2566095358 EnggmntSttsTrnsmssnInptShftPt4 "Engagement Status - Transmission input shaft PTO 4: Reports if this specific PTO drive is engaged.  This parameter should be broadcast only by the controller(s) receiving feedback about the specific drive.  For example, a pressure switch may be used ...";
CM_ BO_ 2364769022 "Fuel Cell System Hydrogen Pressure";
CM_ SG_ 2364769022 FcshpCrc "FCSHP CRC: The CRC is defined as follows: - Length: 8 bits- Polynomial: x^8+x^5+x^3+x^2+x+1- Initial Value: FFh- Input Data Reflection: Not reflected- Result Data Reflection: Not reflected- XOR value: FFh SAE makes no claim of the functional safety l...";
CM_ SG_ 2364769022 FcshpCounter "FCSHP Counter: The message counter is used to detect situations where the transmitting ECU malfunction repeats the same frame all the time. The receiver of the information may use the counter parameter to detect this situation. The transmitting devic...";
CM_ SG_ 2364769022 FlCllSstmHdrgnInltPrssr "Fuel Cell System Hydrogen Inlet Pressure: Hydrogen pressure measured at the inlet to the fuel cell system.";
CM_ BO_ 2566502142 "Well Stimulation Pump System 5";
CM_ SG_ 2566502142 EstmtdWllStmltnPmpLOlFlwRt "Estimated Well Stimulation Pump Lube Oil Flow Rate: Estimated flow rate of the well stimulation pump lube oil in the lubrication circuit. For example, lube oil flow rate may be calculated based on the oil viscosity, temperature, and pressure.";
CM_ SG_ 2566502142 AtlWllStmltnPmpLOlFlwRt "Actual Well Stimulation Pump Lube Oil Flow Rate: Actual flow rate of the well stimulation pump lube oil in the lubrication circuit.";
CM_ SG_ 2566502142 EstmtdWllStmltnPmpGrBxLOlFlwRt "Estimated Well Stimulation Pump Gear Box Lube Oil Flow Rate: Estimated flow rate of the well stimulation pump lube oil in the gear box lubrication circuit. For example, lube oil flow rate may be calculated based on the oil viscosity, temperature, and...";
CM_ SG_ 2566502142 AtlWllStmltnPmpGrBxLOlFlwRt "Actual Well Stimulation Pump Gear Box Lube Oil Flow Rate: Actual flow rate of the well stimulation pump lube oil in the gear box lubrication circuit.";
CM_ BO_ 2566502398 "Well Stimulation Pump System 4";
CM_ SG_ 2566502398 WellStimulationPumpOilPressure "Well Stimulation Pump Oil Pressure: The oil pressure measured in the well stimulation pump.";
CM_ SG_ 2566502398 WllStmltnPmpOtltOlPrssr "Well Stimulation Pump Outlet Oil Pressure: The oil pressure measured at the well stimulation pump oil filter outlet.";
CM_ SG_ 2566502398 WllStmltnPmpOtltOlTmprtr "Well Stimulation Pump Outlet Oil Temperature: The oil temperature measured at the well stimulation pump oil filter outlet.";
CM_ BO_ 2566502654 "Tire Information";
CM_ SG_ 2566502654 TireRollingDistance "Tire Rolling Distance: Tire rolling distance, as specified by the tire manufacturer, used to determine wheel based vehicle speed.";
CM_ BO_ 2566502910 "Hydrogen System Status";
CM_ SG_ 2566502910 HydrogenRedLampData "Hydrogen Red Lamp Data: This parameter provides measured data (feedback) from the Hydrogen (H2) Red Lamp, such as the lamp defined in Section 7.8 of AIS-195 or the visual indicator referenced in Section 5.2.1.6 of GTR 13.  See SPN 23724 Hydrogen Red ...";
CM_ SG_ 2566502910 HydrogenYellowLampData "Hydrogen Yellow Lamp Data: This parameter provides measured data (feedback) from the Hydrogen (H2) Yellow Lamp, such as the lamp defined in Section 7.8 of AIS-195 or the visual indicator referenced in Section 5.2.1.6 of GTR 13.See SPN 23725 Hydrogen ...";
CM_ BO_ 2566503166 "Route Waypoint GPS Coordinates";
CM_ SG_ 2566503166 RouteNumberOfWaypoints "Route Number of Waypoints: Total number of waypoints represented in this instance of the parameter group. This parameter will be set to 0 if a route has not been selected.";
CM_ SG_ 2566503166 RouteWaypointLatitude "Route Waypoint Latitude: Latitude position of this waypoint along the route.Negative values are South and positive values are North.";
CM_ SG_ 2566503166 RouteWaypointLongitude "Route Waypoint Longitude: Longitude position of this waypoint along the route.Negative values are West and positive value are East.";
CM_ BO_ 2566503422 "Route Information";
CM_ SG_ 2566503422 RouteRemainingTime "Route Remaining Time: Remaining time until the vehicle arrives at the final destination of the route.  This will be the last waypoint conveyed in PGN 63930 (Route Waypoint GPS Coordinates).A value of FB00h indicates that the sender supports this para...";
CM_ SG_ 2566503422 RouteRemainingDistance "Route Remaining Distance: Remaining distance until the vehicle arrives at the final destination of the route.  This will be the last waypoint conveyed in PGN 63930 (Route Waypoint GPS Coordinates).A value of FB00h indicates that the sender supports t...";
CM_ SG_ 2566503422 RouteNextWaypoint "Route Next Waypoint: Indicates the next waypoint of the route as reported in PGN 63930 (Route Waypoint GPS Coordinates).  The value of this parameter is less than or equal to SPN 23849 (Route Number of Waypoints).  This parameter will be 0 if no rout...";
CM_ SG_ 2566503422 RouteIdentifier "Route Identifier: Identifer of the current route.  This parameter will increment by 1 when a new route is selected.  If the parameter is 13, it will change to 1 when a new route is selected.  Recipients should request PGN 63930 (Route Waypoint GPS Co...";
CM_ BO_ 2566503678 "Engine Fluid Level/Pressure 15";
CM_ SG_ 2566503678 EngnCrnksBrthrOlSprtrIntkPrssr "Engine Crankcase Breather Oil Separator Intake Pressure: Indicates the gage pressure of the crankcase breather gases measured at the intake of the crankcase breather oil separator.";
CM_ BO_ 2566503934 "Fuel Cell System Coolant Information 3";
CM_ SG_ 2566503934 FlCllSstmClntFlwRtExtnddRng "Fuel Cell System Coolant Flow Rate (Extended Range): Flow rate of the fuel cell system coolant.  This is typically measured at the inlet of the fuel cell system radiator.  See SPN 23207 (Fuel Cell System Coolant Flow Rate) for alternate range and res...";
CM_ SG_ 2566503934 FlCllStkClntFlwRtExtnddRng "Fuel Cell Stack Coolant Flow Rate (Extended Range): Flow rate of the coolant through the fuel cell stack.  See SPN 23208 (Fuel Cell Stack Coolant Flow Rate) for alternate range and resolution.";
CM_ BO_ 2566504190 "Transmission Configuration 3";
CM_ SG_ 2566504190 TransmissionMode1Configuration "Transmission Mode 1 Configuration: This configuration signal is the transmission's indication regarding configuration status of Transmission Mode x. For example, this can be used by external devices to understand which transmission modes are currentl...";
CM_ SG_ 2566504190 TransmissionMode2Configuration "Transmission Mode 2 Configuration: This configuration signal is the transmission's indication regarding configuration status of Transmission Mode x. For example, this can be used by external devices to understand which transmission modes are currentl...";
CM_ SG_ 2566504190 TransmissionMode3Configuration "Transmission Mode 3 Configuration: This configuration signal is the transmission's indication regarding configuration status of Transmission Mode x. For example, this can be used by external devices to understand which transmission modes are currentl...";
CM_ SG_ 2566504190 TransmissionMode4Configuration "Transmission Mode 4 Configuration: This configuration signal is the transmission's indication regarding configuration status of Transmission Mode x. For example, this can be used by external devices to understand which transmission modes are currentl...";
CM_ SG_ 2566504190 TransmissionMode5Configuration "Transmission Mode 5 Configuration: This configuration signal is the transmission's indication regarding configuration status of Transmission Mode x. For example, this can be used by external devices to understand which transmission modes are currentl...";
CM_ SG_ 2566504190 TransmissionMode6Configuration "Transmission Mode 6 Configuration: This configuration signal is the transmission's indication regarding configuration status of Transmission Mode x. For example, this can be used by external devices to understand which transmission modes are currentl...";
CM_ SG_ 2566504190 TransmissionMode7Configuration "Transmission Mode 7 Configuration: This configuration signal is the transmission's indication regarding configuration status of Transmission Mode x. For example, this can be used by external devices to understand which transmission modes are currentl...";
CM_ SG_ 2566504190 TransmissionMode8Configuration "Transmission Mode 8 Configuration: This configuration signal is the transmission's indication regarding configuration status of Transmission Mode x. For example, this can be used by external devices to understand which transmission modes are currentl...";
CM_ SG_ 2566504190 TransmissionMode9Configuration "Transmission Mode 9 Configuration: This configuration signal is the transmission's indication regarding configuration status of Transmission Mode x. For example, this can be used by external devices to understand which transmission modes are currentl...";
CM_ SG_ 2566504190 TransmissionMode10Configuration "Transmission Mode 10 Configuration: This configuration signal is the transmission's indication regarding configuration status of Transmission Mode x. For example, this can be used by external devices to understand which transmission modes are current...";
CM_ SG_ 2566504190 TransmissionMode11Configuration "Transmission Mode 11 Configuration: This configuration signal is the transmission's indication regarding configuration status of Transmission Mode x. For example, this can be used by external devices to understand which transmission modes are current...";
CM_ SG_ 2566504190 TransmissionMode12Configuration "Transmission Mode 12 Configuration: This configuration signal is the transmission's indication regarding configuration status of Transmission Mode x. For example, this can be used by external devices to understand which transmission modes are current...";
CM_ SG_ 2566504190 TransmissionMode13Configuration "Transmission Mode 13 Configuration: This configuration signal is the transmission's indication regarding configuration status of Transmission Mode x. For example, this can be used by external devices to understand which transmission modes are current...";
CM_ SG_ 2566504190 TransmissionMode14Configuration "Transmission Mode 14 Configuration: This configuration signal is the transmission's indication regarding configuration status of Transmission Mode x. For example, this can be used by external devices to understand which transmission modes are current...";
CM_ SG_ 2566504190 TransmissionMode15Configuration "Transmission Mode 15 Configuration: This configuration signal is the transmission's indication regarding configuration status of Transmission Mode x. For example, this can be used by external devices to understand which transmission modes are current...";
CM_ SG_ 2566504190 TransmissionMode16Configuration "Transmission Mode 16 Configuration: This configuration signal is the transmission's indication regarding configuration status of Transmission Mode x. For example, this can be used by external devices to understand which transmission modes are current...";
CM_ SG_ 2566504190 TransmissionMode17Configuration "Transmission Mode 17 Configuration: This configuration signal is the transmission's indication regarding configuration status of Transmission Mode x. For example, this can be used by external devices to understand which transmission modes are current...";
CM_ SG_ 2566504190 TransmissionMode18Configuration "Transmission Mode 18 Configuration: This configuration signal is the transmission's indication regarding configuration status of Transmission Mode x. For example, this can be used by external devices to understand which transmission modes are current...";
CM_ SG_ 2566504190 TransmissionMode19Configuration "Transmission Mode 19 Configuration: This configuration signal is the transmission's indication regarding configuration status of Transmission Mode x. For example, this can be used by external devices to understand which transmission modes are current...";
CM_ SG_ 2566504190 TransmissionMode20Configuration "Transmission Mode 20 Configuration: This configuration signal is the transmission's indication regarding configuration status of Transmission Mode x. For example, this can be used by external devices to understand which transmission modes are current...";
CM_ BO_ 2566505214 "Hydrogen System Information";
CM_ SG_ 2566505214 HydrogenRedLampCommand "Hydrogen Red Lamp Command: Command for the Hydrogen (H2) Red Lamp, such as the lamp defined in Section 7.8 of AIS-195 or the visual indicator referenced in Section 5.2.1.6 of GTR 13.Multiple controller applications can provide this parameter.  The la...";
CM_ SG_ 2566505214 HydrogenYellowLampCommand "Hydrogen Yellow Lamp Command: Command for the Hydrogen (H2) Yellow Lamp, such as the lamp defined in Section 7.8 of AIS-195 or the visual indicator referenced in Section 5.2.1.6 of GTR 13.  Multiple controller applications can provide this parameter....";
CM_ BO_ 2566095870 "Engine Gas Flow Rate 2";
CM_ SG_ 2566095870 EngnTrhrgr1CmprssrIntkFlwRt "Engine Turbocharger 1 Compressor Intake Flow Rate: Mass flow rate of fresh air entering the first or only engine turbocharger compressor, before any EGR mixer, if used.";
CM_ SG_ 2566095870 EngnTrhrgr2CmprssrIntkFlwRt "Engine Turbocharger 2 Compressor Intake Flow Rate: Mass flow rate of fresh air entering the second engine turbocharger compressor, before any EGR mixer, if used.";
CM_ SG_ 2566095870 EngnIntkArMssFlwRtExtnddRng "Engine Intake Air Mass Flow Rate (Extended Range): Mass flow rate of fresh air entering the engine air intake, before any EGR mixer, if used.  Flow rate of fresh air conducted to the engine cylinders to support combustion.  See SPN 132 for alternate ...";
CM_ BO_ 2566096126 "Engine Supercharger Information";
CM_ SG_ 2566096126 EngnSprhrgr1BpssAttrPstn "Engine Supercharger 1 Bypass Actuator Position: The position of the first or only engine supercharger bypass actuator, where 0% represents bypass fully closed and 100% represents bypass fully open.";
CM_ SG_ 2566096126 EngnSprhrgr2BpssAttrPstn "Engine Supercharger 2 Bypass Actuator Position: The position of the second engine supercharger bypass actuator, where 0% represents bypass fully closed and 100% represents bypass fully open.";
CM_ SG_ 2566096126 EngnSprhrgr1ClthVlvCmmnd "Engine Supercharger 1 Clutch Valve Command: Command to the valve that controls the clutch for the first or only engine supercharger, normalized to percent, where 0% represents not actuated and 100% represents fully actuated.";
CM_ SG_ 2566096126 EngnSprhrgr2ClthVlvCmmnd "Engine Supercharger 2 Clutch Valve Command: Command to the valve that controls the clutch for the second engine supercharger, normalized to percent, where 0% represents not actuated and 100% represents fully actuated.";
CM_ SG_ 2566096126 EngineSupercharger1Speed "Engine Supercharger 1 Speed: Rotational velocity of the rotor in the first or only supercharger.";
CM_ SG_ 2566096126 EngineSupercharger2Speed "Engine Supercharger 2 Speed: Rotational velocity of the rotor in the second supercharger.";
CM_ BO_ 2365156094 "ER DC/DC Converter 4 References";
CM_ SG_ 2365156094 ErDcDc4ReferenceCrc "ER DC/DC 4 Reference CRC: The CRC is defined as follows: - Length: 8 bits- Polynomial: x^8+x^5+x^3+x^2+x+1- Initial Value: FFh- Input Data Reflection: Not reflected- Result Data Reflection: Not reflected- XOR value: FFh SAE makes no claim of the func...";
CM_ SG_ 2365156094 ErDcDc4ReferenceCounter "ER DC/DC 4 Reference Counter: The message counter is used to detect situations where the transmitting ECU malfunction repeats the same frame all the time. The receiver of the information may use the counter parameter to detect this situation. The tra...";
CM_ SG_ 2365156094 ErDcDc4ReferenceCurrent "ER DC/DC 4 Reference Current: This value is used for converting inverter current in percent to units of Amps (RMS or DC).(Value in Amps) = (Percent Value)/(100%) * (Reference Current)For example, if this parameter has a value of 200 A and the percent...";
CM_ SG_ 2365156094 ErDcDc4ReferenceVoltage "ER DC/DC 4 Reference Voltage: This value is used for converting inverter voltage in percent to units of Volts (RMS or DC).(Value in Volts) = (Percent Value)/(100%) * (Reference Voltage)For example, if this parameter has a value of 400 V and the perce...";
CM_ SG_ 2365156094 ErDcDc4ReferencePower "ER DC/DC 4 Reference Power: This value is used for converting power in percent to units of kW.  (Value in kW) = (Percent Value)/(100%) * (Reference Power)For example, if this parameter has a value of 400 kW and the percent value is equal to 75%, then...";
CM_ BO_ 2365156350 "ER DC/DC Converter 4 Power Limits Request";
CM_ SG_ 2365156350 ErDD4PrmrSdPwrMnmmLmtRqst "ER DC/DC 4 Primary Side Power Minimum Limit Request: The minimum allowed primary side power requested by a separate device.   Under normal conditions this requested limit would be reflected in SPN 24253 (ER DC/DC 4 Primary Side Power Minimum Limit Se...";
CM_ SG_ 2365156350 ErDD4PrmrSdPwrMxmmLmtRqst "ER DC/DC 4 Primary Side Power Maximum Limit Request: The maximum allowed primary side power requested by a separate device.   Under normal conditions this requested limit would be reflected in SPN 24254 (ER DC/DC 4 Primary Side Power Maximum Limit Se...";
CM_ SG_ 2365156350 ErDD4SndrSdPwrMnmmLmtRqst "ER DC/DC 4 Secondary Side Power Minimum Limit Request: The minimum allowed secondary side power requested by a separate device.   Under normal conditions this requested limit would be reflected in SPN 24255 (ER DC/DC 4 Secondary Side Power Minimum Li...";
CM_ SG_ 2365156350 ErDD4SndrSdPwrMxmmLmtRqst "ER DC/DC 4 Secondary Side Power Maximum Limit Request: The maximum allowed secondary side power requested by a separate device.   Under normal conditions this requested limit would be reflected in SPN 24256 (ER DC/DC 4 Secondary Side Power Maximum Li...";
CM_ BO_ 2365156606 "ER DC/DC Converter 4 Current Limits Request";
CM_ SG_ 2365156606 ErDD4PrmrSdCrrntMnmmLmtRqst "ER DC/DC 4 Primary Side Current Minimum Limit Request: The minimum (negative) allowed Primary Side current requested by a separate device.  Under normal conditions this requested limit would be reflected in SPN 24249 (ER DC/DC 4 Primary Side Current ...";
CM_ SG_ 2365156606 ErDD4PrmrSdCrrntMxmmLmtRqst "ER DC/DC 4 Primary Side Current Maximum Limit Request: The maximum allowed Primary Side current requested by a separate device.  Under normal conditions this requested limit would be reflected in SPN 24250 (ER DC/DC 4 Primary Side Current Maximum Lim...";
CM_ SG_ 2365156606 ErDD4SndrSdCrrntMnmmLmtRqst "ER DC/DC 4 Secondary Side Current Minimum Limit Request: The minimum (negative) allowed Secondary Side current requested by a separate device.   Under normal conditions this requested limit would be reflected in SPN 24251 (ER DC/DC 4 Secondary Side C...";
CM_ SG_ 2365156606 ErDD4SndrSdCrrntMxmmLmtRqst "ER DC/DC 4 Secondary Side Current Maximum Limit Request: The maximum allowed Secondary Side current requested by a separate device.   Under normal conditions this requested limit would be reflected in SPN 24252 (ER DC/DC 4 Secondary Side Current Maxi...";
CM_ BO_ 2365156862 "ER DC/DC Converter 4 Voltage Limits Request";
CM_ SG_ 2365156862 ErDD4PrmrSdVltgMnmmLmtRqst "ER DC/DC 4 Primary Side Voltage Minimum Limit Request: The minimum allowed Primary Side voltage requested by a separate device.   Under normal conditions this requested limit would be reflected in SPN 24245 (ER DC/DC 4 Primary Side Voltage Minimum Li...";
CM_ SG_ 2365156862 ErDD4PrmrSdVltgMxmmLmtRqst "ER DC/DC 4 Primary Side Voltage Maximum Limit Request: The maximum allowed Primary Side voltage requested by a separate device.   Under normal conditions this requested limit would be reflected in SPN 24246 (ER DC/DC 4 Primary Side Voltage Maximum Li...";
CM_ SG_ 2365156862 ErDD4SndrSdVltgMnmmLmtRqst "ER DC/DC 4 Secondary Side Voltage Minimum Limit Request: The minimum allowed Secondary Side voltage requested by a separate device.   Under normal conditions this requested limit would be reflected in SPN 24247 (ER DC/DC 4 Secondary Side Voltage Mini...";
CM_ SG_ 2365156862 ErDD4SndrSdVltgMxmmLmtRqst "ER DC/DC 4 Secondary Side Voltage Maximum Limit Request: The maximum allowed Secondary Side voltage requested by a separate device.   Under normal conditions this requested limit would be reflected in SPN 24248 (ER DC/DC 4 Secondary Side Voltage Maxi...";
CM_ BO_ 2365157118 "ER DC/DC Converter 4 Temperatures";
CM_ SG_ 2365157118 ErDcDc4ConverterTemperature "ER DC/DC 4 Converter Temperature: Parameter indicating the temperature of the Extended Range DC/DC Converter (e.g, controller, circuit board, enclosure).";
CM_ SG_ 2365157118 ErDD4CnvrtrEltrnFltrTmprtr "ER DC/DC 4 Converter Electronic Filter Temperature: Parameter indicating the temperature of the electronic components that make up the Extended Range DC/DC Converter filter.";
CM_ SG_ 2365157118 ErDD4PwrEltrnsTmprtr "ER DC/DC 4 Power Electronics Temperature: Parameter indicating the temperature of the Extended Range DC/DC Converter power electronics components (e.g, switch or heatsink).";
CM_ SG_ 2365157118 ErDcDc4CoolantInTemperature "ER DC/DC 4 Coolant  In Temperature: Parameter indicating the temperature of the Extended Range DC/DC Converter Coolant measured at the input of the converter";
CM_ SG_ 2365157118 ErDcDc4CoolantOutTemperature "ER DC/DC 4 Coolant Out Temperature: Parameter indicating the temperature of the Extended Range DC/DC Converter Coolant measured at the output of the converter";
CM_ BO_ 2566483966 "ER DC/DC Converter 4 Power Limit Settings";
CM_ SG_ 2566483966 ErDD4PrmrSdPwrMnmmLmtSttng "ER DC/DC 4 Primary Side Power Minimum Limit Setting: Reports the active minimum primary side power limit of the Extended Range DC/DC Converter.  The setting may be requested by a separate device (via SPN 24270 (ER DC/DC 4 Primary Side Power Minimum L...";
CM_ SG_ 2566483966 ErDD4PrmrSdPwrMxmmLmtSttng "ER DC/DC 4 Primary Side Power Maximum Limit Setting: Reports the active maximum primary side power limit of the Extended Range DC/DC Converter.  The setting may be requested by a separate device (via SPN 24271 (ER DC/DC 4 Primary Side Power Maximum L...";
CM_ SG_ 2566483966 ErDD4SndrSdPwrMnmmLmtSttng "ER DC/DC 4 Secondary Side Power Minimum Limit Setting: Reports the active minimum secondary side power limit of the Extended Range DC/DC Converter.  The setting may be requested by a separate device (via SPN 24272 (ER DC/DC 4 Secondary Side Power Min...";
CM_ SG_ 2566483966 ErDD4SndrSdPwrMxmmLmtSttng "ER DC/DC 4 Secondary Side Power Maximum Limit Setting: Reports the active maximum secondary side power limit of the Extended Range DC/DC Converter.  The setting may be requested by a separate device (via SPN 24273 (ER DC/DC 4 Secondary Side Power Max...";
CM_ BO_ 2566484222 "ER DC/DC Converter 4 Current Limits Settings";
CM_ SG_ 2566484222 ErDD4PrmrSdCrrntMnmmLmtSttng "ER DC/DC 4 Primary Side Current Minimum Limit Setting: Reports the active minimum limit (negative) on the Primary Side current of the Extended Range DC/DC Converter.  The setting may be requested by a separate device (via SPN 24266 (ER DC/DC 4 Primar...";
CM_ SG_ 2566484222 ErDD4PrmrSdCrrntMxmmLmtSttng "ER DC/DC 4 Primary Side Current Maximum Limit Setting: Reports the active maximum limit on the Primary Side current of the Extended Range DC/DC Converter.  The setting may be requested by a separate device (via SPN 24267 (ER DC/DC 4 Primary Side Curr...";
CM_ SG_ 2566484222 ErDD4SndrSdCrrntMnmmLmtSttng "ER DC/DC 4 Secondary Side Current Minimum Limit Setting: Reports the active minimum limit (negative) on the Secondary Side current of the Extended Range DC/DC Converter.  The setting may be requested by a separate device (via SPN 24268 (ER DC/DC 4 Se...";
CM_ SG_ 2566484222 ErDD4SndrSdCrrntMxmmLmtSttng "ER DC/DC 4 Secondary Side Current Maximum Limit Setting: Reports the active maximum limit on the Secondary Side current of the Extended Range DC/DC Converter.  The setting may be requested by a separate device (via SPN 24269 (ER DC/DC 4 Secondary Sid...";
CM_ BO_ 2566484478 "ER DC/DC Converter 4 Voltage Limit Settings";
CM_ SG_ 2566484478 ErDD4PrmrSdVltgMnmmLmtSttng "ER DC/DC 4 Primary Side Voltage Minimum Limit Setting: Reports the active minimum limit on the Primary Side voltage of the Extended Range DC/DC Converter.  The setting may be requested by a separate device (via SPN 24262 (ER DC/DC 4 Primary Side Volt...";
CM_ SG_ 2566484478 ErDD4PrmrSdVltgMxmmLmtSttng "ER DC/DC 4 Primary Side Voltage Maximum Limit Setting: Reports the active maximum limit on the Primary Side voltage of the Extended Range DC/DC Converter.  The setting may be requested by a separate device (via SPN 24263 (ER DC/DC 4 Primary Side Volt...";
CM_ SG_ 2566484478 ErDD4SndrSdVltgMnmmLmtSttng "ER DC/DC 4 Secondary Side Voltage Minimum Limit Setting: Reports the active minimum limit on the Secondary Side voltage of the Extended Range DC/DC Converter.  The setting may be requested by a separate device (via SPN 24264 (ER DC/DC 4 Secondary Sid...";
CM_ SG_ 2566484478 ErDD4SndrSdVltgMxmmLmtSttng "ER DC/DC 4 Secondary Side Voltage Maximum Limit Setting: Reports the active maximum limit on the Secondary Side voltage of the Extended Range DC/DC Converter.  The setting may be requested by a separate device (via SPN 24265 (ER DC/DC 4 Secondary Sid...";
CM_ BO_ 2365158142 "ER DC/DC Converter 4 Low Voltage";
CM_ SG_ 2365158142 ErDD4CntrllrInptIgntnVltg "ER DC/DC 4 Controller Input Ignition Voltage: Ignition voltage (i.e. switched) supplied to the  Extended Range DC/DC Converter controller.";
CM_ SG_ 2365158142 ErDD4CntrllrInptUnswthdSlVltg "ER DC/DC 4 Controller Input Unswitched SLI Voltage: Continuously supplied SLI power to this instance of the Extended Range DC/DC Converter controller.";
CM_ BO_ 2365158398 "ER DC/DC Converter 4 Power and Chassis Voltage";
CM_ SG_ 2365158398 ErDcDc4PrimarySidePower "ER DC/DC 4 Primary Side Power: Indicates the Primary Side power measured at the Extended Range DC/DC Converter.  The Primary Side power is positive if the converter is flowing current from the Secondary Side to the Primary side.  The Primary Side pow...";
CM_ SG_ 2365158398 ErDcDc4SecondarySidePower "ER DC/DC 4 Secondary Side Power: Indicates the Secondary Side power measured at the Extended Range DC/DC Converter.  The Secondary Side power is positive if the converter is flowing current from the Primary Side to the Secondary side.  The Secondary ...";
CM_ SG_ 2365158398 ErDD4PrmrSdNgtvTChsssGrndVltg "ER DC/DC 4 Primary Side Negative to Chassis Ground Voltage: The voltage level as measured by the ER DC/DC between the Primary Side negative ER DC bus and the chassis of the ER DC/DC enclosure.  This voltage can be used for system level monitoring of ...";
CM_ SG_ 2365158398 ErDD4SndrSdNgtvTChsssGrndVltg "ER DC/DC 4 Secondary Side Negative to Chassis Ground Voltage: The voltage level as measured by the ER DC/DC between the Secondary Side negative ER DC bus and the chassis of the ER DC/DC enclosure.  This voltage can be used for system level monitoring...";
CM_ BO_ 2365158654 "ER DC/DC Converter 4 Voltage and Current";
CM_ SG_ 2365158654 ErDcDc4PrimarySideVoltage "ER DC/DC 4 Primary Side Voltage: Indicates the measured Primary Side voltage measured at the point of control inside the Extended Range DC/DC Converter.Refer to SPN 24277 (ER DC/DC 4 Reference Voltage) to convert % to Volts.";
CM_ SG_ 2365158654 ErDcDc4SecondarySideVoltage "ER DC/DC 4 Secondary Side Voltage: Indicates the measured Secondary Side voltage measured at the point of control inside the Extended Range DC/DC Converter.Refer to SPN 24277 (ER DC/DC 4 Reference Voltage) to convert % to Volts.";
CM_ SG_ 2365158654 ErDcDc4PrimarySideCurrent "ER DC/DC 4 Primary Side Current: Indicates the measured Primary Side current measured at the point of control inside the Extended Range DC/DC Converter.  The current is positive if the converter is flowing current from the Secondary to the Primary Si...";
CM_ SG_ 2365158654 ErDcDc4SecondarySideCurrent "ER DC/DC 4 Secondary Side Current: Indicates the measured Secondary Side current measured at the point of control inside the Extended Range DC/DC Converter.  The current is positive if the converter is flowing current from the Primary to the Secondar...";
CM_ BO_ 2365158910 "ER DC/DC Converter 4 Operating Status";
CM_ SG_ 2365158910 ErDcDc4StatusCrc "ER DC/DC 4 Status CRC: The CRC is defined as follows: - Length: 8 bits- Polynomial: x^8+x^5+x^3+x^2+x+1- Initial Value: FFh- Input Data Reflection: Not reflected- Result Data Reflection: Not reflected- XOR value: FFh SAE makes no claim of the functio...";
CM_ SG_ 2365158910 ErDcDc4StatusCounter "ER DC/DC 4 Status Counter: The message counter is used to detect situations where the transmitting ECU malfunction repeats the same frame all the time. The receiver of the information may use the counter parameter to detect this situation. The transm...";
CM_ SG_ 2365158910 ErDcDc4OperationalStatus "ER DC/DC 4 Operational Status: Operating state of the Extended Range DC/DC Converter0000b = Disabled - In this mode all high voltage switching is disabled0001b = Initialization - The device is powering up.  This process may include both internal chec...";
CM_ SG_ 2365158910 ErDcDc4HvilStatus "ER DC/DC 4 HVIL Status: High Voltage Interlock Loop (HVIL) state of the Extended Range DC/DC Converter.00b = HVIL Closed01b = HVIL Open10b = Error11b = Not Available";
CM_ SG_ 2365158910 ErDcDc4LoadshedRequest "ER DC/DC 4 Loadshed Request: The loadshed request is a request to the controlling device to reduce the Extended Range DC/DC Converter loads.  The Loadshed Requested state is an indication that this Extended Range DC/DC Converter has a malfunction or ...";
CM_ SG_ 2365158910 ErDD4PwrLmtDTPrmrSdCrrntMnmm "ER DC/DC 4 Power Limit due to Primary Side Current Minimum: Indicates whether or not output power is being limited due to Primary Side current (see SPN 24237 (ER DC/DC 4 Primary Side Current)) approaching or exceeding the minimum limit (see SPN 24249...";
CM_ SG_ 2365158910 ErDD4PwrLmtDTPrmrSdCrrntMxmm "ER DC/DC 4 Power Limit due to Primary Side Current Maximum: Indicates whether or not output power is being limited due to Primary Side current (see SPN 24237 (ER DC/DC 4 Primary Side Current)) approaching or exceeding the maximum limit (see SPN 24250...";
CM_ SG_ 2365158910 ErDD4PwrLmtDTSndrSdCrrntMnmm "ER DC/DC 4 Power Limit due to Secondary Side Current Minimum: Indicates whether or not output power is being limited due to Secondary Side current (see SPN 24238 (ER DC/DC 4 Secondary Side Current)) approaching or exceeding the minimum limit (see SPN...";
CM_ SG_ 2365158910 ErDD4PwrLmtDTSndrSdCrrntMxmm "ER DC/DC 4 Power Limit due to Secondary Side Current Maximum: Indicates whether or not output power is being limited due to Secondary Side current (see SPN 24238 (ER DC/DC 4 Secondary Side Current)) approaching or exceeding the maximum limit (see SPN...";
CM_ SG_ 2365158910 ErDD4PwrLmtDTPrmrSdVltgMnmm "ER DC/DC 4 Power Limit due to Primary Side Voltage Minimum: Indicates whether or not output power is being limited due to Primary Side voltage (see SPN 24235 (ER DC/DC 4 Primary Side Voltage)) approaching or exceeding the minimum limit (see SPN 24245...";
CM_ SG_ 2365158910 ErDD4PwrLmtDTPrmrSdVltgMxmm "ER DC/DC 4 Power Limit due to Primary Side Voltage Maximum: Indicates whether or not output power is being limited due to Primary Side voltage (see SPN 24235 (ER DC/DC 4 Primary Side Voltage)) approaching or exceeding the maximum limit (see SPN 24246...";
CM_ SG_ 2365158910 ErDD4PwrLmtDTSndrSdVltgMnmm "ER DC/DC 4 Power Limit due to Secondary Side Voltage Minimum: Indicates whether or not output power is being limited due to Secondary Side voltage (see SPN 24236 (ER DC/DC 4 Secondary Side Voltage)) approaching or exceeding the minimum limit (see SPN...";
CM_ SG_ 2365158910 ErDD4PwrLmtDTSndrSdVltgMxmm "ER DC/DC 4 Power Limit due to Secondary Side Voltage Maximum: Indicates whether or not output power is being limited due to Secondary Side voltage (see SPN 24236 (ER DC/DC 4 Secondary Side Voltage)) approaching or exceeding the maximum limit (see SPN...";
CM_ SG_ 2365158910 ErDD4PwrLmtDTCnvrtrTmprtr "ER DC/DC 4 Power Limit due to Converter Temperature: Indicates whether or not output power is being limited due to Converter Temperature (see SPN 24257 (ER DC/DC 4 Converter Temperature)) approaching or exceeding the maximum limit.00b = No power limi...";
CM_ SG_ 2365158910 ErDD4PwrLmtDTEltrnFltrTmprtr "ER DC/DC 4 Power Limit due to Electronic Filter Temperature: Indicates whether or not output power is being limited due to Output Electronic Filter Temperature (see SPN 24258 (ER DC/DC 4 Converter Electronic Filter Temperature)) approaching or exceed...";
CM_ SG_ 2365158910 ErDD4PwrLmtDTPwrEltrnsTmprtr "ER DC/DC 4 Power Limit due to Power Electronics Temperature: Indicates whether or not output power is being limited due to Power Electronics Temperature (see SPN 24259 (ER DC/DC 4 Power Electronics Temperature)) approaching or exceeding the maximum l...";
CM_ SG_ 2365158910 ErDD4PwrLmtDTUndfndRsn "ER DC/DC 4 Power Limit due to Undefined Reason: Indicates whether or not output power is being limited due to an undefined reason.00b = No power limit for this reason01b = Power limited for this reason10b = Error11b = Not Available";
CM_ BO_ 2365159166 "ER DC/DC Converter 4 Control";
CM_ SG_ 2365159166 ErDcDc4CommandCrc "ER DC/DC 4 Command CRC: The CRC is defined as follows: - Length: 8 bits- Polynomial: x^8+x^5+x^3+x^2+x+1- Initial Value: FFh- Input Data Reflection: Not reflected- Result Data Reflection: Not reflected- XOR value: FFh SAE makes no claim of the functi...";
CM_ SG_ 2365159166 ErDcDc4CommandCounter "ER DC/DC 4 Command  Counter: The message counter is used to detect situations where the transmitting ECU malfunction repeats the same frame all the time. The receiver of the information may use the counter parameter to detect this situation. The tran...";
CM_ SG_ 2365159166 ErDcDc4OperationalCommand "ER DC/DC 4 Operational Command: Command to enable or disable operation.0000b = Disable - in this mode all high voltage switching is disabled0001b = Standby - system is ready and waiting for command to enter control modes0010b = Power Down - stop all ...";
CM_ SG_ 2365159166 ErDcDc4OperationalSetpoint "ER DC/DC 4 Operational Setpoint: The set point for regulating the DC/DC Converter per SPN 24216 (ER DC/DC 4 Operational Command).  When in Voltage control modes (states 0100b and 0101b of SPN 24216 (ER DC/DC 4 Operational Command)), the operational r...";
CM_ BO_ 2365159422 "ER DC/DC Converter 3 References";
CM_ SG_ 2365159422 ErDcDc3ReferenceCrc "ER DC/DC 3 Reference CRC: The CRC is defined as follows: - Length: 8 bits- Polynomial: x^8+x^5+x^3+x^2+x+1- Initial Value: FFh- Input Data Reflection: Not reflected- Result Data Reflection: Not reflected- XOR value: FFh SAE makes no claim of the func...";
CM_ SG_ 2365159422 ErDcDc3ReferenceCounter "ER DC/DC 3 Reference Counter: The message counter is used to detect situations where the transmitting ECU malfunction repeats the same frame all the time. The receiver of the information may use the counter parameter to detect this situation. The tra...";
CM_ SG_ 2365159422 ErDcDc3ReferenceCurrent "ER DC/DC 3 Reference Current: This value is used for converting inverter current in percent to units of Amps (RMS or DC).(Value in Amps) = (Percent Value)/(100%) * (Reference Current)For example, if this parameter has a value of 200 A and the percent...";
CM_ SG_ 2365159422 ErDcDc3ReferenceVoltage "ER DC/DC 3 Reference Voltage: This value is used for converting inverter voltage in percent to units of Volts (RMS or DC).(Value in Volts) = (Percent Value)/(100%) * (Reference Voltage)For example, if this parameter has a value of 400 V and the perce...";
CM_ SG_ 2365159422 ErDcDc3ReferencePower "ER DC/DC 3 Reference Power: This value is used for converting power in percent to units of kW.  (Value in kW) = (Percent Value)/(100%) * (Reference Power)For example, if this parameter has a value of 400 kW and the percent value is equal to 75%, then...";
CM_ BO_ 2365159678 "ER DC/DC Converter 3 Power Limits Request";
CM_ SG_ 2365159678 ErDD3PrmrSdPwrMnmmLmtRqst "ER DC/DC 3 Primary Side Power Minimum Limit Request: The minimum allowed primary side power requested by a separate device.   Under normal conditions this requested limit would be reflected in SPN 24188 (ER DC/DC 3 Primary Side Power Minimum Limit Se...";
CM_ SG_ 2365159678 ErDD3PrmrSdPwrMxmmLmtRqst "ER DC/DC 3 Primary Side Power Maximum Limit Request: The maximum allowed primary side power requested by a separate device.   Under normal conditions this requested limit would be reflected in SPN 24189 (ER DC/DC 3 Primary Side Power Maximum Limit Se...";
CM_ SG_ 2365159678 ErDD3SndrSdPwrMnmmLmtRqst "ER DC/DC 3 Secondary Side Power Minimum Limit Request: The minimum allowed secondary side power requested by a separate device.   Under normal conditions this requested limit would be reflected in SPN 24190 (ER DC/DC 3 Secondary Side Power Minimum Li...";
CM_ SG_ 2365159678 ErDD3SndrSdPwrMxmmLmtRqst "ER DC/DC 3 Secondary Side Power Maximum Limit Request: The maximum allowed secondary side power requested by a separate device.   Under normal conditions this requested limit would be reflected in SPN 24191 (ER DC/DC 3 Secondary Side Power Maximum Li...";
CM_ BO_ 2365159934 "ER DC/DC Converter 3 Current Limits Request";
CM_ SG_ 2365159934 ErDD3PrmrSdCrrntMnmmLmtRqst "ER DC/DC 3 Primary Side Current Minimum Limit Request: The minimum (negative) allowed Primary Side current requested by a separate device.  Under normal conditions this requested limit would be reflected in SPN 24184 (ER DC/DC 3 Primary Side Current ...";
CM_ SG_ 2365159934 ErDD3PrmrSdCrrntMxmmLmtRqst "ER DC/DC 3 Primary Side Current Maximum Limit Request: The maximum allowed Primary Side current requested by a separate device.  Under normal conditions this requested limit would be reflected in SPN 24185 (ER DC/DC 3 Primary Side Current Maximum Lim...";
CM_ SG_ 2365159934 ErDD3SndrSdCrrntMnmmLmtRqst "ER DC/DC 3 Secondary Side Current Minimum Limit Request: The minimum (negative) allowed Secondary Side current requested by a separate device.   Under normal conditions this requested limit would be reflected in SPN 24186 (ER DC/DC 3 Secondary Side C...";
CM_ SG_ 2365159934 ErDD3SndrSdCrrntMxmmLmtRqst "ER DC/DC 3 Secondary Side Current Maximum Limit Request: The maximum allowed Secondary Side current requested by a separate device.   Under normal conditions this requested limit would be reflected in SPN 24187 (ER DC/DC 3 Secondary Side Current Maxi...";
CM_ BO_ 2365160190 "ER DC/DC Converter 3 Voltage Limits Request";
CM_ SG_ 2365160190 ErDD3PrmrSdVltgMnmmLmtRqst "ER DC/DC 3 Primary Side Voltage Minimum Limit Request: The minimum allowed Primary Side voltage requested by a separate device.   Under normal conditions this requested limit would be reflected in SPN 24180 (ER DC/DC 3 Primary Side Voltage Minimum Li...";
CM_ SG_ 2365160190 ErDD3PrmrSdVltgMxmmLmtRqst "ER DC/DC 3 Primary Side Voltage Maximum Limit Request: The maximum allowed Primary Side voltage requested by a separate device.   Under normal conditions this requested limit would be reflected in SPN 24181 (ER DC/DC 3 Primary Side Voltage Maximum Li...";
CM_ SG_ 2365160190 ErDD3SndrSdVltgMnmmLmtRqst "ER DC/DC 3 Secondary Side Voltage Minimum Limit Request: The minimum allowed Secondary Side voltage requested by a separate device.   Under normal conditions this requested limit would be reflected in SPN 24182 (ER DC/DC 3 Secondary Side Voltage Mini...";
CM_ SG_ 2365160190 ErDD3SndrSdVltgMxmmLmtRqst "ER DC/DC 3 Secondary Side Voltage Maximum Limit Request: The maximum allowed Secondary Side voltage requested by a separate device.   Under normal conditions this requested limit would be reflected in SPN 24183 (ER DC/DC 3 Secondary Side Voltage Maxi...";
CM_ BO_ 2365160446 "ER DC/DC Converter 3 Temperatures";
CM_ SG_ 2365160446 ErDcDc3ConverterTemperature "ER DC/DC 3 Converter Temperature: Parameter indicating the temperature of the Extended Range DC/DC Converter (e.g, controller, circuit board, enclosure).";
CM_ SG_ 2365160446 ErDD3CnvrtrEltrnFltrTmprtr "ER DC/DC 3 Converter Electronic Filter Temperature: Parameter indicating the temperature of the electronic components that make up the Extended Range DC/DC Converter filter.";
CM_ SG_ 2365160446 ErDD3PwrEltrnsTmprtr "ER DC/DC 3 Power Electronics Temperature: Parameter indicating the temperature of the Extended Range DC/DC Converter power electronics components (e.g, switch or heatsink).";
CM_ SG_ 2365160446 ErDcDc3CoolantInTemperature "ER DC/DC 3 Coolant  In Temperature: Parameter indicating the temperature of the Extended Range DC/DC Converter Coolant measured at the input of the converter";
CM_ SG_ 2365160446 ErDcDc3CoolantOutTemperature "ER DC/DC 3 Coolant Out Temperature: Parameter indicating the temperature of the Extended Range DC/DC Converter Coolant measured at the output of the converter";
CM_ BO_ 2566487294 "ER DC/DC Converter 3 Power Limit Settings";
CM_ SG_ 2566487294 ErDD3PrmrSdPwrMnmmLmtSttng "ER DC/DC 3 Primary Side Power Minimum Limit Setting: Reports the active minimum primary side power limit of the Extended Range DC/DC Converter.  The setting may be requested by a separate device (via SPN 24205 (ER DC/DC 3 Primary Side Power Minimum L...";
CM_ SG_ 2566487294 ErDD3PrmrSdPwrMxmmLmtSttng "ER DC/DC 3 Primary Side Power Maximum Limit Setting: Reports the active maximum primary side power limit of the Extended Range DC/DC Converter.  The setting may be requested by a separate device (via SPN 24206 (ER DC/DC 3 Primary Side Power Maximum L...";
CM_ SG_ 2566487294 ErDD3SndrSdPwrMnmmLmtSttng "ER DC/DC 3 Secondary Side Power Minimum Limit Setting: Reports the active minimum secondary side power limit of the Extended Range DC/DC Converter.  The setting may be requested by a separate device (via SPN 24207 (ER DC/DC 3 Secondary Side Power Min...";
CM_ SG_ 2566487294 ErDD3SndrSdPwrMxmmLmtSttng "ER DC/DC 3 Secondary Side Power Maximum Limit Setting: Reports the active maximum secondary side power limit of the Extended Range DC/DC Converter.  The setting may be requested by a separate device (via SPN 24208 (ER DC/DC 3 Secondary Side Power Max...";
CM_ BO_ 2566487550 "ER DC/DC Converter 3 Current Limits Settings";
CM_ SG_ 2566487550 ErDD3PrmrSdCrrntMnmmLmtSttng "ER DC/DC 3 Primary Side Current Minimum Limit Setting: Reports the active minimum limit (negative) on the Primary Side current of the Extended Range DC/DC Converter.  The setting may be requested by a separate device (via SPN 24201 (ER DC/DC 3 Primar...";
CM_ SG_ 2566487550 ErDD3PrmrSdCrrntMxmmLmtSttng "ER DC/DC 3 Primary Side Current Maximum Limit Setting: Reports the active maximum limit on the Primary Side current of the Extended Range DC/DC Converter.  The setting may be requested by a separate device (via SPN 24202 (ER DC/DC 3 Primary Side Curr...";
CM_ SG_ 2566487550 ErDD3SndrSdCrrntMnmmLmtSttng "ER DC/DC 3 Secondary Side Current Minimum Limit Setting: Reports the active minimum limit (negative) on the Secondary Side current of the Extended Range DC/DC Converter.  The setting may be requested by a separate device (via SPN 24203 (ER DC/DC 3 Se...";
CM_ SG_ 2566487550 ErDD3SndrSdCrrntMxmmLmtSttng "ER DC/DC 3 Secondary Side Current Maximum Limit Setting: Reports the active maximum limit on the Secondary Side current of the Extended Range DC/DC Converter.  The setting may be requested by a separate device (via SPN 24204 (ER DC/DC 3 Secondary Sid...";
CM_ BO_ 2566487806 "ER DC/DC Converter 3 Voltage Limit Settings";
CM_ SG_ 2566487806 ErDD3PrmrSdVltgMnmmLmtSttng "ER DC/DC 3 Primary Side Voltage Minimum Limit Setting: Reports the active minimum limit on the Primary Side voltage of the Extended Range DC/DC Converter.  The setting may be requested by a separate device (via SPN 24197 (ER DC/DC 3 Primary Side Volt...";
CM_ SG_ 2566487806 ErDD3PrmrSdVltgMxmmLmtSttng "ER DC/DC 3 Primary Side Voltage Maximum Limit Setting: Reports the active maximum limit on the Primary Side voltage of the Extended Range DC/DC Converter.  The setting may be requested by a separate device (via SPN 24198 (ER DC/DC 3 Primary Side Volt...";
CM_ SG_ 2566487806 ErDD3SndrSdVltgMnmmLmtSttng "ER DC/DC 3 Secondary Side Voltage Minimum Limit Setting: Reports the active minimum limit on the Secondary Side voltage of the Extended Range DC/DC Converter.  The setting may be requested by a separate device (via SPN 24199 (ER DC/DC 3 Secondary Sid...";
CM_ SG_ 2566487806 ErDD3SndrSdVltgMxmmLmtSttng "ER DC/DC 3 Secondary Side Voltage Maximum Limit Setting: Reports the active maximum limit on the Secondary Side voltage of the Extended Range DC/DC Converter.  The setting may be requested by a separate device (via SPN 24200 (ER DC/DC 3 Secondary Sid...";
CM_ BO_ 2365161470 "ER DC/DC Converter 3 Low Voltage";
CM_ SG_ 2365161470 ErDD3CntrllrInptIgntnVltg "ER DC/DC 3 Controller Input Ignition Voltage: Ignition voltage (i.e. switched) supplied to the  Extended Range DC/DC Converter controller.";
CM_ SG_ 2365161470 ErDD3CntrllrInptUnswthdSlVltg "ER DC/DC 3 Controller Input Unswitched SLI Voltage: Continuously supplied SLI power to this instance of the Extended Range DC/DC Converter controller.";
CM_ BO_ 2365161726 "ER DC/DC Converter 3 Power and Chassis Voltage";
CM_ SG_ 2365161726 ErDcDc3PrimarySidePower "ER DC/DC 3 Primary Side Power: Indicates the Primary Side power measured at the Extended Range DC/DC Converter.  The Primary Side power is positive if the converter is flowing current from the Secondary Side to the Primary side.  The Primary Side pow...";
CM_ SG_ 2365161726 ErDcDc3SecondarySidePower "ER DC/DC 3 Secondary Side Power: Indicates the Secondary Side power measured at the Extended Range DC/DC Converter.  The Secondary Side power is positive if the converter is flowing current from the Primary Side to the Secondary side.  The Secondary ...";
CM_ SG_ 2365161726 ErDD3PrmrSdNgtvTChsssGrndVltg "ER DC/DC 3 Primary Side Negative to Chassis Ground Voltage: The voltage level as measured by the ER DC/DC between the Primary Side negative ER DC bus and the chassis of the ER DC/DC enclosure.  This voltage can be used for system level monitoring of ...";
CM_ SG_ 2365161726 ErDD3SndrSdNgtvTChsssGrndVltg "ER DC/DC 3 Secondary Side Negative to Chassis Ground Voltage: The voltage level as measured by the ER DC/DC between the Secondary Side negative ER DC bus and the chassis of the ER DC/DC enclosure.  This voltage can be used for system level monitoring...";
CM_ BO_ 2365161982 "ER DC/DC Converter 3 Voltage and Current";
CM_ SG_ 2365161982 ErDcDc3PrimarySideVoltage "ER DC/DC 3 Primary Side Voltage: Indicates the measured Primary Side voltage measured at the point of control inside the Extended Range DC/DC Converter.Refer to SPN 24212 (ER DC/DC 3 Reference Voltage) to convert % to Volts.";
CM_ SG_ 2365161982 ErDcDc3SecondarySideVoltage "ER DC/DC 3 Secondary Side Voltage: Indicates the measured Secondary Side voltage measured at the point of control inside the Extended Range DC/DC Converter.Refer to SPN 24212 (ER DC/DC 3 Reference Voltage) to convert % to Volts.";
CM_ SG_ 2365161982 ErDcDc3PrimarySideCurrent "ER DC/DC 3 Primary Side Current: Indicates the measured Primary Side current measured at the point of control inside the Extended Range DC/DC Converter.  The current is positive if the converter is flowing current from the Secondary to the Primary Si...";
CM_ SG_ 2365161982 ErDcDc3SecondarySideCurrent "ER DC/DC 3 Secondary Side Current: Indicates the measured Secondary Side current measured at the point of control inside the Extended Range DC/DC Converter.  The current is positive if the converter is flowing current from the Primary to the Secondar...";
CM_ BO_ 2365162238 "ER DC/DC Converter 3 Operating Status";
CM_ SG_ 2365162238 ErDcDc3StatusCrc "ER DC/DC 3 Status CRC: The CRC is defined as follows: - Length: 8 bits- Polynomial: x^8+x^5+x^3+x^2+x+1- Initial Value: FFh- Input Data Reflection: Not reflected- Result Data Reflection: Not reflected- XOR value: FFh SAE makes no claim of the functio...";
CM_ SG_ 2365162238 ErDcDc3StatusCounter "ER DC/DC 3 Status Counter: The message counter is used to detect situations where the transmitting ECU malfunction repeats the same frame all the time. The receiver of the information may use the counter parameter to detect this situation. The transm...";
CM_ SG_ 2365162238 ErDcDc3OperationalStatus "ER DC/DC 3 Operational Status: Operating state of the Extended Range DC/DC Converter0000b = Disabled - In this mode all high voltage switching is disabled0001b = Initialization - The device is powering up.  This process may include both internal chec...";
CM_ SG_ 2365162238 ErDcDc3HvilStatus "ER DC/DC 3 HVIL Status: High Voltage Interlock Loop (HVIL) state of the Extended Range DC/DC Converter.00b = HVIL Closed01b = HVIL Open10b = Error11b = Not Available";
CM_ SG_ 2365162238 ErDcDc3LoadshedRequest "ER DC/DC 3 Loadshed Request: The loadshed request is a request to the controlling device to reduce the Extended Range DC/DC Converter loads.  The Loadshed Requested state is an indication that this Extended Range DC/DC Converter has a malfunction or ...";
CM_ SG_ 2365162238 ErDD3PwrLmtDTPrmrSdCrrntMnmm "ER DC/DC 3 Power Limit due to Primary Side Current Minimum: Indicates whether or not output power is being limited due to Primary Side current (see SPN 24172 (ER DC/DC 3 Primary Side Current)) approaching or exceeding the minimum limit (see SPN 24184...";
CM_ SG_ 2365162238 ErDD3PwrLmtDTPrmrSdCrrntMxmm "ER DC/DC 3 Power Limit due to Primary Side Current Maximum: Indicates whether or not output power is being limited due to Primary Side current (see SPN 24172 (ER DC/DC 3 Primary Side Current)) approaching or exceeding the maximum limit (see SPN 24185...";
CM_ SG_ 2365162238 ErDD3PwrLmtDTSndrSdCrrntMnmm "ER DC/DC 3 Power Limit due to Secondary Side Current Minimum: Indicates whether or not output power is being limited due to Secondary Side current (see SPN 24173 (ER DC/DC 3 Secondary Side Current)) approaching or exceeding the minimum limit (see SPN...";
CM_ SG_ 2365162238 ErDD3PwrLmtDTSndrSdCrrntMxmm "ER DC/DC 3 Power Limit due to Secondary Side Current Maximum: Indicates whether or not output power is being limited due to Secondary Side current (see SPN 24173 (ER DC/DC 3 Secondary Side Current)) approaching or exceeding the maximum limit (see SPN...";
CM_ SG_ 2365162238 ErDD3PwrLmtDTPrmrSdVltgMnmm "ER DC/DC 3 Power Limit due to Primary Side Voltage Minimum: Indicates whether or not output power is being limited due to Primary Side voltage (see SPN 24170 (ER DC/DC 3 Primary Side Voltage)) approaching or exceeding the minimum limit (see SPN 24180...";
CM_ SG_ 2365162238 ErDD3PwrLmtDTPrmrSdVltgMxmm "ER DC/DC 3 Power Limit due to Primary Side Voltage Maximum: Indicates whether or not output power is being limited due to Primary Side voltage (see SPN 24170 (ER DC/DC 3 Primary Side Voltage)) approaching or exceeding the maximum limit (see SPN 24181...";
CM_ SG_ 2365162238 ErDD3PwrLmtDTSndrSdVltgMnmm "ER DC/DC 3 Power Limit due to Secondary Side Voltage Minimum: Indicates whether or not output power is being limited due to Secondary Side voltage (see SPN 24171 (ER DC/DC 3 Secondary Side Voltage)) approaching or exceeding the minimum limit (see SPN...";
CM_ SG_ 2365162238 ErDD3PwrLmtDTSndrSdVltgMxmm "ER DC/DC 3 Power Limit due to Secondary Side Voltage Maximum: Indicates whether or not output power is being limited due to Secondary Side voltage (see SPN 24171 (ER DC/DC 3 Secondary Side Voltage)) approaching or exceeding the maximum limit (see SPN...";
CM_ SG_ 2365162238 ErDD3PwrLmtDTCnvrtrTmprtr "ER DC/DC 3 Power Limit due to Converter Temperature: Indicates whether or not output power is being limited due to Converter Temperature (see SPN 24192 (ER DC/DC 3 Converter Temperature)) approaching or exceeding the maximum limit.00b = No power limi...";
CM_ SG_ 2365162238 ErDD3PwrLmtDTEltrnFltrTmprtr "ER DC/DC 3 Power Limit due to Electronic Filter Temperature: Indicates whether or not output power is being limited due to Output Electronic Filter Temperature (see SPN 24193 (ER DC/DC 3 Converter Electronic Filter Temperature)) approaching or exceed...";
CM_ SG_ 2365162238 ErDD3PwrLmtDTPwrEltrnsTmprtr "ER DC/DC 3 Power Limit due to Power Electronics Temperature: Indicates whether or not output power is being limited due to Power Electronics Temperature (see SPN 24194 (ER DC/DC 3 Power Electronics Temperature)) approaching or exceeding the maximum l...";
CM_ SG_ 2365162238 ErDD3PwrLmtDTUndfndRsn "ER DC/DC 3 Power Limit due to Undefined Reason: Indicates whether or not output power is being limited due to an undefined reason.00b = No power limit for this reason01b = Power limited for this reason10b = Error11b = Not Available";
BA_DEF_ SG_  "SPN" INT 0 524287;
BA_DEF_ BO_  "VFrameFormat" ENUM  "StandardCAN","ExtendedCAN","reserved","J1939PG";
BA_DEF_DEF_  "SPN" 0;
BA_DEF_DEF_  "VFrameFormat" "J1939PG";
BA_ "SPN" SG_ 2365189118 HvssHghVltgIntrnlPstvCnttr1Stt 23342;
BA_ "SPN" SG_ 2365189118 HvssHghVltgIntrnlNgtvCnttr1Stt 23343;
BA_ "SPN" SG_ 2365189118 HvssHghVltgIntrnlPrhrgRl1Stt 23344;
BA_ "SPN" SG_ 2365189118 HvssTMtSstItHt1Stts 23345;
BA_ "SPN" SG_ 2365189118 HvssHghVltgIntrnlBsVltgLvl1 23346;
BA_ "SPN" SG_ 2365189118 HvssHghVltgIntrnlPstvCnttr2Stt 23347;
BA_ "SPN" SG_ 2365189118 HvssHghVltgIntrnlNgtvCnttr2Stt 23348;
BA_ "SPN" SG_ 2365189118 HvssHghVltgIntrnlPrhrgRl2Stt 23349;
BA_ "SPN" SG_ 2365189118 HvssTMtSstItHt2Stts 23350;
BA_ "SPN" SG_ 2365189118 HvssHghVltgIntrnlBsVltgLvl2 23351;
BA_ "SPN" SG_ 2365189374 HvssHghVltgIntrnlPstvCnttr3Stt 23352;
BA_ "SPN" SG_ 2365189374 HvssHghVltgIntrnlNgtvCnttr3Stt 23353;
BA_ "SPN" SG_ 2365189374 HvssHghVltgIntrnlPrhrgRl3Stt 23354;
BA_ "SPN" SG_ 2365189374 HvssTMtSstItHt3Stts 23355;
BA_ "SPN" SG_ 2365189374 HvssHghVltgIntrnlBsVltgLvl3 23356;
BA_ "SPN" SG_ 2365189374 HvssHghVltgIntrnlPstvCnttr4Stt 23357;
BA_ "SPN" SG_ 2365189374 HvssHghVltgIntrnlNgtvCnttr4Stt 23358;
BA_ "SPN" SG_ 2365189374 HvssHghVltgIntrnlPrhrgRl4Stt 23359;
BA_ "SPN" SG_ 2365189374 HvssTMtSstItHt4Stts 23360;
BA_ "SPN" SG_ 2365189374 HvssHghVltgIntrnlBsVltgLvl4 23361;
BA_ "SPN" SG_ 2365189630 HvssNmrOfIntrnlCrtsRd 23362;
BA_ "SPN" SG_ 2566516478 EngnClndr1AvrgIgntnDlAngl 23298;
BA_ "SPN" SG_ 2566516478 EngnClndr2AvrgIgntnDlAngl 23299;
BA_ "SPN" SG_ 2566516478 EngnClndr3AvrgIgntnDlAngl 23300;
BA_ "SPN" SG_ 2566516478 EngnClndr4AvrgIgntnDlAngl 23301;
BA_ "SPN" SG_ 2566516734 EngnClndr5AvrgIgntnDlAngl 23302;
BA_ "SPN" SG_ 2566516734 EngnClndr6AvrgIgntnDlAngl 23303;
BA_ "SPN" SG_ 2566516734 EngnClndr7AvrgIgntnDlAngl 23304;
BA_ "SPN" SG_ 2566516734 EngnClndr8AvrgIgntnDlAngl 23305;
BA_ "SPN" SG_ 2566516990 EngnClndr9AvrgIgntnDlAngl 23306;
BA_ "SPN" SG_ 2566516990 EngnClndr10AvrgIgntnDlAngl 23307;
BA_ "SPN" SG_ 2566516990 EngnClndr11AvrgIgntnDlAngl 23308;
BA_ "SPN" SG_ 2566516990 EngnClndr12AvrgIgntnDlAngl 23309;
BA_ "SPN" SG_ 2566517246 EngnClndr13AvrgIgntnDlAngl 23310;
BA_ "SPN" SG_ 2566517246 EngnClndr14AvrgIgntnDlAngl 23311;
BA_ "SPN" SG_ 2566517246 EngnClndr15AvrgIgntnDlAngl 23312;
BA_ "SPN" SG_ 2566517246 EngnClndr16AvrgIgntnDlAngl 23313;
BA_ "SPN" SG_ 2566517502 EngnClndr17AvrgIgntnDlAngl 23314;
BA_ "SPN" SG_ 2566517502 EngnClndr18AvrgIgntnDlAngl 23315;
BA_ "SPN" SG_ 2566517502 EngnClndr19AvrgIgntnDlAngl 23316;
BA_ "SPN" SG_ 2566517502 EngnClndr20AvrgIgntnDlAngl 23317;
BA_ "SPN" SG_ 2566517758 ECd1IdtdMEtvPssPwB 23318;
BA_ "SPN" SG_ 2566517758 ECd2IdtdMEtvPssPwB 23319;
BA_ "SPN" SG_ 2566517758 ECd3IdtdMEtvPssPwB 23320;
BA_ "SPN" SG_ 2566517758 ECd4IdtdMEtvPssPwB 23321;
BA_ "SPN" SG_ 2566517758 ECd5IdtdMEtvPssPwB 23322;
BA_ "SPN" SG_ 2566517758 ECd6IdtdMEtvPssPwB 23323;
BA_ "SPN" SG_ 2566517758 ECd7IdtdMEtvPssPwB 23324;
BA_ "SPN" SG_ 2566517758 ECd8IdtdMEtvPssPwB 23325;
BA_ "SPN" SG_ 2566518014 ECd9IdtdMEtvPssPwB 23326;
BA_ "SPN" SG_ 2566518014 ECd10IdtdMEtvPssPwB 23327;
BA_ "SPN" SG_ 2566518014 ECd11IdtdMEtvPssPwB 23328;
BA_ "SPN" SG_ 2566518014 ECd12IdtdMEtvPssPwB 23329;
BA_ "SPN" SG_ 2566518014 ECd13IdtdMEtvPssPwB 23330;
BA_ "SPN" SG_ 2566518014 ECd14IdtdMEtvPssPwB 23331;
BA_ "SPN" SG_ 2566518014 ECd15IdtdMEtvPssPwB 23332;
BA_ "SPN" SG_ 2566518014 ECd16IdtdMEtvPssPwB 23333;
BA_ "SPN" SG_ 2566518270 ECd17IdtdMEtvPssPwB 23334;
BA_ "SPN" SG_ 2566518270 ECd18IdtdMEtvPssPwB 23335;
BA_ "SPN" SG_ 2566518270 ECd19IdtdMEtvPssPwB 23336;
BA_ "SPN" SG_ 2566518270 ECd20IdtdMEtvPssPwB 23337;
BA_ "SPN" SG_ 2566518270 ECd21IdtdMEtvPssPwB 23338;
BA_ "SPN" SG_ 2566518270 ECd22IdtdMEtvPssPwB 23339;
BA_ "SPN" SG_ 2566518270 ECd23IdtdMEtvPssPwB 23340;
BA_ "SPN" SG_ 2566518270 ECd24IdtdMEtvPssPwB 23341;
BA_ "SPN" SG_ 2566518526 FlCllSstmClntFn1EnlCmmnd 23228;
BA_ "SPN" SG_ 2566518526 FlCllSstmClntFn1PwrHld 23229;
BA_ "SPN" SG_ 2566518526 FlCllSstmClntFn1SpdCmmnd 23230;
BA_ "SPN" SG_ 2566518526 FlCllSstmClntFn1PrntSpdCmmnd 23231;
BA_ "SPN" SG_ 2566518526 FCSstCtF1CdEdddIttSppt 23547;
BA_ "SPN" SG_ 2566518526 FlCllSstmClntFn1CmmndCntr 23548;
BA_ "SPN" SG_ 2566518526 FlCllSstmClntFn1CmmndCr 23549;
BA_ "SPN" SG_ 2566518782 FlCllSstmClntFn1MtrSpdStts 23232;
BA_ "SPN" SG_ 2566518782 FCSstCtF1CtSttsRsCd 23233;
BA_ "SPN" SG_ 2566518782 FCSstCtF1CtCdStts 23234;
BA_ "SPN" SG_ 2566518782 FlCllSstmClntFn1MtrSpd 23235;
BA_ "SPN" SG_ 2566518782 FlCllSstmClntFn1CntrlTmprtr 23236;
BA_ "SPN" SG_ 2566518782 FuelCellSystemCoolantFan1Power 23237;
BA_ "SPN" SG_ 2566518782 FlCllSstmClntFn1SrvIndtr 23238;
BA_ "SPN" SG_ 2566518782 FlCllSstmClntFn1OprtngStts 23239;
BA_ "SPN" SG_ 2566519038 FlCllSstmClntFn2EnlCmmnd 23245;
BA_ "SPN" SG_ 2566519038 FlCllSstmClntFn2PwrHld 23246;
BA_ "SPN" SG_ 2566519038 FlCllSstmClntFn2SpdCmmnd 23247;
BA_ "SPN" SG_ 2566519038 FlCllSstmClntFn2PrntSpdCmmnd 23248;
BA_ "SPN" SG_ 2566519038 FCSstCtF2CdEdddIttSppt 23550;
BA_ "SPN" SG_ 2566519038 FlCllSstmClntFn2CmmndCntr 23551;
BA_ "SPN" SG_ 2566519038 FlCllSstmClntFn2CmmndCr 23552;
BA_ "SPN" SG_ 2566519294 FlCllSstmClntFn2MtrSpdStts 23249;
BA_ "SPN" SG_ 2566519294 FCSstCtF2CtSttsRsCd 23250;
BA_ "SPN" SG_ 2566519294 FCSstCtF2CtCdStts 23251;
BA_ "SPN" SG_ 2566519294 FlCllSstmClntFn2MtrSpd 23252;
BA_ "SPN" SG_ 2566519294 FlCllSstmClntFn2CntrlTmprtr 23253;
BA_ "SPN" SG_ 2566519294 FuelCellSystemCoolantFan2Power 23254;
BA_ "SPN" SG_ 2566519294 FlCllSstmClntFn2SrvIndtr 23255;
BA_ "SPN" SG_ 2566519294 FlCllSstmClntFn2OprtngStts 23256;
BA_ "SPN" SG_ 2566519550 FlCllSstmClntFn3EnlCmmnd 23262;
BA_ "SPN" SG_ 2566519550 FlCllSstmClntFn3PwrHld 23263;
BA_ "SPN" SG_ 2566519550 FlCllSstmClntFn3SpdCmmnd 23264;
BA_ "SPN" SG_ 2566519550 FlCllSstmClntFn3PrntSpdCmmnd 23265;
BA_ "SPN" SG_ 2566519550 FCSstCtF3CdEdddIttSppt 23553;
BA_ "SPN" SG_ 2566519550 FlCllSstmClntFn3CmmndCntr 23554;
BA_ "SPN" SG_ 2566519550 FlCllSstmClntFn3CmmndCr 23555;
BA_ "SPN" SG_ 2566519806 FlCllSstmClntFn3MtrSpdStts 23266;
BA_ "SPN" SG_ 2566519806 FCSstCtF3CtSttsRsCd 23267;
BA_ "SPN" SG_ 2566519806 FCSstCtF3CtCdStts 23268;
BA_ "SPN" SG_ 2566519806 FlCllSstmClntFn3MtrSpd 23269;
BA_ "SPN" SG_ 2566519806 FlCllSstmClntFn3CntrlTmprtr 23270;
BA_ "SPN" SG_ 2566519806 FuelCellSystemCoolantFan3Power 23271;
BA_ "SPN" SG_ 2566519806 FlCllSstmClntFn3SrvIndtr 23272;
BA_ "SPN" SG_ 2566519806 FlCllSstmClntFn3OprtngStts 23273;
BA_ "SPN" SG_ 2566520062 FlCllSstmClntFn4EnlCmmnd 23279;
BA_ "SPN" SG_ 2566520062 FlCllSstmClntFn4PwrHld 23280;
BA_ "SPN" SG_ 2566520062 FlCllSstmClntFn4SpdCmmnd 23281;
BA_ "SPN" SG_ 2566520062 FlCllSstmClntFn4PrntSpdCmmnd 23282;
BA_ "SPN" SG_ 2566520062 FCSstCtF4CdEdddIttSppt 23556;
BA_ "SPN" SG_ 2566520062 FlCllSstmClntFn4CmmndCntr 23557;
BA_ "SPN" SG_ 2566520062 FlCllSstmClntFn4CmmndCr 23558;
BA_ "SPN" SG_ 2566520318 FlCllSstmClntFn4MtrSpdStts 23283;
BA_ "SPN" SG_ 2566520318 FCSstCtF4CtSttsRsCd 23284;
BA_ "SPN" SG_ 2566520318 FCSstCtF4CtCdStts 23285;
BA_ "SPN" SG_ 2566520318 FlCllSstmClntFn4MtrSpd 23286;
BA_ "SPN" SG_ 2566520318 FlCllSstmClntFn4CntrlTmprtr 23287;
BA_ "SPN" SG_ 2566520318 FuelCellSystemCoolantFan4Power 23288;
BA_ "SPN" SG_ 2566520318 FlCllSstmClntFn4SrvIndtr 23289;
BA_ "SPN" SG_ 2566520318 FlCllSstmClntFn4OprtngStts 23290;
BA_ "SPN" SG_ 2566520574 EvApiId 23214;
BA_ "SPN" SG_ 2566520574 EvApiManufacturerId 23215;
BA_ "SPN" SG_ 2566520574 EvApiSupportedRoles 23216;
BA_ "SPN" SG_ 2566520574 EvApiMajorVersion 23217;
BA_ "SPN" SG_ 2566520574 EvApiMinorVersion 23218;
BA_ "SPN" SG_ 2566520574 EvApiMinorVersionMinimum 23219;
BA_ "SPN" SG_ 2566520574 EvApiGrouping 23220;
BA_ "SPN" SG_ 2566520574 EvApiActiveByDefault 23221;
BA_ "SPN" SG_ 2566520830 FuelCellSystemConfigurationCrc 23142;
BA_ "SPN" SG_ 2566520830 FlCllSstmCnfgrtnCntr 23143;
BA_ "SPN" SG_ 2566520830 FuelCellSystemReferencePower 23144;
BA_ "SPN" SG_ 2566520830 FuelCellSystemReferenceCurrent 23145;
BA_ "SPN" SG_ 2566520830 FuelCellSystemReferenceVoltage 23146;
BA_ "SPN" SG_ 2566521086 FlCllSstmClntInltTmprtrStpnt 23201;
BA_ "SPN" SG_ 2566521086 FlCllSstmClntInltTmprtr 23202;
BA_ "SPN" SG_ 2566521086 FlCllStkClntInltTmprtr 23203;
BA_ "SPN" SG_ 2566521086 FlCllStkClntOtltTmprtr 23204;
BA_ "SPN" SG_ 2566521342 FuelCellSystemCoolantLevel 23205;
BA_ "SPN" SG_ 2566521342 FlCllStkInltClntAsltPrssr 23206;
BA_ "SPN" SG_ 2566521342 FuelCellSystemCoolantFlowRate 23207;
BA_ "SPN" SG_ 2566521342 FuelCellStackCoolantFlowRate 23208;
BA_ "SPN" SG_ 2566521342 FlCllSstmClntCndtvt 23209;
BA_ "SPN" SG_ 2566095102 HvessFanVoltage 23490;
BA_ "SPN" SG_ 2566095102 HvessFanCurrent 23491;
BA_ "SPN" SG_ 2566095102 HvessFanHvilStatus 23492;
BA_ "SPN" SG_ 2566095102 HvessFanStatus2Instance 23493;
BA_ "SPN" SG_ 2566095102 HvessFanPercentSpeedStatus 23494;
BA_ "SPN" SG_ 2566095102 HvessFanPercentSpeed 23495;
BA_ "SPN" SG_ 2566511614 EvseTempSensorType 23501;
BA_ "SPN" SG_ 2566511614 EvseConnectorTemperatureStatus 23502;
BA_ "SPN" SG_ 2566511614 EvChrgngInltCnntrTmprtr 23503;
BA_ "SPN" SG_ 2566511614 EvCItCtTptSsRsst 23504;
BA_ "SPN" SG_ 2566645502 HvessFanEnableCommand 8384;
BA_ "SPN" SG_ 2566645502 HvessFanPowerHold 8385;
BA_ "SPN" SG_ 2566645502 HvessFanSpeedCommand 8386;
BA_ "SPN" SG_ 2566645502 HvessFanPercentSpeedCommand 8387;
BA_ "SPN" SG_ 2566645502 HvessFanInstance1 8388;
BA_ "SPN" SG_ 2566645502 HvessFanInstance2 8389;
BA_ "SPN" SG_ 2566645502 HvessFanInstance3 8390;
BA_ "SPN" SG_ 2566645502 HvessFanInstance4 8391;
BA_ "SPN" SG_ 2566645502 HvessFanInstance5 8392;
BA_ "SPN" SG_ 2566645502 HvessFanInstance6 8393;
BA_ "SPN" SG_ 2566645502 HvessFanInstance7 8394;
BA_ "SPN" SG_ 2566645502 HvessFanInstance8 8395;
BA_ "SPN" SG_ 2566645502 HvessFanInstance9 8396;
BA_ "SPN" SG_ 2566645502 HvessFanInstance10 8397;
BA_ "SPN" SG_ 2566645502 HvessFanInstance11 8398;
BA_ "SPN" SG_ 2566645502 HvessFanInstance12 8399;
BA_ "SPN" SG_ 2566645502 HvessFanInstance13 8400;
BA_ "SPN" SG_ 2566645502 HvessFanInstance14 8401;
BA_ "SPN" SG_ 2566645502 HvessFanInstance15 8402;
BA_ "SPN" SG_ 2566645502 HVtEStSstFCdsEdddIttSppt 23544;
BA_ "SPN" SG_ 2566645502 HghVltgEnrgStrgSstmFnCmmndsCntr 23545;
BA_ "SPN" SG_ 2566645502 HghVltgEnrgStrgSstmFnCmmndsCr 23546;
BA_ "SPN" SG_ 2566504446 TripEnrichmentPercentTime 23735;
BA_ "SPN" SG_ 2566504446 TrpEnrhmntPrntTmDTAlrtrPdl 23736;
BA_ "SPN" SG_ 2566504446 TrpEnrhmntPrntTmDTEngnPrttn 23737;
BA_ "SPN" SG_ 2566504446 TpEtPtTDTAttttPtt 23738;
BA_ "SPN" SG_ 2566504446 LifetimeEnrichmentPercentTime 23739;
BA_ "SPN" SG_ 2566504446 LftmEnrhmntPrntTmDTAlrtrPdl 23740;
BA_ "SPN" SG_ 2566504446 LftmEnrhmntPrntTmDTEngnPrttn 23741;
BA_ "SPN" SG_ 2566504446 LtEtPtTDTAttttPtt 23742;
BA_ "SPN" SG_ 2566504702 FcsvlcCrc 23729;
BA_ "SPN" SG_ 2566504702 FcsvlcCounter 23730;
BA_ "SPN" SG_ 2566504702 FlCllSstmNmnlVltgCmmnd 23731;
BA_ "SPN" SG_ 2566504702 FlCllSstmMnmmOprtngVltgCmmnd 23732;
BA_ "SPN" SG_ 2566504702 FlCllSstmMxmmOprtngVltgCmmnd 23733;
BA_ "SPN" SG_ 2566505470 AuxiliaryIOChannel62 23719;
BA_ "SPN" SG_ 2566505470 AuxiliaryIOChannel61 23720;
BA_ "SPN" SG_ 2566505470 AuxiliaryIOChannel60 23721;
BA_ "SPN" SG_ 2566505470 AuxiliaryIOChannel59 23722;
BA_ "SPN" SG_ 2566505726 AuxiliaryIOChannel58 23715;
BA_ "SPN" SG_ 2566505726 AuxiliaryIOChannel57 23716;
BA_ "SPN" SG_ 2566505726 AuxiliaryIOChannel56 23717;
BA_ "SPN" SG_ 2566505726 AuxiliaryIOChannel55 23718;
BA_ "SPN" SG_ 2566505982 AuxiliaryIOChannel54 23711;
BA_ "SPN" SG_ 2566505982 AuxiliaryIOChannel53 23712;
BA_ "SPN" SG_ 2566505982 AuxiliaryIOChannel52 23713;
BA_ "SPN" SG_ 2566505982 AuxiliaryIOChannel51 23714;
BA_ "SPN" SG_ 2566506238 AuxiliaryIOChannel50 23707;
BA_ "SPN" SG_ 2566506238 AuxiliaryIOChannel49 23708;
BA_ "SPN" SG_ 2566506238 AuxiliaryIOChannel48 23709;
BA_ "SPN" SG_ 2566506238 AuxiliaryIOChannel47 23710;
BA_ "SPN" SG_ 2566506494 AuxiliaryIOChannel46 23703;
BA_ "SPN" SG_ 2566506494 AuxiliaryIOChannel45 23704;
BA_ "SPN" SG_ 2566506494 AuxiliaryIOChannel44 23705;
BA_ "SPN" SG_ 2566506494 AuxiliaryIOChannel43 23706;
BA_ "SPN" SG_ 2566506750 AuxiliaryIOChannel42 23699;
BA_ "SPN" SG_ 2566506750 AuxiliaryIOChannel41 23700;
BA_ "SPN" SG_ 2566506750 AuxiliaryIOChannel40 23701;
BA_ "SPN" SG_ 2566506750 AuxiliaryIOChannel39 23702;
BA_ "SPN" SG_ 2566507006 AuxiliaryIOChannel38 23695;
BA_ "SPN" SG_ 2566507006 AuxiliaryIOChannel37 23696;
BA_ "SPN" SG_ 2566507006 AuxiliaryIOChannel36 23697;
BA_ "SPN" SG_ 2566507006 AuxiliaryIOChannel35 23698;
BA_ "SPN" SG_ 2566507262 AuxiliaryIOChannel34 23691;
BA_ "SPN" SG_ 2566507262 AuxiliaryIOChannel33 23692;
BA_ "SPN" SG_ 2566507262 AuxiliaryIOChannel32 23693;
BA_ "SPN" SG_ 2566507262 AuxiliaryIOChannel31 23694;
BA_ "SPN" SG_ 2566507518 AuxiliaryIOChannel30 23687;
BA_ "SPN" SG_ 2566507518 AuxiliaryIOChannel29 23688;
BA_ "SPN" SG_ 2566507518 AuxiliaryIOChannel28 23689;
BA_ "SPN" SG_ 2566507518 AuxiliaryIOChannel27 23690;
BA_ "SPN" SG_ 2566507774 AuxiliaryIOChannel26 23683;
BA_ "SPN" SG_ 2566507774 AuxiliaryIOChannel25 23684;
BA_ "SPN" SG_ 2566507774 AuxiliaryIOChannel24 23685;
BA_ "SPN" SG_ 2566507774 AuxiliaryIOChannel23 23686;
BA_ "SPN" SG_ 2633616894 AftrtrtmntDslExhstFldEnm 23681;
BA_ "SPN" SG_ 2633616894 AftrtrtmntDslExhstFldLftmEnm 23682;
BA_ "SPN" SG_ 2566508286 BrkTmprtrRrAxl10LftWhl 23679;
BA_ "SPN" SG_ 2566508286 BrkTmprtrRrAxl10RghtWhl 23680;
BA_ "SPN" SG_ 2566508542 BrkTmprtrRrAxl8LftWhl 23675;
BA_ "SPN" SG_ 2566508542 BrkTmprtrRrAxl8RghtWhl 23676;
BA_ "SPN" SG_ 2566508542 BrkTmprtrRrAxl9LftWhl 23677;
BA_ "SPN" SG_ 2566508542 BrkTmprtrRrAxl9RghtWhl 23678;
BA_ "SPN" SG_ 2566508798 BrkTmprtrRrAxl6LftWhl 23671;
BA_ "SPN" SG_ 2566508798 BrkTmprtrRrAxl6RghtWhl 23672;
BA_ "SPN" SG_ 2566508798 BrkTmprtrRrAxl7LftWhl 23673;
BA_ "SPN" SG_ 2566508798 BrkTmprtrRrAxl7RghtWhl 23674;
BA_ "SPN" SG_ 2566509054 BrkTmprtrRrAxl4LftWhl 23667;
BA_ "SPN" SG_ 2566509054 BrkTmprtrRrAxl4RghtWhl 23668;
BA_ "SPN" SG_ 2566509054 BrkTmprtrRrAxl5LftWhl 23669;
BA_ "SPN" SG_ 2566509054 BrkTmprtrRrAxl5RghtWhl 23670;
BA_ "SPN" SG_ 2566509310 BrkTmprtrRrAxl2LftWhl 23663;
BA_ "SPN" SG_ 2566509310 BrkTmprtrRrAxl2RghtWhl 23664;
BA_ "SPN" SG_ 2566509310 BrkTmprtrRrAxl3LftWhl 23665;
BA_ "SPN" SG_ 2566509310 BrkTmprtrRrAxl3RghtWhl 23666;
BA_ "SPN" SG_ 2566509566 BrkTmprtrFrntAxlLftWhl 23659;
BA_ "SPN" SG_ 2566509566 BrkTmprtrFrntAxlRghtWhl 23660;
BA_ "SPN" SG_ 2566509566 BrkTmprtrRrAxl1LftWhl 23661;
BA_ "SPN" SG_ 2566509566 BrkTmprtrRrAxl1RghtWhl 23662;
BA_ "SPN" SG_ 2633618686 BrkLnngRmnngRrAxl8LftWhl 23653;
BA_ "SPN" SG_ 2633618686 BrkLnngRmnngRrAxl8RghtWhl 23654;
BA_ "SPN" SG_ 2633618686 BrkLnngRmnngRrAxl9LftWhl 23655;
BA_ "SPN" SG_ 2633618686 BrkLnngRmnngRrAxl9RghtWhl 23656;
BA_ "SPN" SG_ 2633618686 BrkLnngRmnngRrAxl10LftWhl 23657;
BA_ "SPN" SG_ 2633618686 BrkLnngRmnngRrAxl10RghtWhl 23658;
BA_ "SPN" SG_ 2633618942 BrkLnngRmnngRrAxl4LftWhl 23645;
BA_ "SPN" SG_ 2633618942 BrkLnngRmnngRrAxl4RghtWhl 23646;
BA_ "SPN" SG_ 2633618942 BrkLnngRmnngRrAxl5LftWhl 23647;
BA_ "SPN" SG_ 2633618942 BrkLnngRmnngRrAxl5RghtWhl 23648;
BA_ "SPN" SG_ 2633618942 BrkLnngRmnngRrAxl6LftWhl 23649;
BA_ "SPN" SG_ 2633618942 BrkLnngRmnngRrAxl6RghtWhl 23650;
BA_ "SPN" SG_ 2633618942 BrkLnngRmnngRrAxl7LftWhl 23651;
BA_ "SPN" SG_ 2633618942 BrkLnngRmnngRrAxl7RghtWhl 23652;
BA_ "SPN" SG_ 2365183742 Hvbcs3EmbeddedIntegritySupport 23642;
BA_ "SPN" SG_ 2365183742 Hvbcs3Counter 23643;
BA_ "SPN" SG_ 2365183742 Hvbcs3Crc 23644;
BA_ "SPN" SG_ 2365183998 Hvbcs2EmbeddedIntegritySupport 23639;
BA_ "SPN" SG_ 2365183998 Hvbcs2Counter 23640;
BA_ "SPN" SG_ 2365183998 Hvbcs2Crc 23641;
BA_ "SPN" SG_ 2365184254 HghVltgBsIntrf25CnntCmmnd 23628;
BA_ "SPN" SG_ 2365184254 HghVltgBsIntrf26CnntCmmnd 23629;
BA_ "SPN" SG_ 2365184254 HghVltgBsIntrf27CnntCmmnd 23630;
BA_ "SPN" SG_ 2365184254 HghVltgBsIntrf28CnntCmmnd 23631;
BA_ "SPN" SG_ 2365184254 HghVltgBsIntrf29CnntCmmnd 23632;
BA_ "SPN" SG_ 2365184254 HghVltgBsIntrf30CnntCmmnd 23633;
BA_ "SPN" SG_ 2365184254 HghVltgBsIntrf31CnntCmmnd 23634;
BA_ "SPN" SG_ 2365184254 HghVltgBsIntrf32CnntCmmnd 23635;
BA_ "SPN" SG_ 2365184254 Hvbcc2EmbeddedIntegritySupport 23636;
BA_ "SPN" SG_ 2365184254 Hvbcc2Counter 23637;
BA_ "SPN" SG_ 2365184254 Hvbcc2Crc 23638;
BA_ "SPN" SG_ 2566095358 EnlSwthTrnsmssnInptShftPt3 23765;
BA_ "SPN" SG_ 2566095358 EnlSwthTrnsmssnInptShftPt4 23768;
BA_ "SPN" SG_ 2566095358 EnggmntCnsntTrnsmssnInptShftPt3 23766;
BA_ "SPN" SG_ 2566095358 EnggmntCnsntTrnsmssnInptShftPt4 23769;
BA_ "SPN" SG_ 2566095358 EnggmntSttsTrnsmssnInptShftPt3 23767;
BA_ "SPN" SG_ 2566095358 EnggmntSttsTrnsmssnInptShftPt4 23770;
BA_ "SPN" SG_ 2364769022 FcshpCrc 23852;
BA_ "SPN" SG_ 2364769022 FcshpCounter 23853;
BA_ "SPN" SG_ 2364769022 FlCllSstmHdrgnInltPrssr 23854;
BA_ "SPN" SG_ 2566502142 EstmtdWllStmltnPmpLOlFlwRt 23861;
BA_ "SPN" SG_ 2566502142 AtlWllStmltnPmpLOlFlwRt 23862;
BA_ "SPN" SG_ 2566502142 EstmtdWllStmltnPmpGrBxLOlFlwRt 23863;
BA_ "SPN" SG_ 2566502142 AtlWllStmltnPmpGrBxLOlFlwRt 23864;
BA_ "SPN" SG_ 2566502398 WellStimulationPumpOilPressure 23858;
BA_ "SPN" SG_ 2566502398 WllStmltnPmpOtltOlPrssr 23859;
BA_ "SPN" SG_ 2566502398 WllStmltnPmpOtltOlTmprtr 23860;
BA_ "SPN" SG_ 2566502654 TireRollingDistance 23857;
BA_ "SPN" SG_ 2566502910 HydrogenRedLampData 23855;
BA_ "SPN" SG_ 2566502910 HydrogenYellowLampData 23856;
BA_ "SPN" SG_ 2566503166 RouteNumberOfWaypoints 23849;
BA_ "SPN" SG_ 2566503166 RouteWaypointLatitude 23850;
BA_ "SPN" SG_ 2566503166 RouteWaypointLongitude 23851;
BA_ "SPN" SG_ 2566503422 RouteRemainingTime 23845;
BA_ "SPN" SG_ 2566503422 RouteRemainingDistance 23846;
BA_ "SPN" SG_ 2566503422 RouteNextWaypoint 23847;
BA_ "SPN" SG_ 2566503422 RouteIdentifier 23848;
BA_ "SPN" SG_ 2566503678 EngnCrnksBrthrOlSprtrIntkPrssr 23844;
BA_ "SPN" SG_ 2566503934 FlCllSstmClntFlwRtExtnddRng 23776;
BA_ "SPN" SG_ 2566503934 FlCllStkClntFlwRtExtnddRng 23777;
BA_ "SPN" SG_ 2566504190 TransmissionMode1Configuration 23745;
BA_ "SPN" SG_ 2566504190 TransmissionMode2Configuration 23746;
BA_ "SPN" SG_ 2566504190 TransmissionMode3Configuration 23747;
BA_ "SPN" SG_ 2566504190 TransmissionMode4Configuration 23748;
BA_ "SPN" SG_ 2566504190 TransmissionMode5Configuration 23749;
BA_ "SPN" SG_ 2566504190 TransmissionMode6Configuration 23750;
BA_ "SPN" SG_ 2566504190 TransmissionMode7Configuration 23751;
BA_ "SPN" SG_ 2566504190 TransmissionMode8Configuration 23752;
BA_ "SPN" SG_ 2566504190 TransmissionMode9Configuration 23753;
BA_ "SPN" SG_ 2566504190 TransmissionMode10Configuration 23754;
BA_ "SPN" SG_ 2566504190 TransmissionMode11Configuration 23755;
BA_ "SPN" SG_ 2566504190 TransmissionMode12Configuration 23756;
BA_ "SPN" SG_ 2566504190 TransmissionMode13Configuration 23757;
BA_ "SPN" SG_ 2566504190 TransmissionMode14Configuration 23758;
BA_ "SPN" SG_ 2566504190 TransmissionMode15Configuration 23759;
BA_ "SPN" SG_ 2566504190 TransmissionMode16Configuration 23760;
BA_ "SPN" SG_ 2566504190 TransmissionMode17Configuration 23761;
BA_ "SPN" SG_ 2566504190 TransmissionMode18Configuration 23762;
BA_ "SPN" SG_ 2566504190 TransmissionMode19Configuration 23763;
BA_ "SPN" SG_ 2566504190 TransmissionMode20Configuration 23764;
BA_ "SPN" SG_ 2566505214 HydrogenRedLampCommand 23724;
BA_ "SPN" SG_ 2566505214 HydrogenYellowLampCommand 23725;
BA_ "SPN" SG_ 2566095870 EngnTrhrgr1CmprssrIntkFlwRt 23976;
BA_ "SPN" SG_ 2566095870 EngnTrhrgr2CmprssrIntkFlwRt 23977;
BA_ "SPN" SG_ 2566095870 EngnIntkArMssFlwRtExtnddRng 23978;
BA_ "SPN" SG_ 2566096126 EngnSprhrgr1BpssAttrPstn 23979;
BA_ "SPN" SG_ 2566096126 EngnSprhrgr2BpssAttrPstn 23980;
BA_ "SPN" SG_ 2566096126 EngnSprhrgr1ClthVlvCmmnd 23981;
BA_ "SPN" SG_ 2566096126 EngnSprhrgr2ClthVlvCmmnd 23982;
BA_ "SPN" SG_ 2566096126 EngineSupercharger1Speed 23983;
BA_ "SPN" SG_ 2566096126 EngineSupercharger2Speed 23984;
BA_ "SPN" SG_ 2365156094 ErDcDc4ReferenceCrc 24274;
BA_ "SPN" SG_ 2365156094 ErDcDc4ReferenceCounter 24275;
BA_ "SPN" SG_ 2365156094 ErDcDc4ReferenceCurrent 24276;
BA_ "SPN" SG_ 2365156094 ErDcDc4ReferenceVoltage 24277;
BA_ "SPN" SG_ 2365156094 ErDcDc4ReferencePower 24278;
BA_ "SPN" SG_ 2365156350 ErDD4PrmrSdPwrMnmmLmtRqst 24270;
BA_ "SPN" SG_ 2365156350 ErDD4PrmrSdPwrMxmmLmtRqst 24271;
BA_ "SPN" SG_ 2365156350 ErDD4SndrSdPwrMnmmLmtRqst 24272;
BA_ "SPN" SG_ 2365156350 ErDD4SndrSdPwrMxmmLmtRqst 24273;
BA_ "SPN" SG_ 2365156606 ErDD4PrmrSdCrrntMnmmLmtRqst 24266;
BA_ "SPN" SG_ 2365156606 ErDD4PrmrSdCrrntMxmmLmtRqst 24267;
BA_ "SPN" SG_ 2365156606 ErDD4SndrSdCrrntMnmmLmtRqst 24268;
BA_ "SPN" SG_ 2365156606 ErDD4SndrSdCrrntMxmmLmtRqst 24269;
BA_ "SPN" SG_ 2365156862 ErDD4PrmrSdVltgMnmmLmtRqst 24262;
BA_ "SPN" SG_ 2365156862 ErDD4PrmrSdVltgMxmmLmtRqst 24263;
BA_ "SPN" SG_ 2365156862 ErDD4SndrSdVltgMnmmLmtRqst 24264;
BA_ "SPN" SG_ 2365156862 ErDD4SndrSdVltgMxmmLmtRqst 24265;
BA_ "SPN" SG_ 2365157118 ErDcDc4ConverterTemperature 24257;
BA_ "SPN" SG_ 2365157118 ErDD4CnvrtrEltrnFltrTmprtr 24258;
BA_ "SPN" SG_ 2365157118 ErDD4PwrEltrnsTmprtr 24259;
BA_ "SPN" SG_ 2365157118 ErDcDc4CoolantInTemperature 24260;
BA_ "SPN" SG_ 2365157118 ErDcDc4CoolantOutTemperature 24261;
BA_ "SPN" SG_ 2566483966 ErDD4PrmrSdPwrMnmmLmtSttng 24253;
BA_ "SPN" SG_ 2566483966 ErDD4PrmrSdPwrMxmmLmtSttng 24254;
BA_ "SPN" SG_ 2566483966 ErDD4SndrSdPwrMnmmLmtSttng 24255;
BA_ "SPN" SG_ 2566483966 ErDD4SndrSdPwrMxmmLmtSttng 24256;
BA_ "SPN" SG_ 2566484222 ErDD4PrmrSdCrrntMnmmLmtSttng 24249;
BA_ "SPN" SG_ 2566484222 ErDD4PrmrSdCrrntMxmmLmtSttng 24250;
BA_ "SPN" SG_ 2566484222 ErDD4SndrSdCrrntMnmmLmtSttng 24251;
BA_ "SPN" SG_ 2566484222 ErDD4SndrSdCrrntMxmmLmtSttng 24252;
BA_ "SPN" SG_ 2566484478 ErDD4PrmrSdVltgMnmmLmtSttng 24245;
BA_ "SPN" SG_ 2566484478 ErDD4PrmrSdVltgMxmmLmtSttng 24246;
BA_ "SPN" SG_ 2566484478 ErDD4SndrSdVltgMnmmLmtSttng 24247;
BA_ "SPN" SG_ 2566484478 ErDD4SndrSdVltgMxmmLmtSttng 24248;
BA_ "SPN" SG_ 2365158142 ErDD4CntrllrInptIgntnVltg 24243;
BA_ "SPN" SG_ 2365158142 ErDD4CntrllrInptUnswthdSlVltg 24244;
BA_ "SPN" SG_ 2365158398 ErDcDc4PrimarySidePower 24239;
BA_ "SPN" SG_ 2365158398 ErDcDc4SecondarySidePower 24240;
BA_ "SPN" SG_ 2365158398 ErDD4PrmrSdNgtvTChsssGrndVltg 24241;
BA_ "SPN" SG_ 2365158398 ErDD4SndrSdNgtvTChsssGrndVltg 24242;
BA_ "SPN" SG_ 2365158654 ErDcDc4PrimarySideVoltage 24235;
BA_ "SPN" SG_ 2365158654 ErDcDc4SecondarySideVoltage 24236;
BA_ "SPN" SG_ 2365158654 ErDcDc4PrimarySideCurrent 24237;
BA_ "SPN" SG_ 2365158654 ErDcDc4SecondarySideCurrent 24238;
BA_ "SPN" SG_ 2365158910 ErDcDc4StatusCrc 24218;
BA_ "SPN" SG_ 2365158910 ErDcDc4StatusCounter 24219;
BA_ "SPN" SG_ 2365158910 ErDcDc4OperationalStatus 24220;
BA_ "SPN" SG_ 2365158910 ErDcDc4HvilStatus 24221;
BA_ "SPN" SG_ 2365158910 ErDcDc4LoadshedRequest 24222;
BA_ "SPN" SG_ 2365158910 ErDD4PwrLmtDTPrmrSdCrrntMnmm 24223;
BA_ "SPN" SG_ 2365158910 ErDD4PwrLmtDTPrmrSdCrrntMxmm 24224;
BA_ "SPN" SG_ 2365158910 ErDD4PwrLmtDTSndrSdCrrntMnmm 24225;
BA_ "SPN" SG_ 2365158910 ErDD4PwrLmtDTSndrSdCrrntMxmm 24226;
BA_ "SPN" SG_ 2365158910 ErDD4PwrLmtDTPrmrSdVltgMnmm 24227;
BA_ "SPN" SG_ 2365158910 ErDD4PwrLmtDTPrmrSdVltgMxmm 24228;
BA_ "SPN" SG_ 2365158910 ErDD4PwrLmtDTSndrSdVltgMnmm 24229;
BA_ "SPN" SG_ 2365158910 ErDD4PwrLmtDTSndrSdVltgMxmm 24230;
BA_ "SPN" SG_ 2365158910 ErDD4PwrLmtDTCnvrtrTmprtr 24231;
BA_ "SPN" SG_ 2365158910 ErDD4PwrLmtDTEltrnFltrTmprtr 24232;
BA_ "SPN" SG_ 2365158910 ErDD4PwrLmtDTPwrEltrnsTmprtr 24233;
BA_ "SPN" SG_ 2365158910 ErDD4PwrLmtDTUndfndRsn 24234;
BA_ "SPN" SG_ 2365159166 ErDcDc4CommandCrc 24214;
BA_ "SPN" SG_ 2365159166 ErDcDc4CommandCounter 24215;
BA_ "SPN" SG_ 2365159166 ErDcDc4OperationalCommand 24216;
BA_ "SPN" SG_ 2365159166 ErDcDc4OperationalSetpoint 24217;
BA_ "SPN" SG_ 2365159422 ErDcDc3ReferenceCrc 24209;
BA_ "SPN" SG_ 2365159422 ErDcDc3ReferenceCounter 24210;
BA_ "SPN" SG_ 2365159422 ErDcDc3ReferenceCurrent 24211;
BA_ "SPN" SG_ 2365159422 ErDcDc3ReferenceVoltage 24212;
BA_ "SPN" SG_ 2365159422 ErDcDc3ReferencePower 24213;
BA_ "SPN" SG_ 2365159678 ErDD3PrmrSdPwrMnmmLmtRqst 24205;
BA_ "SPN" SG_ 2365159678 ErDD3PrmrSdPwrMxmmLmtRqst 24206;
BA_ "SPN" SG_ 2365159678 ErDD3SndrSdPwrMnmmLmtRqst 24207;
BA_ "SPN" SG_ 2365159678 ErDD3SndrSdPwrMxmmLmtRqst 24208;
BA_ "SPN" SG_ 2365159934 ErDD3PrmrSdCrrntMnmmLmtRqst 24201;
BA_ "SPN" SG_ 2365159934 ErDD3PrmrSdCrrntMxmmLmtRqst 24202;
BA_ "SPN" SG_ 2365159934 ErDD3SndrSdCrrntMnmmLmtRqst 24203;
BA_ "SPN" SG_ 2365159934 ErDD3SndrSdCrrntMxmmLmtRqst 24204;
BA_ "SPN" SG_ 2365160190 ErDD3PrmrSdVltgMnmmLmtRqst 24197;
BA_ "SPN" SG_ 2365160190 ErDD3PrmrSdVltgMxmmLmtRqst 24198;
BA_ "SPN" SG_ 2365160190 ErDD3SndrSdVltgMnmmLmtRqst 24199;
BA_ "SPN" SG_ 2365160190 ErDD3SndrSdVltgMxmmLmtRqst 24200;
BA_ "SPN" SG_ 2365160446 ErDcDc3ConverterTemperature 24192;
BA_ "SPN" SG_ 2365160446 ErDD3CnvrtrEltrnFltrTmprtr 24193;
BA_ "SPN" SG_ 2365160446 ErDD3PwrEltrnsTmprtr 24194;
BA_ "SPN" SG_ 2365160446 ErDcDc3CoolantInTemperature 24195;
BA_ "SPN" SG_ 2365160446 ErDcDc3CoolantOutTemperature 24196;
BA_ "SPN" SG_ 2566487294 ErDD3PrmrSdPwrMnmmLmtSttng 24188;
BA_ "SPN" SG_ 2566487294 ErDD3PrmrSdPwrMxmmLmtSttng 24189;
BA_ "SPN" SG_ 2566487294 ErDD3SndrSdPwrMnmmLmtSttng 24190;
BA_ "SPN" SG_ 2566487294 ErDD3SndrSdPwrMxmmLmtSttng 24191;
BA_ "SPN" SG_ 2566487550 ErDD3PrmrSdCrrntMnmmLmtSttng 24184;
BA_ "SPN" SG_ 2566487550 ErDD3PrmrSdCrrntMxmmLmtSttng 24185;
BA_ "SPN" SG_ 2566487550 ErDD3SndrSdCrrntMnmmLmtSttng 24186;
BA_ "SPN" SG_ 2566487550 ErDD3SndrSdCrrntMxmmLmtSttng 24187;
BA_ "SPN" SG_ 2566487806 ErDD3PrmrSdVltgMnmmLmtSttng 24180;
BA_ "SPN" SG_ 2566487806 ErDD3PrmrSdVltgMxmmLmtSttng 24181;
BA_ "SPN" SG_ 2566487806 ErDD3SndrSdVltgMnmmLmtSttng 24182;
BA_ "SPN" SG_ 2566487806 ErDD3SndrSdVltgMxmmLmtSttng 24183;
BA_ "SPN" SG_ 2365161470 ErDD3CntrllrInptIgntnVltg 24178;
BA_ "SPN" SG_ 2365161470 ErDD3CntrllrInptUnswthdSlVltg 24179;
BA_ "SPN" SG_ 2365161726 ErDcDc3PrimarySidePower 24174;
BA_ "SPN" SG_ 2365161726 ErDcDc3SecondarySidePower 24175;
BA_ "SPN" SG_ 2365161726 ErDD3PrmrSdNgtvTChsssGrndVltg 24176;
BA_ "SPN" SG_ 2365161726 ErDD3SndrSdNgtvTChsssGrndVltg 24177;
BA_ "SPN" SG_ 2365161982 ErDcDc3PrimarySideVoltage 24170;
BA_ "SPN" SG_ 2365161982 ErDcDc3SecondarySideVoltage 24171;
BA_ "SPN" SG_ 2365161982 ErDcDc3PrimarySideCurrent 24172;
BA_ "SPN" SG_ 2365161982 ErDcDc3SecondarySideCurrent 24173;
BA_ "SPN" SG_ 2365162238 ErDcDc3StatusCrc 24153;
BA_ "SPN" SG_ 2365162238 ErDcDc3StatusCounter 24154;
BA_ "SPN" SG_ 2365162238 ErDcDc3OperationalStatus 24155;
BA_ "SPN" SG_ 2365162238 ErDcDc3HvilStatus 24156;
BA_ "SPN" SG_ 2365162238 ErDcDc3LoadshedRequest 24157;
BA_ "SPN" SG_ 2365162238 ErDD3PwrLmtDTPrmrSdCrrntMnmm 24158;
BA_ "SPN" SG_ 2365162238 ErDD3PwrLmtDTPrmrSdCrrntMxmm 24159;
BA_ "SPN" SG_ 2365162238 ErDD3PwrLmtDTSndrSdCrrntMnmm 24160;
BA_ "SPN" SG_ 2365162238 ErDD3PwrLmtDTSndrSdCrrntMxmm 24161;
BA_ "SPN" SG_ 2365162238 ErDD3PwrLmtDTPrmrSdVltgMnmm 24162;
BA_ "SPN" SG_ 2365162238 ErDD3PwrLmtDTPrmrSdVltgMxmm 24163;
BA_ "SPN" SG_ 2365162238 ErDD3PwrLmtDTSndrSdVltgMnmm 24164;
BA_ "SPN" SG_ 2365162238 ErDD3PwrLmtDTSndrSdVltgMxmm 24165;
BA_ "SPN" SG_ 2365162238 ErDD3PwrLmtDTCnvrtrTmprtr 24166;
BA_ "SPN" SG_ 2365162238 ErDD3PwrLmtDTEltrnFltrTmprtr 24167;
BA_ "SPN" SG_ 2365162238 ErDD3PwrLmtDTPwrEltrnsTmprtr 24168;
BA_ "SPN" SG_ 2365162238 ErDD3PwrLmtDTUndfndRsn 24169;
